VERSION "created by canmatrix"

NS_ :

BS_:

BU_: RadarFrontCenter VideoFrontCenter RadarFrontLeft RadarFrontRight ReceiveECU

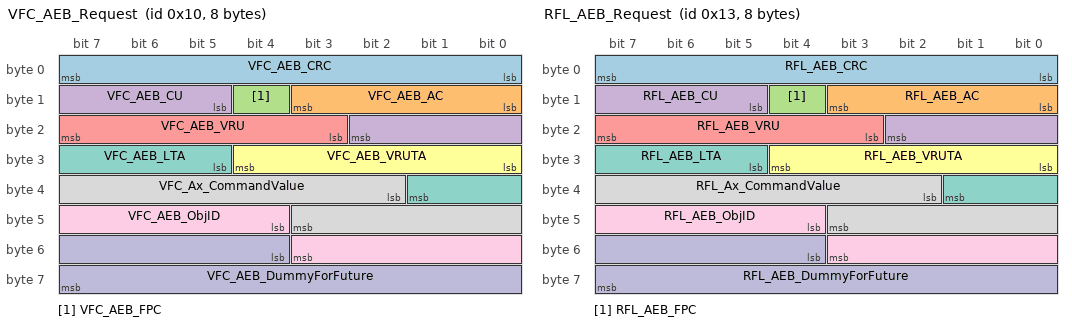
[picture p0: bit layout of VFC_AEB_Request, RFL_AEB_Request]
BO_ 16 VFC_AEB_Request: 8 VideoFrontCenter
 SG_ VFC_AEB_CRC : 0|8@1+ (1,0) [0|255] ""  ReceiveECU
 SG_ VFC_AEB_AC : 8|4@1+ (1,0) [0|15] ""  ReceiveECU
 SG_ VFC_AEB_FPC : 12|1@1+ (1,0) [0|1] ""  ReceiveECU
 SG_ VFC_AEB_CU : 13|6@1+ (1,0) [0|63] ""  ReceiveECU
 SG_ VFC_AEB_VRU : 19|5@1+ (1,0) [0|31] ""  ReceiveECU
 SG_ VFC_AEB_VRUTA : 24|5@1+ (1,0) [0|31] ""  ReceiveECU
 SG_ VFC_AEB_LTA : 29|5@1+ (1,0) [0|31] ""  ReceiveECU
 SG_ VFC_Ax_CommandValue : 34|10@1+ (0.024,-20.016) [-20.016|4.536] "m/s^2"  ReceiveECU
 SG_ VFC_AEB_ObjID : 44|8@1+ (1,0) [0|255] ""  ReceiveECU
 SG_ VFC_AEB_DummyForFuture : 52|12@1+ (1,0) [0|4095] ""  ReceiveECU

BO_ 19 RFL_AEB_Request: 8 RadarFrontLeft
 SG_ RFL_AEB_CRC : 0|8@1+ (1,0) [0|255] ""  VideoFrontCenter
 SG_ RFL_AEB_AC : 8|4@1+ (1,0) [0|15] ""  VideoFrontCenter
 SG_ RFL_AEB_FPC : 12|1@1+ (1,0) [0|1] ""  VideoFrontCenter
 SG_ RFL_AEB_CU : 13|6@1+ (1,0) [0|63] ""  VideoFrontCenter
 SG_ RFL_AEB_VRU : 19|5@1+ (1,0) [0|31] ""  VideoFrontCenter
 SG_ RFL_AEB_VRUTA : 24|5@1+ (1,0) [0|31] ""  VideoFrontCenter
 SG_ RFL_AEB_LTA : 29|5@1+ (1,0) [0|31] ""  VideoFrontCenter
 SG_ RFL_Ax_CommandValue : 34|10@1+ (0.024,-20.016) [-20.016|4.536] "m/s^2"  VideoFrontCenter
 SG_ RFL_AEB_ObjID : 44|8@1+ (1,0) [0|255] ""  VideoFrontCenter
 SG_ RFL_AEB_DummyForFuture : 52|12@1+ (1,0) [0|4095] ""  VideoFrontCenter

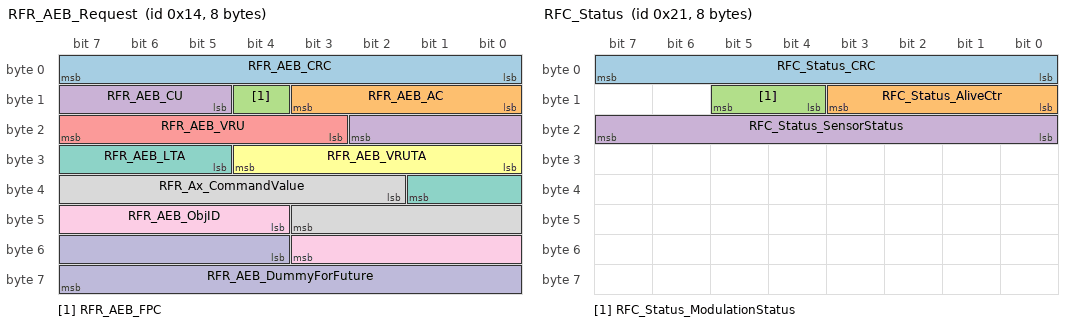
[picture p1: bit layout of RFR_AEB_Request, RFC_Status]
BO_ 20 RFR_AEB_Request: 8 RadarFrontRight
 SG_ RFR_AEB_CRC : 0|8@1+ (1,0) [0|255] ""  VideoFrontCenter
 SG_ RFR_AEB_AC : 8|4@1+ (1,0) [0|15] ""  VideoFrontCenter
 SG_ RFR_AEB_FPC : 12|1@1+ (1,0) [0|1] ""  VideoFrontCenter
 SG_ RFR_AEB_CU : 13|6@1+ (1,0) [0|63] ""  VideoFrontCenter
 SG_ RFR_AEB_VRU : 19|5@1+ (1,0) [0|31] ""  VideoFrontCenter
 SG_ RFR_AEB_VRUTA : 24|5@1+ (1,0) [0|31] ""  VideoFrontCenter
 SG_ RFR_AEB_LTA : 29|5@1+ (1,0) [0|31] ""  VideoFrontCenter
 SG_ RFR_Ax_CommandValue : 34|10@1+ (0.024,-20.016) [-20.016|4.536] "m/s^2"  VideoFrontCenter
 SG_ RFR_AEB_ObjID : 44|8@1+ (1,0) [0|255] ""  VideoFrontCenter
 SG_ RFR_AEB_DummyForFuture : 52|12@1+ (1,0) [0|4095] ""  VideoFrontCenter

BO_ 32 VFC_Status: 20 VideoFrontCenter
 SG_ VFC_Status_CRC : 0|16@1+ (1,0) [0|65535] ""  RadarFrontLeft,RadarFrontRight
 SG_ VFC_Status_AliveCtr : 16|8@1+ (1,0) [0|255] ""  RadarFrontLeft,RadarFrontRight
 SG_ VFC_Status_SensorOrientYaw : 24|10@1+ (0.0005,-0.256) [-0.256|0.2555] "rad"  RadarFrontLeft,RadarFrontRight
 SG_ VFC_Status_SensorOrientPitch : 34|10@1+ (0.0005,-0.256) [-0.256|0.2555] "rad"  RadarFrontLeft,RadarFrontRight
 SG_ VFC_Status_SensorOrientRoll : 44|10@1+ (0.0005,-0.256) [-0.256|0.2555] "rad"  RadarFrontLeft,RadarFrontRight
 SG_ VFC_Status_TimeStampStatus : 56|8@1+ (1,0) [0|255] ""  RadarFrontLeft,RadarFrontRight
 SG_ VFC_Status_TimeStamp : 64|26@1+ (1,0) [0|67108863] "ms"  RadarFrontLeft,RadarFrontRight
 SG_ VFC_Status_FrameNumber : 96|16@1+ (1,0) [0|65535] ""  RadarFrontLeft,RadarFrontRight
 SG_ VFC_Status_SensorOriginPointX : 112|13@1+ (0.001,-4.096) [-4.096|4.095] "m"  RadarFrontLeft,RadarFrontRight
 SG_ VFC_Status_SensorOriginPointY : 125|12@1+ (0.001,-2.048) [-2.048|2.047] "m"  RadarFrontLeft,RadarFrontRight
 SG_ VFC_Status_SensorOriginPointZ : 137|13@1+ (0.001,0) [0|5] "m"  RadarFrontLeft,RadarFrontRight
 SG_ VFC_Status_RollerBenchState : 150|2@1+ (1,0) [0|3] ""  RadarFrontLeft,RadarFrontRight
 SG_ VFC_Status_SensorState : 152|4@1+ (1,0) [0|15] ""  RadarFrontLeft,RadarFrontRight
 SG_ VFC_Status_CalibrationState : 156|3@1+ (1,0) [0|7] ""  RadarFrontLeft,RadarFrontRight
 SG_ VFC_Status_TrafficFlowType : 159|1@1+ (1,0) [0|1] ""  RadarFrontLeft,RadarFrontRight

BO_ 33 RFC_Status: 8 RadarFrontCenter
 SG_ RFC_Status_CRC : 0|8@1+ (1,0) [0|255] ""  VideoFrontCenter,RadarFrontLeft,RadarFrontRight
 SG_ RFC_Status_AliveCtr : 8|4@1+ (1,0) [0|15] ""  VideoFrontCenter,RadarFrontLeft,RadarFrontRight
 SG_ RFC_Status_ModulationStatus : 12|2@1+ (1,0) [0|3] ""  VideoFrontCenter,RadarFrontLeft,RadarFrontRight
 SG_ RFC_Status_SensorStatus : 16|8@1+ (1,0) [0|255] ""  VideoFrontCenter,RadarFrontLeft,RadarFrontRight

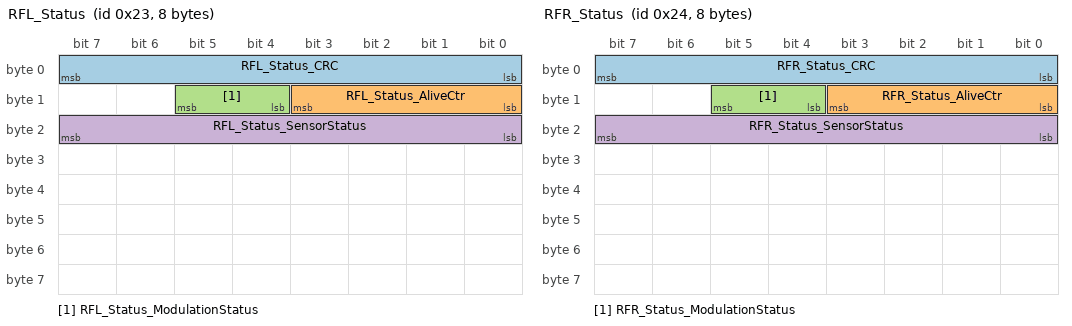
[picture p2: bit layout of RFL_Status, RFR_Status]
BO_ 35 RFL_Status: 8 RadarFrontLeft
 SG_ RFL_Status_CRC : 0|8@1+ (1,0) [0|255] ""  VideoFrontCenter,RadarFrontRight
 SG_ RFL_Status_AliveCtr : 8|4@1+ (1,0) [0|15] ""  VideoFrontCenter,RadarFrontRight
 SG_ RFL_Status_ModulationStatus : 12|2@1+ (1,0) [0|3] ""  VideoFrontCenter,RadarFrontRight
 SG_ RFL_Status_SensorStatus : 16|8@1+ (1,0) [0|255] ""  VideoFrontCenter,RadarFrontRight

BO_ 36 RFR_Status: 8 RadarFrontRight
 SG_ RFR_Status_CRC : 0|8@1+ (1,0) [0|255] ""  VideoFrontCenter,RadarFrontLeft
 SG_ RFR_Status_AliveCtr : 8|4@1+ (1,0) [0|15] ""  VideoFrontCenter,RadarFrontLeft
 SG_ RFR_Status_ModulationStatus : 12|2@1+ (1,0) [0|3] ""  VideoFrontCenter,RadarFrontLeft
 SG_ RFR_Status_SensorStatus : 16|8@1+ (1,0) [0|255] ""  VideoFrontCenter,RadarFrontLeft

BO_ 404 RFC_ObjHdr: 48 RadarFrontCenter
 SG_ RFC_ObjHdr_CRC : 0|16@1+ (1,0) [0|65535] ""  VideoFrontCenter
 SG_ RFC_ObjHdr_AliveCtr : 16|8@1+ (1,0) [0|255] ""  VideoFrontCenter
 SG_ RFC_ObjHdr_ProtBlockCtr : 24|4@1+ (1,0) [0|15] ""  VideoFrontCenter
 SG_ RFC_ObjHdr_IfVersionIdMajor : 32|8@1+ (1,0) [0|255] ""  VideoFrontCenter
 SG_ RFC_ObjHdr_IfVersionIdMinor : 40|8@1+ (1,0) [0|255] ""  VideoFrontCenter
 SG_ RFC_ObjHdr_NumValidObjects : 48|6@1+ (1,0) [0|40] ""  VideoFrontCenter
 SG_ RFC_ObjHdr_TimeStampStatus : 56|8@1+ (1,0) [0|255] ""  VideoFrontCenter
 SG_ RFC_ObjHdr_TimeStamp : 64|26@1+ (1,0) [0|67108863] "ms"  VideoFrontCenter
 SG_ RFC_ObjHdr_SensorState : 96|8@1+ (1,0) [0|255] ""  VideoFrontCenter
 SG_ RFC_ObjHdr_AziOutOfSpec : 109|1@1+ (1,0) [0|1] ""  VideoFrontCenter
 SG_ RFC_ObjHdr_ElevOutOfSpec : 110|1@1+ (1,0) [0|1] ""  VideoFrontCenter
 SG_ RFC_ObjHdr_ObjectDownSel : 111|1@1+ (1,0) [0|1] ""  VideoFrontCenter
 SG_ RFC_ObjHdr_SensorOriginPointY : 112|8@1+ (0.01,-1.28) [-1.28|1.27] "m"  VideoFrontCenter
 SG_ RFC_ObjHdr_SensorOriginPointX : 120|9@1+ (0.02,-5.12) [-5.12|5.1] "m"  VideoFrontCenter
 SG_ RFC_ObjHdr_SensorOriginPointZ : 129|5@1+ (0.05,0) [0|1.55] "m"  VideoFrontCenter
 SG_ RFC_ObjHdr_SensorOrientYaw : 136|16@1+ (0.00017,-5.57056) [-3.2|3.2] "rad"  VideoFrontCenter
 SG_ RFC_ObjHdr_SensorOrientPitch : 152|12@1+ (0.00017,-0.34816) [-0.34816|0.34799] "rad"  VideoFrontCenter
 SG_ RFC_ObjHdr_SensorOrientRoll : 164|12@1+ (0.00017,-0.34816) [-0.2|0.2] "rad"  VideoFrontCenter
 SG_ RFC_ObjHdr_FovAzimuthBegin : 176|15@1+ (0.00017,-2.78528) [-1.6|1.6] "rad"  VideoFrontCenter
 SG_ RFC_ObjHdr_FovAzimuthEnd : 192|15@1+ (0.00017,-2.78528) [-1.6|1.6] "rad"  VideoFrontCenter
 SG_ RFC_ObjHdr_FovElevationBegin : 208|12@1+ (0.00017,-0.34816) [-0.34816|0.34799] "rad"  VideoFrontCenter
 SG_ RFC_ObjHdr_FovElevationEnd : 220|12@1+ (0.00017,-0.34816) [-0.34816|0.34799] "rad"  VideoFrontCenter
 SG_ RFC_ObjHdr_DetectionRange : 232|9@1+ (1,0) [0|511] "m"  VideoFrontCenter
 SG_ RFC_ObjHdr_TimeStampLocal : 248|26@1+ (1,0) [0|67108863] "ms"  VideoFrontCenter

BO_ 406 RFC_Obj00: 64 RadarFrontCenter
 SG_ RFC_Obj00_CRC : 0|16@1+ (1,0) [0|65535] ""  VideoFrontCenter
 SG_ RFC_Obj00_AliveCtr : 16|8@1+ (1,0) [0|255] ""  VideoFrontCenter
 SG_ RFC_Obj00_ProtBlockCtr : 24|4@1+ (1,0) [0|15] ""  VideoFrontCenter
 SG_ RFC_Obj00_ReferencePoint : 28|4@1+ (1,0) [0|15] ""  VideoFrontCenter
 SG_ RFC_Obj00_ObjId : 32|7@1+ (1,0) [0|127] ""  VideoFrontCenter
 SG_ RFC_Obj00_MeasurementStatus : 39|1@1+ (1,0) [0|1] ""  VideoFrontCenter
 SG_ RFC_Obj00_Px : 40|13@1+ (0.0625,-256) [-256|255.9375] "m"  VideoFrontCenter
 SG_ RFC_Obj00_Py : 53|11@1+ (0.125,-128) [-128|127.875] "m"  VideoFrontCenter
 SG_ RFC_Obj00_PxVnce : 64|12@1+ (0.01,0) [0|30] "m^2"  VideoFrontCenter
 SG_ RFC_Obj00_PyVnce : 76|12@1+ (0.01,0) [0|30] "m^2"  VideoFrontCenter
 SG_ RFC_Obj00_Vx : 88|12@1+ (0.0625,-128) [-128|127.9375] "m/s"  VideoFrontCenter
 SG_ RFC_Obj00_Vy : 100|10@1+ (0.125,-64) [-64|63.875] "m/s"  VideoFrontCenter
 SG_ RFC_Obj00_Ax : 110|10@1+ (0.03125,-16) [-16|15.96875] "m/s^2"  VideoFrontCenter
 SG_ RFC_Obj00_Ay : 120|9@1+ (0.0625,-16) [-16|15.9375] "m/s^2"  VideoFrontCenter
 SG_ RFC_Obj00_OrientationYaw : 129|9@1+ (0.0175,-4.48) [-3.15|3.15] "rad"  VideoFrontCenter
 SG_ RFC_Obj00_ExistProb : 138|6@1+ (2,0) [0|100] "%"  VideoFrontCenter
 SG_ RFC_Obj00_VxVnce : 144|12@1+ (0.01,0) [0|30] "m^2/s^2"  VideoFrontCenter
 SG_ RFC_Obj00_VyVnce : 156|12@1+ (0.01,0) [0|30] "m^2/s^2"  VideoFrontCenter
 SG_ RFC_Obj00_AxVnce : 168|12@1+ (0.01,0) [0|30] "m^2/s^4"  VideoFrontCenter
 SG_ RFC_Obj00_AyVnce : 180|12@1+ (0.01,0) [0|30] "m^2/s^4"  VideoFrontCenter
 SG_ RFC_Obj00_OrientationYawVnce : 192|12@1+ (0.0003,0) [0|1] "rad^2"  VideoFrontCenter
 SG_ RFC_Obj00_MovingObserved : 204|6@1+ (2,0) [0|100] "%"  VideoFrontCenter
 SG_ RFC_Obj00_MovingProbability : 210|6@1+ (2,0) [0|100] "%"  VideoFrontCenter
 SG_ RFC_Obj00_Length : 216|7@1+ (0.125,0) [0|15.875] "m"  VideoFrontCenter
 SG_ RFC_Obj00_Valid : 223|1@1+ (1,0) [0|1] ""  VideoFrontCenter
 SG_ RFC_Obj00_LengthVnce : 224|12@1+ (0.01,0) [0|30] "m^2"  VideoFrontCenter
 SG_ RFC_Obj00_WidthVnce : 236|12@1+ (0.01,0) [0|30] "m^2"  VideoFrontCenter
 SG_ RFC_Obj00_Width : 248|7@1+ (0.125,0) [0|15.875] "m"  VideoFrontCenter
 SG_ RFC_Obj00_BehaviorType : 255|3@1+ (1,0) [0|7] ""  VideoFrontCenter
 SG_ RFC_Obj00_ObstacleConf : 258|6@1+ (2,0) [0|100] "%"  VideoFrontCenter
 SG_ RFC_Obj00_NonObstacleConf : 264|6@1+ (2,0) [0|100] "%"  VideoFrontCenter
 SG_ RFC_Obj00_PxPyCoVnce : 272|12@1+ (0.01,0) [0|30] "m^2"  VideoFrontCenter
 SG_ RFC_Obj00_PxVxCoVnce : 284|12@1+ (0.01,0) [0|30] "m^2/s"  VideoFrontCenter
 SG_ RFC_Obj00_PxVyCoVnce : 296|12@1+ (0.01,0) [0|30] "m^2/s"  VideoFrontCenter
 SG_ RFC_Obj00_PyVxCoVnce : 308|12@1+ (0.01,0) [0|30] "m^2/s"  VideoFrontCenter
 SG_ RFC_Obj00_PyVyCoVnce : 320|12@1+ (0.01,0) [0|30] "m^2/s"  VideoFrontCenter
 SG_ RFC_Obj00_VxVyCoVnce : 332|12@1+ (0.01,0) [0|30] "m^2/s^2"  VideoFrontCenter
 SG_ RFC_Obj00_PxAxCoVnce : 344|12@1+ (0.01,0) [0|30] "m^2/s^2"  VideoFrontCenter
 SG_ RFC_Obj00_PxAyCoVnce : 356|12@1+ (0.01,0) [0|30] "m^2/s^2"  VideoFrontCenter
 SG_ RFC_Obj00_PyAxCoVnce : 368|12@1+ (0.01,0) [0|30] "m^2/s^2"  VideoFrontCenter
 SG_ RFC_Obj00_PyAyCoVnce : 380|12@1+ (0.01,0) [0|30] "m^2/s^2"  VideoFrontCenter
 SG_ RFC_Obj00_VxAxCoVnce : 392|12@1+ (0.01,0) [0|30] "m^2/s^3"  VideoFrontCenter
 SG_ RFC_Obj00_VxAyCoVnce : 404|12@1+ (0.01,0) [0|30] "m^2/s^3"  VideoFrontCenter
 SG_ RFC_Obj00_VyAxCoVnce : 416|12@1+ (0.01,0) [0|30] "m^2/s^3"  VideoFrontCenter
 SG_ RFC_Obj00_VyAyCoVnce : 428|12@1+ (0.01,0) [0|30] "m^2/s^3"  VideoFrontCenter
 SG_ RFC_Obj00_AxAyCoVnce : 440|12@1+ (0.01,0) [0|30] "m^2/s^4"  VideoFrontCenter
 SG_ RFC_Obj00_MobileObstConf : 452|6@1+ (2,0) [0|100] "%"  VideoFrontCenter
 SG_ RFC_Obj00_Mob4PlusWhlConf : 458|6@1+ (2,0) [0|100] "%"  VideoFrontCenter
 SG_ RFC_Obj00_Mob2WhlConf : 464|6@1+ (2,0) [0|100] "%"  VideoFrontCenter
 SG_ RFC_Obj00_MobPedConf : 470|6@1+ (2,0) [0|100] "%"  VideoFrontCenter
 SG_ RFC_Obj00_FourPlusWhlCarConf : 476|6@1+ (2,0) [0|100] "%"  VideoFrontCenter
 SG_ RFC_Obj00_FourPlusWhlHGVConf : 482|6@1+ (2,0) [0|100] "%"  VideoFrontCenter
 SG_ RFC_Obj00_GroundReflexConf : 488|6@1+ (2,0) [0|100] "%"  VideoFrontCenter
 SG_ RFC_Obj00_StatObstConf : 494|6@1+ (2,0) [0|100] "%"  VideoFrontCenter
 SG_ RFC_Obj00_StatBarrierConf : 500|6@1+ (2,0) [0|100] "%"  VideoFrontCenter

BO_ 407 RFC_Obj01: 64 RadarFrontCenter
 SG_ RFC_Obj01_CRC : 0|16@1+ (1,0) [0|65535] ""  VideoFrontCenter
 SG_ RFC_Obj01_AliveCtr : 16|8@1+ (1,0) [0|255] ""  VideoFrontCenter
 SG_ RFC_Obj01_ProtBlockCtr : 24|4@1+ (1,0) [0|15] ""  VideoFrontCenter
 SG_ RFC_Obj01_ReferencePoint : 28|4@1+ (1,0) [0|15] ""  VideoFrontCenter
 SG_ RFC_Obj01_ObjId : 32|7@1+ (1,0) [0|127] ""  VideoFrontCenter
 SG_ RFC_Obj01_MeasurementStatus : 39|1@1+ (1,0) [0|1] ""  VideoFrontCenter
 SG_ RFC_Obj01_Px : 40|13@1+ (0.0625,-256) [-256|255.9375] "m"  VideoFrontCenter
 SG_ RFC_Obj01_Py : 53|11@1+ (0.125,-128) [-128|127.875] "m"  VideoFrontCenter
 SG_ RFC_Obj01_PxVnce : 64|12@1+ (0.01,0) [0|30] "m^2"  VideoFrontCenter
 SG_ RFC_Obj01_PyVnce : 76|12@1+ (0.01,0) [0|30] "m^2"  VideoFrontCenter
 SG_ RFC_Obj01_Vx : 88|12@1+ (0.0625,-128) [-128|127.9375] "m/s"  VideoFrontCenter
 SG_ RFC_Obj01_Vy : 100|10@1+ (0.125,-64) [-64|63.875] "m/s"  VideoFrontCenter
 SG_ RFC_Obj01_Ax : 110|10@1+ (0.03125,-16) [-16|15.96875] "m/s^2"  VideoFrontCenter
 SG_ RFC_Obj01_Ay : 120|9@1+ (0.0625,-16) [-16|15.9375] "m/s^2"  VideoFrontCenter
 SG_ RFC_Obj01_OrientationYaw : 129|9@1+ (0.0175,-4.48) [-3.15|3.15] "rad"  VideoFrontCenter
 SG_ RFC_Obj01_ExistProb : 138|6@1+ (2,0) [0|100] "%"  VideoFrontCenter
 SG_ RFC_Obj01_VxVnce : 144|12@1+ (0.01,0) [0|30] "m^2/s^2"  VideoFrontCenter
 SG_ RFC_Obj01_VyVnce : 156|12@1+ (0.01,0) [0|30] "m^2/s^2"  VideoFrontCenter
 SG_ RFC_Obj01_AxVnce : 168|12@1+ (0.01,0) [0|30] "m^2/s^4"  VideoFrontCenter
 SG_ RFC_Obj01_AyVnce : 180|12@1+ (0.01,0) [0|30] "m^2/s^4"  VideoFrontCenter
 SG_ RFC_Obj01_OrientationYawVnce : 192|12@1+ (0.0003,0) [0|1] "rad^2"  VideoFrontCenter
 SG_ RFC_Obj01_MovingObserved : 204|6@1+ (2,0) [0|100] "%"  VideoFrontCenter
 SG_ RFC_Obj01_MovingProbability : 210|6@1+ (2,0) [0|100] "%"  VideoFrontCenter
 SG_ RFC_Obj01_Length : 216|7@1+ (0.125,0) [0|15.875] "m"  VideoFrontCenter
 SG_ RFC_Obj01_Valid : 223|1@1+ (1,0) [0|1] ""  VideoFrontCenter
 SG_ RFC_Obj01_LengthVnce : 224|12@1+ (0.01,0) [0|30] "m^2"  VideoFrontCenter
 SG_ RFC_Obj01_WidthVnce : 236|12@1+ (0.01,0) [0|30] "m^2"  VideoFrontCenter
 SG_ RFC_Obj01_Width : 248|7@1+ (0.125,0) [0|15.875] "m"  VideoFrontCenter
 SG_ RFC_Obj01_BehaviorType : 255|3@1+ (1,0) [0|7] ""  VideoFrontCenter
 SG_ RFC_Obj01_ObstacleConf : 258|6@1+ (2,0) [0|100] "%"  VideoFrontCenter
 SG_ RFC_Obj01_NonObstacleConf : 264|6@1+ (2,0) [0|100] "%"  VideoFrontCenter
 SG_ RFC_Obj01_PxPyCoVnce : 272|12@1+ (0.01,0) [0|30] "m^2"  VideoFrontCenter
 SG_ RFC_Obj01_PxVxCoVnce : 284|12@1+ (0.01,0) [0|30] "m^2/s"  VideoFrontCenter
 SG_ RFC_Obj01_PxVyCoVnce : 296|12@1+ (0.01,0) [0|30] "m^2/s"  VideoFrontCenter
 SG_ RFC_Obj01_PyVxCoVnce : 308|12@1+ (0.01,0) [0|30] "m^2/s"  VideoFrontCenter
 SG_ RFC_Obj01_PyVyCoVnce : 320|12@1+ (0.01,0) [0|30] "m^2/s"  VideoFrontCenter
 SG_ RFC_Obj01_VxVyCoVnce : 332|12@1+ (0.01,0) [0|30] "m^2/s^2"  VideoFrontCenter
 SG_ RFC_Obj01_PxAxCoVnce : 344|12@1+ (0.01,0) [0|30] "m^2/s^2"  VideoFrontCenter
 SG_ RFC_Obj01_PxAyCoVnce : 356|12@1+ (0.01,0) [0|30] "m^2/s^2"  VideoFrontCenter
 SG_ RFC_Obj01_PyAxCoVnce : 368|12@1+ (0.01,0) [0|30] "m^2/s^2"  VideoFrontCenter
 SG_ RFC_Obj01_PyAyCoVnce : 380|12@1+ (0.01,0) [0|30] "m^2/s^2"  VideoFrontCenter
 SG_ RFC_Obj01_VxAxCoVnce : 392|12@1+ (0.01,0) [0|30] "m^2/s^3"  VideoFrontCenter
 SG_ RFC_Obj01_VxAyCoVnce : 404|12@1+ (0.01,0) [0|30] "m^2/s^3"  VideoFrontCenter
 SG_ RFC_Obj01_VyAxCoVnce : 416|12@1+ (0.01,0) [0|30] "m^2/s^3"  VideoFrontCenter
 SG_ RFC_Obj01_VyAyCoVnce : 428|12@1+ (0.01,0) [0|30] "m^2/s^3"  VideoFrontCenter
 SG_ RFC_Obj01_AxAyCoVnce : 440|12@1+ (0.01,0) [0|30] "m^2/s^4"  VideoFrontCenter
 SG_ RFC_Obj01_MobileObstConf : 452|6@1+ (2,0) [0|100] "%"  VideoFrontCenter
 SG_ RFC_Obj01_Mob4PlusWhlConf : 458|6@1+ (2,0) [0|100] "%"  VideoFrontCenter
 SG_ RFC_Obj01_Mob2WhlConf : 464|6@1+ (2,0) [0|100] "%"  VideoFrontCenter
 SG_ RFC_Obj01_MobPedConf : 470|6@1+ (2,0) [0|100] "%"  VideoFrontCenter
 SG_ RFC_Obj01_FourPlusWhlCarConf : 476|6@1+ (2,0) [0|100] "%"  VideoFrontCenter
 SG_ RFC_Obj01_FourPlusWhlHGVConf : 482|6@1+ (2,0) [0|100] "%"  VideoFrontCenter
 SG_ RFC_Obj01_GroundReflexConf : 488|6@1+ (2,0) [0|100] "%"  VideoFrontCenter
 SG_ RFC_Obj01_StatObstConf : 494|6@1+ (2,0) [0|100] "%"  VideoFrontCenter
 SG_ RFC_Obj01_StatBarrierConf : 500|6@1+ (2,0) [0|100] "%"  VideoFrontCenter

BO_ 408 RFC_Obj02: 64 RadarFrontCenter
 SG_ RFC_Obj02_CRC : 0|16@1+ (1,0) [0|65535] ""  VideoFrontCenter
 SG_ RFC_Obj02_AliveCtr : 16|8@1+ (1,0) [0|255] ""  VideoFrontCenter
 SG_ RFC_Obj02_ProtBlockCtr : 24|4@1+ (1,0) [0|15] ""  VideoFrontCenter
 SG_ RFC_Obj02_ReferencePoint : 28|4@1+ (1,0) [0|15] ""  VideoFrontCenter
 SG_ RFC_Obj02_ObjId : 32|7@1+ (1,0) [0|127] ""  VideoFrontCenter
 SG_ RFC_Obj02_MeasurementStatus : 39|1@1+ (1,0) [0|1] ""  VideoFrontCenter
 SG_ RFC_Obj02_Px : 40|13@1+ (0.0625,-256) [-256|255.9375] "m"  VideoFrontCenter
 SG_ RFC_Obj02_Py : 53|11@1+ (0.125,-128) [-128|127.875] "m"  VideoFrontCenter
 SG_ RFC_Obj02_PxVnce : 64|12@1+ (0.01,0) [0|30] "m^2"  VideoFrontCenter
 SG_ RFC_Obj02_PyVnce : 76|12@1+ (0.01,0) [0|30] "m^2"  VideoFrontCenter
 SG_ RFC_Obj02_Vx : 88|12@1+ (0.0625,-128) [-128|127.9375] "m/s"  VideoFrontCenter
 SG_ RFC_Obj02_Vy : 100|10@1+ (0.125,-64) [-64|63.875] "m/s"  VideoFrontCenter
 SG_ RFC_Obj02_Ax : 110|10@1+ (0.03125,-16) [-16|15.96875] "m/s^2"  VideoFrontCenter
 SG_ RFC_Obj02_Ay : 120|9@1+ (0.0625,-16) [-16|15.9375] "m/s^2"  VideoFrontCenter
 SG_ RFC_Obj02_OrientationYaw : 129|9@1+ (0.0175,-4.48) [-3.15|3.15] "rad"  VideoFrontCenter
 SG_ RFC_Obj02_ExistProb : 138|6@1+ (2,0) [0|100] "%"  VideoFrontCenter
 SG_ RFC_Obj02_VxVnce : 144|12@1+ (0.01,0) [0|30] "m^2/s^2"  VideoFrontCenter
 SG_ RFC_Obj02_VyVnce : 156|12@1+ (0.01,0) [0|30] "m^2/s^2"  VideoFrontCenter
 SG_ RFC_Obj02_AxVnce : 168|12@1+ (0.01,0) [0|30] "m^2/s^4"  VideoFrontCenter
 SG_ RFC_Obj02_AyVnce : 180|12@1+ (0.01,0) [0|30] "m^2/s^4"  VideoFrontCenter
 SG_ RFC_Obj02_OrientationYawVnce : 192|12@1+ (0.0003,0) [0|1] "rad^2"  VideoFrontCenter
 SG_ RFC_Obj02_MovingObserved : 204|6@1+ (2,0) [0|100] "%"  VideoFrontCenter
 SG_ RFC_Obj02_MovingProbability : 210|6@1+ (2,0) [0|100] "%"  VideoFrontCenter
 SG_ RFC_Obj02_Length : 216|7@1+ (0.125,0) [0|15.875] "m"  VideoFrontCenter
 SG_ RFC_Obj02_Valid : 223|1@1+ (1,0) [0|1] ""  VideoFrontCenter
 SG_ RFC_Obj02_LengthVnce : 224|12@1+ (0.01,0) [0|30] "m^2"  VideoFrontCenter
 SG_ RFC_Obj02_WidthVnce : 236|12@1+ (0.01,0) [0|30] "m^2"  VideoFrontCenter
 SG_ RFC_Obj02_Width : 248|7@1+ (0.125,0) [0|15.875] "m"  VideoFrontCenter
 SG_ RFC_Obj02_BehaviorType : 255|3@1+ (1,0) [0|7] ""  VideoFrontCenter
 SG_ RFC_Obj02_ObstacleConf : 258|6@1+ (2,0) [0|100] "%"  VideoFrontCenter
 SG_ RFC_Obj02_NonObstacleConf : 264|6@1+ (2,0) [0|100] "%"  VideoFrontCenter
 SG_ RFC_Obj02_PxPyCoVnce : 272|12@1+ (0.01,0) [0|30] "m^2"  VideoFrontCenter
 SG_ RFC_Obj02_PxVxCoVnce : 284|12@1+ (0.01,0) [0|30] "m^2/s"  VideoFrontCenter
 SG_ RFC_Obj02_PxVyCoVnce : 296|12@1+ (0.01,0) [0|30] "m^2/s"  VideoFrontCenter
 SG_ RFC_Obj02_PyVxCoVnce : 308|12@1+ (0.01,0) [0|30] "m^2/s"  VideoFrontCenter
 SG_ RFC_Obj02_PyVyCoVnce : 320|12@1+ (0.01,0) [0|30] "m^2/s"  VideoFrontCenter
 SG_ RFC_Obj02_VxVyCoVnce : 332|12@1+ (0.01,0) [0|30] "m^2/s^2"  VideoFrontCenter
 SG_ RFC_Obj02_PxAxCoVnce : 344|12@1+ (0.01,0) [0|30] "m^2/s^2"  VideoFrontCenter
 SG_ RFC_Obj02_PxAyCoVnce : 356|12@1+ (0.01,0) [0|30] "m^2/s^2"  VideoFrontCenter
 SG_ RFC_Obj02_PyAxCoVnce : 368|12@1+ (0.01,0) [0|30] "m^2/s^2"  VideoFrontCenter
 SG_ RFC_Obj02_PyAyCoVnce : 380|12@1+ (0.01,0) [0|30] "m^2/s^2"  VideoFrontCenter
 SG_ RFC_Obj02_VxAxCoVnce : 392|12@1+ (0.01,0) [0|30] "m^2/s^3"  VideoFrontCenter
 SG_ RFC_Obj02_VxAyCoVnce : 404|12@1+ (0.01,0) [0|30] "m^2/s^3"  VideoFrontCenter
 SG_ RFC_Obj02_VyAxCoVnce : 416|12@1+ (0.01,0) [0|30] "m^2/s^3"  VideoFrontCenter
 SG_ RFC_Obj02_VyAyCoVnce : 428|12@1+ (0.01,0) [0|30] "m^2/s^3"  VideoFrontCenter
 SG_ RFC_Obj02_AxAyCoVnce : 440|12@1+ (0.01,0) [0|30] "m^2/s^4"  VideoFrontCenter
 SG_ RFC_Obj02_MobileObstConf : 452|6@1+ (2,0) [0|100] "%"  VideoFrontCenter
 SG_ RFC_Obj02_Mob4PlusWhlConf : 458|6@1+ (2,0) [0|100] "%"  VideoFrontCenter
 SG_ RFC_Obj02_Mob2WhlConf : 464|6@1+ (2,0) [0|100] "%"  VideoFrontCenter
 SG_ RFC_Obj02_MobPedConf : 470|6@1+ (2,0) [0|100] "%"  VideoFrontCenter
 SG_ RFC_Obj02_FourPlusWhlCarConf : 476|6@1+ (2,0) [0|100] "%"  VideoFrontCenter
 SG_ RFC_Obj02_FourPlusWhlHGVConf : 482|6@1+ (2,0) [0|100] "%"  VideoFrontCenter
 SG_ RFC_Obj02_GroundReflexConf : 488|6@1+ (2,0) [0|100] "%"  VideoFrontCenter
 SG_ RFC_Obj02_StatObstConf : 494|6@1+ (2,0) [0|100] "%"  VideoFrontCenter
 SG_ RFC_Obj02_StatBarrierConf : 500|6@1+ (2,0) [0|100] "%"  VideoFrontCenter

BO_ 409 RFC_Obj03: 64 RadarFrontCenter
 SG_ RFC_Obj03_CRC : 0|16@1+ (1,0) [0|65535] ""  VideoFrontCenter
 SG_ RFC_Obj03_AliveCtr : 16|8@1+ (1,0) [0|255] ""  VideoFrontCenter
 SG_ RFC_Obj03_ProtBlockCtr : 24|4@1+ (1,0) [0|15] ""  VideoFrontCenter
 SG_ RFC_Obj03_ReferencePoint : 28|4@1+ (1,0) [0|15] ""  VideoFrontCenter
 SG_ RFC_Obj03_ObjId : 32|7@1+ (1,0) [0|127] ""  VideoFrontCenter
 SG_ RFC_Obj03_MeasurementStatus : 39|1@1+ (1,0) [0|1] ""  VideoFrontCenter
 SG_ RFC_Obj03_Px : 40|13@1+ (0.0625,-256) [-256|255.9375] "m"  VideoFrontCenter
 SG_ RFC_Obj03_Py : 53|11@1+ (0.125,-128) [-128|127.875] "m"  VideoFrontCenter
 SG_ RFC_Obj03_PxVnce : 64|12@1+ (0.01,0) [0|30] "m^2"  VideoFrontCenter
 SG_ RFC_Obj03_PyVnce : 76|12@1+ (0.01,0) [0|30] "m^2"  VideoFrontCenter
 SG_ RFC_Obj03_Vx : 88|12@1+ (0.0625,-128) [-128|127.9375] "m/s"  VideoFrontCenter
 SG_ RFC_Obj03_Vy : 100|10@1+ (0.125,-64) [-64|63.875] "m/s"  VideoFrontCenter
 SG_ RFC_Obj03_Ax : 110|10@1+ (0.03125,-16) [-16|15.96875] "m/s^2"  VideoFrontCenter
 SG_ RFC_Obj03_Ay : 120|9@1+ (0.0625,-16) [-16|15.9375] "m/s^2"  VideoFrontCenter
 SG_ RFC_Obj03_OrientationYaw : 129|9@1+ (0.0175,-4.48) [-3.15|3.15] "rad"  VideoFrontCenter
 SG_ RFC_Obj03_ExistProb : 138|6@1+ (2,0) [0|100] "%"  VideoFrontCenter
 SG_ RFC_Obj03_VxVnce : 144|12@1+ (0.01,0) [0|30] "m^2/s^2"  VideoFrontCenter
 SG_ RFC_Obj03_VyVnce : 156|12@1+ (0.01,0) [0|30] "m^2/s^2"  VideoFrontCenter
 SG_ RFC_Obj03_AxVnce : 168|12@1+ (0.01,0) [0|30] "m^2/s^4"  VideoFrontCenter
 SG_ RFC_Obj03_AyVnce : 180|12@1+ (0.01,0) [0|30] "m^2/s^4"  VideoFrontCenter
 SG_ RFC_Obj03_OrientationYawVnce : 192|12@1+ (0.0003,0) [0|1] "rad^2"  VideoFrontCenter
 SG_ RFC_Obj03_MovingObserved : 204|6@1+ (2,0) [0|100] "%"  VideoFrontCenter
 SG_ RFC_Obj03_MovingProbability : 210|6@1+ (2,0) [0|100] "%"  VideoFrontCenter
 SG_ RFC_Obj03_Length : 216|7@1+ (0.125,0) [0|15.875] "m"  VideoFrontCenter
 SG_ RFC_Obj03_Valid : 223|1@1+ (1,0) [0|1] ""  VideoFrontCenter
 SG_ RFC_Obj03_LengthVnce : 224|12@1+ (0.01,0) [0|30] "m^2"  VideoFrontCenter
 SG_ RFC_Obj03_WidthVnce : 236|12@1+ (0.01,0) [0|30] "m^2"  VideoFrontCenter
 SG_ RFC_Obj03_Width : 248|7@1+ (0.125,0) [0|15.875] "m"  VideoFrontCenter
 SG_ RFC_Obj03_BehaviorType : 255|3@1+ (1,0) [0|7] ""  VideoFrontCenter
 SG_ RFC_Obj03_ObstacleConf : 258|6@1+ (2,0) [0|100] "%"  VideoFrontCenter
 SG_ RFC_Obj03_NonObstacleConf : 264|6@1+ (2,0) [0|100] "%"  VideoFrontCenter
 SG_ RFC_Obj03_PxPyCoVnce : 272|12@1+ (0.01,0) [0|30] "m^2"  VideoFrontCenter
 SG_ RFC_Obj03_PxVxCoVnce : 284|12@1+ (0.01,0) [0|30] "m^2/s"  VideoFrontCenter
 SG_ RFC_Obj03_PxVyCoVnce : 296|12@1+ (0.01,0) [0|30] "m^2/s"  VideoFrontCenter
 SG_ RFC_Obj03_PyVxCoVnce : 308|12@1+ (0.01,0) [0|30] "m^2/s"  VideoFrontCenter
 SG_ RFC_Obj03_PyVyCoVnce : 320|12@1+ (0.01,0) [0|30] "m^2/s"  VideoFrontCenter
 SG_ RFC_Obj03_VxVyCoVnce : 332|12@1+ (0.01,0) [0|30] "m^2/s^2"  VideoFrontCenter
 SG_ RFC_Obj03_PxAxCoVnce : 344|12@1+ (0.01,0) [0|30] "m^2/s^2"  VideoFrontCenter
 SG_ RFC_Obj03_PxAyCoVnce : 356|12@1+ (0.01,0) [0|30] "m^2/s^2"  VideoFrontCenter
 SG_ RFC_Obj03_PyAxCoVnce : 368|12@1+ (0.01,0) [0|30] "m^2/s^2"  VideoFrontCenter
 SG_ RFC_Obj03_PyAyCoVnce : 380|12@1+ (0.01,0) [0|30] "m^2/s^2"  VideoFrontCenter
 SG_ RFC_Obj03_VxAxCoVnce : 392|12@1+ (0.01,0) [0|30] "m^2/s^3"  VideoFrontCenter
 SG_ RFC_Obj03_VxAyCoVnce : 404|12@1+ (0.01,0) [0|30] "m^2/s^3"  VideoFrontCenter
 SG_ RFC_Obj03_VyAxCoVnce : 416|12@1+ (0.01,0) [0|30] "m^2/s^3"  VideoFrontCenter
 SG_ RFC_Obj03_VyAyCoVnce : 428|12@1+ (0.01,0) [0|30] "m^2/s^3"  VideoFrontCenter
 SG_ RFC_Obj03_AxAyCoVnce : 440|12@1+ (0.01,0) [0|30] "m^2/s^4"  VideoFrontCenter
 SG_ RFC_Obj03_MobileObstConf : 452|6@1+ (2,0) [0|100] "%"  VideoFrontCenter
 SG_ RFC_Obj03_Mob4PlusWhlConf : 458|6@1+ (2,0) [0|100] "%"  VideoFrontCenter
 SG_ RFC_Obj03_Mob2WhlConf : 464|6@1+ (2,0) [0|100] "%"  VideoFrontCenter
 SG_ RFC_Obj03_MobPedConf : 470|6@1+ (2,0) [0|100] "%"  VideoFrontCenter
 SG_ RFC_Obj03_FourPlusWhlCarConf : 476|6@1+ (2,0) [0|100] "%"  VideoFrontCenter
 SG_ RFC_Obj03_FourPlusWhlHGVConf : 482|6@1+ (2,0) [0|100] "%"  VideoFrontCenter
 SG_ RFC_Obj03_GroundReflexConf : 488|6@1+ (2,0) [0|100] "%"  VideoFrontCenter
 SG_ RFC_Obj03_StatObstConf : 494|6@1+ (2,0) [0|100] "%"  VideoFrontCenter
 SG_ RFC_Obj03_StatBarrierConf : 500|6@1+ (2,0) [0|100] "%"  VideoFrontCenter

BO_ 410 RFC_Obj04: 64 RadarFrontCenter
 SG_ RFC_Obj04_CRC : 0|16@1+ (1,0) [0|65535] ""  VideoFrontCenter
 SG_ RFC_Obj04_AliveCtr : 16|8@1+ (1,0) [0|255] ""  VideoFrontCenter
 SG_ RFC_Obj04_ProtBlockCtr : 24|4@1+ (1,0) [0|15] ""  VideoFrontCenter
 SG_ RFC_Obj04_ReferencePoint : 28|4@1+ (1,0) [0|15] ""  VideoFrontCenter
 SG_ RFC_Obj04_ObjId : 32|7@1+ (1,0) [0|127] ""  VideoFrontCenter
 SG_ RFC_Obj04_MeasurementStatus : 39|1@1+ (1,0) [0|1] ""  VideoFrontCenter
 SG_ RFC_Obj04_Px : 40|13@1+ (0.0625,-256) [-256|255.9375] "m"  VideoFrontCenter
 SG_ RFC_Obj04_Py : 53|11@1+ (0.125,-128) [-128|127.875] "m"  VideoFrontCenter
 SG_ RFC_Obj04_PxVnce : 64|12@1+ (0.01,0) [0|30] "m^2"  VideoFrontCenter
 SG_ RFC_Obj04_PyVnce : 76|12@1+ (0.01,0) [0|30] "m^2"  VideoFrontCenter
 SG_ RFC_Obj04_Vx : 88|12@1+ (0.0625,-128) [-128|127.9375] "m/s"  VideoFrontCenter
 SG_ RFC_Obj04_Vy : 100|10@1+ (0.125,-64) [-64|63.875] "m/s"  VideoFrontCenter
 SG_ RFC_Obj04_Ax : 110|10@1+ (0.03125,-16) [-16|15.96875] "m/s^2"  VideoFrontCenter
 SG_ RFC_Obj04_Ay : 120|9@1+ (0.0625,-16) [-16|15.9375] "m/s^2"  VideoFrontCenter
 SG_ RFC_Obj04_OrientationYaw : 129|9@1+ (0.0175,-4.48) [-3.15|3.15] "rad"  VideoFrontCenter
 SG_ RFC_Obj04_ExistProb : 138|6@1+ (2,0) [0|100] "%"  VideoFrontCenter
 SG_ RFC_Obj04_VxVnce : 144|12@1+ (0.01,0) [0|30] "m^2/s^2"  VideoFrontCenter
 SG_ RFC_Obj04_VyVnce : 156|12@1+ (0.01,0) [0|30] "m^2/s^2"  VideoFrontCenter
 SG_ RFC_Obj04_AxVnce : 168|12@1+ (0.01,0) [0|30] "m^2/s^4"  VideoFrontCenter
 SG_ RFC_Obj04_AyVnce : 180|12@1+ (0.01,0) [0|30] "m^2/s^4"  VideoFrontCenter
 SG_ RFC_Obj04_OrientationYawVnce : 192|12@1+ (0.0003,0) [0|1] "rad^2"  VideoFrontCenter
 SG_ RFC_Obj04_MovingObserved : 204|6@1+ (2,0) [0|100] "%"  VideoFrontCenter
 SG_ RFC_Obj04_MovingProbability : 210|6@1+ (2,0) [0|100] "%"  VideoFrontCenter
 SG_ RFC_Obj04_Length : 216|7@1+ (0.125,0) [0|15.875] "m"  VideoFrontCenter
 SG_ RFC_Obj04_Valid : 223|1@1+ (1,0) [0|1] ""  VideoFrontCenter
 SG_ RFC_Obj04_LengthVnce : 224|12@1+ (0.01,0) [0|30] "m^2"  VideoFrontCenter
 SG_ RFC_Obj04_WidthVnce : 236|12@1+ (0.01,0) [0|30] "m^2"  VideoFrontCenter
 SG_ RFC_Obj04_Width : 248|7@1+ (0.125,0) [0|15.875] "m"  VideoFrontCenter
 SG_ RFC_Obj04_BehaviorType : 255|3@1+ (1,0) [0|7] ""  VideoFrontCenter
 SG_ RFC_Obj04_ObstacleConf : 258|6@1+ (2,0) [0|100] "%"  VideoFrontCenter
 SG_ RFC_Obj04_NonObstacleConf : 264|6@1+ (2,0) [0|100] "%"  VideoFrontCenter
 SG_ RFC_Obj04_PxPyCoVnce : 272|12@1+ (0.01,0) [0|30] "m^2"  VideoFrontCenter
 SG_ RFC_Obj04_PxVxCoVnce : 284|12@1+ (0.01,0) [0|30] "m^2/s"  VideoFrontCenter
 SG_ RFC_Obj04_PxVyCoVnce : 296|12@1+ (0.01,0) [0|30] "m^2/s"  VideoFrontCenter
 SG_ RFC_Obj04_PyVxCoVnce : 308|12@1+ (0.01,0) [0|30] "m^2/s"  VideoFrontCenter
 SG_ RFC_Obj04_PyVyCoVnce : 320|12@1+ (0.01,0) [0|30] "m^2/s"  VideoFrontCenter
 SG_ RFC_Obj04_VxVyCoVnce : 332|12@1+ (0.01,0) [0|30] "m^2/s^2"  VideoFrontCenter
 SG_ RFC_Obj04_PxAxCoVnce : 344|12@1+ (0.01,0) [0|30] "m^2/s^2"  VideoFrontCenter
 SG_ RFC_Obj04_PxAyCoVnce : 356|12@1+ (0.01,0) [0|30] "m^2/s^2"  VideoFrontCenter
 SG_ RFC_Obj04_PyAxCoVnce : 368|12@1+ (0.01,0) [0|30] "m^2/s^2"  VideoFrontCenter
 SG_ RFC_Obj04_PyAyCoVnce : 380|12@1+ (0.01,0) [0|30] "m^2/s^2"  VideoFrontCenter
 SG_ RFC_Obj04_VxAxCoVnce : 392|12@1+ (0.01,0) [0|30] "m^2/s^3"  VideoFrontCenter
 SG_ RFC_Obj04_VxAyCoVnce : 404|12@1+ (0.01,0) [0|30] "m^2/s^3"  VideoFrontCenter
 SG_ RFC_Obj04_VyAxCoVnce : 416|12@1+ (0.01,0) [0|30] "m^2/s^3"  VideoFrontCenter
 SG_ RFC_Obj04_VyAyCoVnce : 428|12@1+ (0.01,0) [0|30] "m^2/s^3"  VideoFrontCenter
 SG_ RFC_Obj04_AxAyCoVnce : 440|12@1+ (0.01,0) [0|30] "m^2/s^4"  VideoFrontCenter
 SG_ RFC_Obj04_MobileObstConf : 452|6@1+ (2,0) [0|100] "%"  VideoFrontCenter
 SG_ RFC_Obj04_Mob4PlusWhlConf : 458|6@1+ (2,0) [0|100] "%"  VideoFrontCenter
 SG_ RFC_Obj04_Mob2WhlConf : 464|6@1+ (2,0) [0|100] "%"  VideoFrontCenter
 SG_ RFC_Obj04_MobPedConf : 470|6@1+ (2,0) [0|100] "%"  VideoFrontCenter
 SG_ RFC_Obj04_FourPlusWhlCarConf : 476|6@1+ (2,0) [0|100] "%"  VideoFrontCenter
 SG_ RFC_Obj04_FourPlusWhlHGVConf : 482|6@1+ (2,0) [0|100] "%"  VideoFrontCenter
 SG_ RFC_Obj04_GroundReflexConf : 488|6@1+ (2,0) [0|100] "%"  VideoFrontCenter
 SG_ RFC_Obj04_StatObstConf : 494|6@1+ (2,0) [0|100] "%"  VideoFrontCenter
 SG_ RFC_Obj04_StatBarrierConf : 500|6@1+ (2,0) [0|100] "%"  VideoFrontCenter

BO_ 411 RFC_Obj05: 64 RadarFrontCenter
 SG_ RFC_Obj05_CRC : 0|16@1+ (1,0) [0|65535] ""  VideoFrontCenter
 SG_ RFC_Obj05_AliveCtr : 16|8@1+ (1,0) [0|255] ""  VideoFrontCenter
 SG_ RFC_Obj05_ProtBlockCtr : 24|4@1+ (1,0) [0|15] ""  VideoFrontCenter
 SG_ RFC_Obj05_ReferencePoint : 28|4@1+ (1,0) [0|15] ""  VideoFrontCenter
 SG_ RFC_Obj05_ObjId : 32|7@1+ (1,0) [0|127] ""  VideoFrontCenter
 SG_ RFC_Obj05_MeasurementStatus : 39|1@1+ (1,0) [0|1] ""  VideoFrontCenter
 SG_ RFC_Obj05_Px : 40|13@1+ (0.0625,-256) [-256|255.9375] "m"  VideoFrontCenter
 SG_ RFC_Obj05_Py : 53|11@1+ (0.125,-128) [-128|127.875] "m"  VideoFrontCenter
 SG_ RFC_Obj05_PxVnce : 64|12@1+ (0.01,0) [0|30] "m^2"  VideoFrontCenter
 SG_ RFC_Obj05_PyVnce : 76|12@1+ (0.01,0) [0|30] "m^2"  VideoFrontCenter
 SG_ RFC_Obj05_Vx : 88|12@1+ (0.0625,-128) [-128|127.9375] "m/s"  VideoFrontCenter
 SG_ RFC_Obj05_Vy : 100|10@1+ (0.125,-64) [-64|63.875] "m/s"  VideoFrontCenter
 SG_ RFC_Obj05_Ax : 110|10@1+ (0.03125,-16) [-16|15.96875] "m/s^2"  VideoFrontCenter
 SG_ RFC_Obj05_Ay : 120|9@1+ (0.0625,-16) [-16|15.9375] "m/s^2"  VideoFrontCenter
 SG_ RFC_Obj05_OrientationYaw : 129|9@1+ (0.0175,-4.48) [-3.15|3.15] "rad"  VideoFrontCenter
 SG_ RFC_Obj05_ExistProb : 138|6@1+ (2,0) [0|100] "%"  VideoFrontCenter
 SG_ RFC_Obj05_VxVnce : 144|12@1+ (0.01,0) [0|30] "m^2/s^2"  VideoFrontCenter
 SG_ RFC_Obj05_VyVnce : 156|12@1+ (0.01,0) [0|30] "m^2/s^2"  VideoFrontCenter
 SG_ RFC_Obj05_AxVnce : 168|12@1+ (0.01,0) [0|30] "m^2/s^4"  VideoFrontCenter
 SG_ RFC_Obj05_AyVnce : 180|12@1+ (0.01,0) [0|30] "m^2/s^4"  VideoFrontCenter
 SG_ RFC_Obj05_OrientationYawVnce : 192|12@1+ (0.0003,0) [0|1] "rad^2"  VideoFrontCenter
 SG_ RFC_Obj05_MovingObserved : 204|6@1+ (2,0) [0|100] "%"  VideoFrontCenter
 SG_ RFC_Obj05_MovingProbability : 210|6@1+ (2,0) [0|100] "%"  VideoFrontCenter
 SG_ RFC_Obj05_Length : 216|7@1+ (0.125,0) [0|15.875] "m"  VideoFrontCenter
 SG_ RFC_Obj05_Valid : 223|1@1+ (1,0) [0|1] ""  VideoFrontCenter
 SG_ RFC_Obj05_LengthVnce : 224|12@1+ (0.01,0) [0|30] "m^2"  VideoFrontCenter
 SG_ RFC_Obj05_WidthVnce : 236|12@1+ (0.01,0) [0|30] "m^2"  VideoFrontCenter
 SG_ RFC_Obj05_Width : 248|7@1+ (0.125,0) [0|15.875] "m"  VideoFrontCenter
 SG_ RFC_Obj05_BehaviorType : 255|3@1+ (1,0) [0|7] ""  VideoFrontCenter
 SG_ RFC_Obj05_ObstacleConf : 258|6@1+ (2,0) [0|100] "%"  VideoFrontCenter
 SG_ RFC_Obj05_NonObstacleConf : 264|6@1+ (2,0) [0|100] "%"  VideoFrontCenter
 SG_ RFC_Obj05_PxPyCoVnce : 272|12@1+ (0.01,0) [0|30] "m^2"  VideoFrontCenter
 SG_ RFC_Obj05_PxVxCoVnce : 284|12@1+ (0.01,0) [0|30] "m^2/s"  VideoFrontCenter
 SG_ RFC_Obj05_PxVyCoVnce : 296|12@1+ (0.01,0) [0|30] "m^2/s"  VideoFrontCenter
 SG_ RFC_Obj05_PyVxCoVnce : 308|12@1+ (0.01,0) [0|30] "m^2/s"  VideoFrontCenter
 SG_ RFC_Obj05_PyVyCoVnce : 320|12@1+ (0.01,0) [0|30] "m^2/s"  VideoFrontCenter
 SG_ RFC_Obj05_VxVyCoVnce : 332|12@1+ (0.01,0) [0|30] "m^2/s^2"  VideoFrontCenter
 SG_ RFC_Obj05_PxAxCoVnce : 344|12@1+ (0.01,0) [0|30] "m^2/s^2"  VideoFrontCenter
 SG_ RFC_Obj05_PxAyCoVnce : 356|12@1+ (0.01,0) [0|30] "m^2/s^2"  VideoFrontCenter
 SG_ RFC_Obj05_PyAxCoVnce : 368|12@1+ (0.01,0) [0|30] "m^2/s^2"  VideoFrontCenter
 SG_ RFC_Obj05_PyAyCoVnce : 380|12@1+ (0.01,0) [0|30] "m^2/s^2"  VideoFrontCenter
 SG_ RFC_Obj05_VxAxCoVnce : 392|12@1+ (0.01,0) [0|30] "m^2/s^3"  VideoFrontCenter
 SG_ RFC_Obj05_VxAyCoVnce : 404|12@1+ (0.01,0) [0|30] "m^2/s^3"  VideoFrontCenter
 SG_ RFC_Obj05_VyAxCoVnce : 416|12@1+ (0.01,0) [0|30] "m^2/s^3"  VideoFrontCenter
 SG_ RFC_Obj05_VyAyCoVnce : 428|12@1+ (0.01,0) [0|30] "m^2/s^3"  VideoFrontCenter
 SG_ RFC_Obj05_AxAyCoVnce : 440|12@1+ (0.01,0) [0|30] "m^2/s^4"  VideoFrontCenter
 SG_ RFC_Obj05_MobileObstConf : 452|6@1+ (2,0) [0|100] "%"  VideoFrontCenter
 SG_ RFC_Obj05_Mob4PlusWhlConf : 458|6@1+ (2,0) [0|100] "%"  VideoFrontCenter
 SG_ RFC_Obj05_Mob2WhlConf : 464|6@1+ (2,0) [0|100] "%"  VideoFrontCenter
 SG_ RFC_Obj05_MobPedConf : 470|6@1+ (2,0) [0|100] "%"  VideoFrontCenter
 SG_ RFC_Obj05_FourPlusWhlCarConf : 476|6@1+ (2,0) [0|100] "%"  VideoFrontCenter
 SG_ RFC_Obj05_FourPlusWhlHGVConf : 482|6@1+ (2,0) [0|100] "%"  VideoFrontCenter
 SG_ RFC_Obj05_GroundReflexConf : 488|6@1+ (2,0) [0|100] "%"  VideoFrontCenter
 SG_ RFC_Obj05_StatObstConf : 494|6@1+ (2,0) [0|100] "%"  VideoFrontCenter
 SG_ RFC_Obj05_StatBarrierConf : 500|6@1+ (2,0) [0|100] "%"  VideoFrontCenter

BO_ 412 RFC_Obj06: 64 RadarFrontCenter
 SG_ RFC_Obj06_CRC : 0|16@1+ (1,0) [0|65535] ""  VideoFrontCenter
 SG_ RFC_Obj06_AliveCtr : 16|8@1+ (1,0) [0|255] ""  VideoFrontCenter
 SG_ RFC_Obj06_ProtBlockCtr : 24|4@1+ (1,0) [0|15] ""  VideoFrontCenter
 SG_ RFC_Obj06_ReferencePoint : 28|4@1+ (1,0) [0|15] ""  VideoFrontCenter
 SG_ RFC_Obj06_ObjId : 32|7@1+ (1,0) [0|127] ""  VideoFrontCenter
 SG_ RFC_Obj06_MeasurementStatus : 39|1@1+ (1,0) [0|1] ""  VideoFrontCenter
 SG_ RFC_Obj06_Px : 40|13@1+ (0.0625,-256) [-256|255.9375] "m"  VideoFrontCenter
 SG_ RFC_Obj06_Py : 53|11@1+ (0.125,-128) [-128|127.875] "m"  VideoFrontCenter
 SG_ RFC_Obj06_PxVnce : 64|12@1+ (0.01,0) [0|30] "m^2"  VideoFrontCenter
 SG_ RFC_Obj06_PyVnce : 76|12@1+ (0.01,0) [0|30] "m^2"  VideoFrontCenter
 SG_ RFC_Obj06_Vx : 88|12@1+ (0.0625,-128) [-128|127.9375] "m/s"  VideoFrontCenter
 SG_ RFC_Obj06_Vy : 100|10@1+ (0.125,-64) [-64|63.875] "m/s"  VideoFrontCenter
 SG_ RFC_Obj06_Ax : 110|10@1+ (0.03125,-16) [-16|15.96875] "m/s^2"  VideoFrontCenter
 SG_ RFC_Obj06_Ay : 120|9@1+ (0.0625,-16) [-16|15.9375] "m/s^2"  VideoFrontCenter
 SG_ RFC_Obj06_OrientationYaw : 129|9@1+ (0.0175,-4.48) [-3.15|3.15] "rad"  VideoFrontCenter
 SG_ RFC_Obj06_ExistProb : 138|6@1+ (2,0) [0|100] "%"  VideoFrontCenter
 SG_ RFC_Obj06_VxVnce : 144|12@1+ (0.01,0) [0|30] "m^2/s^2"  VideoFrontCenter
 SG_ RFC_Obj06_VyVnce : 156|12@1+ (0.01,0) [0|30] "m^2/s^2"  VideoFrontCenter
 SG_ RFC_Obj06_AxVnce : 168|12@1+ (0.01,0) [0|30] "m^2/s^4"  VideoFrontCenter
 SG_ RFC_Obj06_AyVnce : 180|12@1+ (0.01,0) [0|30] "m^2/s^4"  VideoFrontCenter
 SG_ RFC_Obj06_OrientationYawVnce : 192|12@1+ (0.0003,0) [0|1] "rad^2"  VideoFrontCenter
 SG_ RFC_Obj06_MovingObserved : 204|6@1+ (2,0) [0|100] "%"  VideoFrontCenter
 SG_ RFC_Obj06_MovingProbability : 210|6@1+ (2,0) [0|100] "%"  VideoFrontCenter
 SG_ RFC_Obj06_Length : 216|7@1+ (0.125,0) [0|15.875] "m"  VideoFrontCenter
 SG_ RFC_Obj06_Valid : 223|1@1+ (1,0) [0|1] ""  VideoFrontCenter
 SG_ RFC_Obj06_LengthVnce : 224|12@1+ (0.01,0) [0|30] "m^2"  VideoFrontCenter
 SG_ RFC_Obj06_WidthVnce : 236|12@1+ (0.01,0) [0|30] "m^2"  VideoFrontCenter
 SG_ RFC_Obj06_Width : 248|7@1+ (0.125,0) [0|15.875] "m"  VideoFrontCenter
 SG_ RFC_Obj06_BehaviorType : 255|3@1+ (1,0) [0|7] ""  VideoFrontCenter
 SG_ RFC_Obj06_ObstacleConf : 258|6@1+ (2,0) [0|100] "%"  VideoFrontCenter
 SG_ RFC_Obj06_NonObstacleConf : 264|6@1+ (2,0) [0|100] "%"  VideoFrontCenter
 SG_ RFC_Obj06_PxPyCoVnce : 272|12@1+ (0.01,0) [0|30] "m^2"  VideoFrontCenter
 SG_ RFC_Obj06_PxVxCoVnce : 284|12@1+ (0.01,0) [0|30] "m^2/s"  VideoFrontCenter
 SG_ RFC_Obj06_PxVyCoVnce : 296|12@1+ (0.01,0) [0|30] "m^2/s"  VideoFrontCenter
 SG_ RFC_Obj06_PyVxCoVnce : 308|12@1+ (0.01,0) [0|30] "m^2/s"  VideoFrontCenter
 SG_ RFC_Obj06_PyVyCoVnce : 320|12@1+ (0.01,0) [0|30] "m^2/s"  VideoFrontCenter
 SG_ RFC_Obj06_VxVyCoVnce : 332|12@1+ (0.01,0) [0|30] "m^2/s^2"  VideoFrontCenter
 SG_ RFC_Obj06_PxAxCoVnce : 344|12@1+ (0.01,0) [0|30] "m^2/s^2"  VideoFrontCenter
 SG_ RFC_Obj06_PxAyCoVnce : 356|12@1+ (0.01,0) [0|30] "m^2/s^2"  VideoFrontCenter
 SG_ RFC_Obj06_PyAxCoVnce : 368|12@1+ (0.01,0) [0|30] "m^2/s^2"  VideoFrontCenter
 SG_ RFC_Obj06_PyAyCoVnce : 380|12@1+ (0.01,0) [0|30] "m^2/s^2"  VideoFrontCenter
 SG_ RFC_Obj06_VxAxCoVnce : 392|12@1+ (0.01,0) [0|30] "m^2/s^3"  VideoFrontCenter
 SG_ RFC_Obj06_VxAyCoVnce : 404|12@1+ (0.01,0) [0|30] "m^2/s^3"  VideoFrontCenter
 SG_ RFC_Obj06_VyAxCoVnce : 416|12@1+ (0.01,0) [0|30] "m^2/s^3"  VideoFrontCenter
 SG_ RFC_Obj06_VyAyCoVnce : 428|12@1+ (0.01,0) [0|30] "m^2/s^3"  VideoFrontCenter
 SG_ RFC_Obj06_AxAyCoVnce : 440|12@1+ (0.01,0) [0|30] "m^2/s^4"  VideoFrontCenter
 SG_ RFC_Obj06_MobileObstConf : 452|6@1+ (2,0) [0|100] "%"  VideoFrontCenter
 SG_ RFC_Obj06_Mob4PlusWhlConf : 458|6@1+ (2,0) [0|100] "%"  VideoFrontCenter
 SG_ RFC_Obj06_Mob2WhlConf : 464|6@1+ (2,0) [0|100] "%"  VideoFrontCenter
 SG_ RFC_Obj06_MobPedConf : 470|6@1+ (2,0) [0|100] "%"  VideoFrontCenter
 SG_ RFC_Obj06_FourPlusWhlCarConf : 476|6@1+ (2,0) [0|100] "%"  VideoFrontCenter
 SG_ RFC_Obj06_FourPlusWhlHGVConf : 482|6@1+ (2,0) [0|100] "%"  VideoFrontCenter
 SG_ RFC_Obj06_GroundReflexConf : 488|6@1+ (2,0) [0|100] "%"  VideoFrontCenter
 SG_ RFC_Obj06_StatObstConf : 494|6@1+ (2,0) [0|100] "%"  VideoFrontCenter
 SG_ RFC_Obj06_StatBarrierConf : 500|6@1+ (2,0) [0|100] "%"  VideoFrontCenter

BO_ 413 RFC_Obj07: 64 RadarFrontCenter
 SG_ RFC_Obj07_CRC : 0|16@1+ (1,0) [0|65535] ""  VideoFrontCenter
 SG_ RFC_Obj07_AliveCtr : 16|8@1+ (1,0) [0|255] ""  VideoFrontCenter
 SG_ RFC_Obj07_ProtBlockCtr : 24|4@1+ (1,0) [0|15] ""  VideoFrontCenter
 SG_ RFC_Obj07_ReferencePoint : 28|4@1+ (1,0) [0|15] ""  VideoFrontCenter
 SG_ RFC_Obj07_ObjId : 32|7@1+ (1,0) [0|127] ""  VideoFrontCenter
 SG_ RFC_Obj07_MeasurementStatus : 39|1@1+ (1,0) [0|1] ""  VideoFrontCenter
 SG_ RFC_Obj07_Px : 40|13@1+ (0.0625,-256) [-256|255.9375] "m"  VideoFrontCenter
 SG_ RFC_Obj07_Py : 53|11@1+ (0.125,-128) [-128|127.875] "m"  VideoFrontCenter
 SG_ RFC_Obj07_PxVnce : 64|12@1+ (0.01,0) [0|30] "m^2"  VideoFrontCenter
 SG_ RFC_Obj07_PyVnce : 76|12@1+ (0.01,0) [0|30] "m^2"  VideoFrontCenter
 SG_ RFC_Obj07_Vx : 88|12@1+ (0.0625,-128) [-128|127.9375] "m/s"  VideoFrontCenter
 SG_ RFC_Obj07_Vy : 100|10@1+ (0.125,-64) [-64|63.875] "m/s"  VideoFrontCenter
 SG_ RFC_Obj07_Ax : 110|10@1+ (0.03125,-16) [-16|15.96875] "m/s^2"  VideoFrontCenter
 SG_ RFC_Obj07_Ay : 120|9@1+ (0.0625,-16) [-16|15.9375] "m/s^2"  VideoFrontCenter
 SG_ RFC_Obj07_OrientationYaw : 129|9@1+ (0.0175,-4.48) [-3.15|3.15] "rad"  VideoFrontCenter
 SG_ RFC_Obj07_ExistProb : 138|6@1+ (2,0) [0|100] "%"  VideoFrontCenter
 SG_ RFC_Obj07_VxVnce : 144|12@1+ (0.01,0) [0|30] "m^2/s^2"  VideoFrontCenter
 SG_ RFC_Obj07_VyVnce : 156|12@1+ (0.01,0) [0|30] "m^2/s^2"  VideoFrontCenter
 SG_ RFC_Obj07_AxVnce : 168|12@1+ (0.01,0) [0|30] "m^2/s^4"  VideoFrontCenter
 SG_ RFC_Obj07_AyVnce : 180|12@1+ (0.01,0) [0|30] "m^2/s^4"  VideoFrontCenter
 SG_ RFC_Obj07_OrientationYawVnce : 192|12@1+ (0.0003,0) [0|1] "rad^2"  VideoFrontCenter
 SG_ RFC_Obj07_MovingObserved : 204|6@1+ (2,0) [0|100] "%"  VideoFrontCenter
 SG_ RFC_Obj07_MovingProbability : 210|6@1+ (2,0) [0|100] "%"  VideoFrontCenter
 SG_ RFC_Obj07_Length : 216|7@1+ (0.125,0) [0|15.875] "m"  VideoFrontCenter
 SG_ RFC_Obj07_Valid : 223|1@1+ (1,0) [0|1] ""  VideoFrontCenter
 SG_ RFC_Obj07_LengthVnce : 224|12@1+ (0.01,0) [0|30] "m^2"  VideoFrontCenter
 SG_ RFC_Obj07_WidthVnce : 236|12@1+ (0.01,0) [0|30] "m^2"  VideoFrontCenter
 SG_ RFC_Obj07_Width : 248|7@1+ (0.125,0) [0|15.875] "m"  VideoFrontCenter
 SG_ RFC_Obj07_BehaviorType : 255|3@1+ (1,0) [0|7] ""  VideoFrontCenter
 SG_ RFC_Obj07_ObstacleConf : 258|6@1+ (2,0) [0|100] "%"  VideoFrontCenter
 SG_ RFC_Obj07_NonObstacleConf : 264|6@1+ (2,0) [0|100] "%"  VideoFrontCenter
 SG_ RFC_Obj07_PxPyCoVnce : 272|12@1+ (0.01,0) [0|30] "m^2"  VideoFrontCenter
 SG_ RFC_Obj07_PxVxCoVnce : 284|12@1+ (0.01,0) [0|30] "m^2/s"  VideoFrontCenter
 SG_ RFC_Obj07_PxVyCoVnce : 296|12@1+ (0.01,0) [0|30] "m^2/s"  VideoFrontCenter
 SG_ RFC_Obj07_PyVxCoVnce : 308|12@1+ (0.01,0) [0|30] "m^2/s"  VideoFrontCenter
 SG_ RFC_Obj07_PyVyCoVnce : 320|12@1+ (0.01,0) [0|30] "m^2/s"  VideoFrontCenter
 SG_ RFC_Obj07_VxVyCoVnce : 332|12@1+ (0.01,0) [0|30] "m^2/s^2"  VideoFrontCenter
 SG_ RFC_Obj07_PxAxCoVnce : 344|12@1+ (0.01,0) [0|30] "m^2/s^2"  VideoFrontCenter
 SG_ RFC_Obj07_PxAyCoVnce : 356|12@1+ (0.01,0) [0|30] "m^2/s^2"  VideoFrontCenter
 SG_ RFC_Obj07_PyAxCoVnce : 368|12@1+ (0.01,0) [0|30] "m^2/s^2"  VideoFrontCenter
 SG_ RFC_Obj07_PyAyCoVnce : 380|12@1+ (0.01,0) [0|30] "m^2/s^2"  VideoFrontCenter
 SG_ RFC_Obj07_VxAxCoVnce : 392|12@1+ (0.01,0) [0|30] "m^2/s^3"  VideoFrontCenter
 SG_ RFC_Obj07_VxAyCoVnce : 404|12@1+ (0.01,0) [0|30] "m^2/s^3"  VideoFrontCenter
 SG_ RFC_Obj07_VyAxCoVnce : 416|12@1+ (0.01,0) [0|30] "m^2/s^3"  VideoFrontCenter
 SG_ RFC_Obj07_VyAyCoVnce : 428|12@1+ (0.01,0) [0|30] "m^2/s^3"  VideoFrontCenter
 SG_ RFC_Obj07_AxAyCoVnce : 440|12@1+ (0.01,0) [0|30] "m^2/s^4"  VideoFrontCenter
 SG_ RFC_Obj07_MobileObstConf : 452|6@1+ (2,0) [0|100] "%"  VideoFrontCenter
 SG_ RFC_Obj07_Mob4PlusWhlConf : 458|6@1+ (2,0) [0|100] "%"  VideoFrontCenter
 SG_ RFC_Obj07_Mob2WhlConf : 464|6@1+ (2,0) [0|100] "%"  VideoFrontCenter
 SG_ RFC_Obj07_MobPedConf : 470|6@1+ (2,0) [0|100] "%"  VideoFrontCenter
 SG_ RFC_Obj07_FourPlusWhlCarConf : 476|6@1+ (2,0) [0|100] "%"  VideoFrontCenter
 SG_ RFC_Obj07_FourPlusWhlHGVConf : 482|6@1+ (2,0) [0|100] "%"  VideoFrontCenter
 SG_ RFC_Obj07_GroundReflexConf : 488|6@1+ (2,0) [0|100] "%"  VideoFrontCenter
 SG_ RFC_Obj07_StatObstConf : 494|6@1+ (2,0) [0|100] "%"  VideoFrontCenter
 SG_ RFC_Obj07_StatBarrierConf : 500|6@1+ (2,0) [0|100] "%"  VideoFrontCenter

BO_ 414 RFC_Obj08: 64 RadarFrontCenter
 SG_ RFC_Obj08_CRC : 0|16@1+ (1,0) [0|65535] ""  VideoFrontCenter
 SG_ RFC_Obj08_AliveCtr : 16|8@1+ (1,0) [0|255] ""  VideoFrontCenter
 SG_ RFC_Obj08_ProtBlockCtr : 24|4@1+ (1,0) [0|15] ""  VideoFrontCenter
 SG_ RFC_Obj08_ReferencePoint : 28|4@1+ (1,0) [0|15] ""  VideoFrontCenter
 SG_ RFC_Obj08_ObjId : 32|7@1+ (1,0) [0|127] ""  VideoFrontCenter
 SG_ RFC_Obj08_MeasurementStatus : 39|1@1+ (1,0) [0|1] ""  VideoFrontCenter
 SG_ RFC_Obj08_Px : 40|13@1+ (0.0625,-256) [-256|255.9375] "m"  VideoFrontCenter
 SG_ RFC_Obj08_Py : 53|11@1+ (0.125,-128) [-128|127.875] "m"  VideoFrontCenter
 SG_ RFC_Obj08_PxVnce : 64|12@1+ (0.01,0) [0|30] "m^2"  VideoFrontCenter
 SG_ RFC_Obj08_PyVnce : 76|12@1+ (0.01,0) [0|30] "m^2"  VideoFrontCenter
 SG_ RFC_Obj08_Vx : 88|12@1+ (0.0625,-128) [-128|127.9375] "m/s"  VideoFrontCenter
 SG_ RFC_Obj08_Vy : 100|10@1+ (0.125,-64) [-64|63.875] "m/s"  VideoFrontCenter
 SG_ RFC_Obj08_Ax : 110|10@1+ (0.03125,-16) [-16|15.96875] "m/s^2"  VideoFrontCenter
 SG_ RFC_Obj08_Ay : 120|9@1+ (0.0625,-16) [-16|15.9375] "m/s^2"  VideoFrontCenter
 SG_ RFC_Obj08_OrientationYaw : 129|9@1+ (0.0175,-4.48) [-3.15|3.15] "rad"  VideoFrontCenter
 SG_ RFC_Obj08_ExistProb : 138|6@1+ (2,0) [0|100] "%"  VideoFrontCenter
 SG_ RFC_Obj08_VxVnce : 144|12@1+ (0.01,0) [0|30] "m^2/s^2"  VideoFrontCenter
 SG_ RFC_Obj08_VyVnce : 156|12@1+ (0.01,0) [0|30] "m^2/s^2"  VideoFrontCenter
 SG_ RFC_Obj08_AxVnce : 168|12@1+ (0.01,0) [0|30] "m^2/s^4"  VideoFrontCenter
 SG_ RFC_Obj08_AyVnce : 180|12@1+ (0.01,0) [0|30] "m^2/s^4"  VideoFrontCenter
 SG_ RFC_Obj08_OrientationYawVnce : 192|12@1+ (0.0003,0) [0|1] "rad^2"  VideoFrontCenter
 SG_ RFC_Obj08_MovingObserved : 204|6@1+ (2,0) [0|100] "%"  VideoFrontCenter
 SG_ RFC_Obj08_MovingProbability : 210|6@1+ (2,0) [0|100] "%"  VideoFrontCenter
 SG_ RFC_Obj08_Length : 216|7@1+ (0.125,0) [0|15.875] "m"  VideoFrontCenter
 SG_ RFC_Obj08_Valid : 223|1@1+ (1,0) [0|1] ""  VideoFrontCenter
 SG_ RFC_Obj08_LengthVnce : 224|12@1+ (0.01,0) [0|30] "m^2"  VideoFrontCenter
 SG_ RFC_Obj08_WidthVnce : 236|12@1+ (0.01,0) [0|30] "m^2"  VideoFrontCenter
 SG_ RFC_Obj08_Width : 248|7@1+ (0.125,0) [0|15.875] "m"  VideoFrontCenter
 SG_ RFC_Obj08_BehaviorType : 255|3@1+ (1,0) [0|7] ""  VideoFrontCenter
 SG_ RFC_Obj08_ObstacleConf : 258|6@1+ (2,0) [0|100] "%"  VideoFrontCenter
 SG_ RFC_Obj08_NonObstacleConf : 264|6@1+ (2,0) [0|100] "%"  VideoFrontCenter
 SG_ RFC_Obj08_PxPyCoVnce : 272|12@1+ (0.01,0) [0|30] "m^2"  VideoFrontCenter
 SG_ RFC_Obj08_PxVxCoVnce : 284|12@1+ (0.01,0) [0|30] "m^2/s"  VideoFrontCenter
 SG_ RFC_Obj08_PxVyCoVnce : 296|12@1+ (0.01,0) [0|30] "m^2/s"  VideoFrontCenter
 SG_ RFC_Obj08_PyVxCoVnce : 308|12@1+ (0.01,0) [0|30] "m^2/s"  VideoFrontCenter
 SG_ RFC_Obj08_PyVyCoVnce : 320|12@1+ (0.01,0) [0|30] "m^2/s"  VideoFrontCenter
 SG_ RFC_Obj08_VxVyCoVnce : 332|12@1+ (0.01,0) [0|30] "m^2/s^2"  VideoFrontCenter
 SG_ RFC_Obj08_PxAxCoVnce : 344|12@1+ (0.01,0) [0|30] "m^2/s^2"  VideoFrontCenter
 SG_ RFC_Obj08_PxAyCoVnce : 356|12@1+ (0.01,0) [0|30] "m^2/s^2"  VideoFrontCenter
 SG_ RFC_Obj08_PyAxCoVnce : 368|12@1+ (0.01,0) [0|30] "m^2/s^2"  VideoFrontCenter
 SG_ RFC_Obj08_PyAyCoVnce : 380|12@1+ (0.01,0) [0|30] "m^2/s^2"  VideoFrontCenter
 SG_ RFC_Obj08_VxAxCoVnce : 392|12@1+ (0.01,0) [0|30] "m^2/s^3"  VideoFrontCenter
 SG_ RFC_Obj08_VxAyCoVnce : 404|12@1+ (0.01,0) [0|30] "m^2/s^3"  VideoFrontCenter
 SG_ RFC_Obj08_VyAxCoVnce : 416|12@1+ (0.01,0) [0|30] "m^2/s^3"  VideoFrontCenter
 SG_ RFC_Obj08_VyAyCoVnce : 428|12@1+ (0.01,0) [0|30] "m^2/s^3"  VideoFrontCenter
 SG_ RFC_Obj08_AxAyCoVnce : 440|12@1+ (0.01,0) [0|30] "m^2/s^4"  VideoFrontCenter
 SG_ RFC_Obj08_MobileObstConf : 452|6@1+ (2,0) [0|100] "%"  VideoFrontCenter
 SG_ RFC_Obj08_Mob4PlusWhlConf : 458|6@1+ (2,0) [0|100] "%"  VideoFrontCenter
 SG_ RFC_Obj08_Mob2WhlConf : 464|6@1+ (2,0) [0|100] "%"  VideoFrontCenter
 SG_ RFC_Obj08_MobPedConf : 470|6@1+ (2,0) [0|100] "%"  VideoFrontCenter
 SG_ RFC_Obj08_FourPlusWhlCarConf : 476|6@1+ (2,0) [0|100] "%"  VideoFrontCenter
 SG_ RFC_Obj08_FourPlusWhlHGVConf : 482|6@1+ (2,0) [0|100] "%"  VideoFrontCenter
 SG_ RFC_Obj08_GroundReflexConf : 488|6@1+ (2,0) [0|100] "%"  VideoFrontCenter
 SG_ RFC_Obj08_StatObstConf : 494|6@1+ (2,0) [0|100] "%"  VideoFrontCenter
 SG_ RFC_Obj08_StatBarrierConf : 500|6@1+ (2,0) [0|100] "%"  VideoFrontCenter

BO_ 415 RFC_Obj09: 64 RadarFrontCenter
 SG_ RFC_Obj09_CRC : 0|16@1+ (1,0) [0|65535] ""  VideoFrontCenter
 SG_ RFC_Obj09_AliveCtr : 16|8@1+ (1,0) [0|255] ""  VideoFrontCenter
 SG_ RFC_Obj09_ProtBlockCtr : 24|4@1+ (1,0) [0|15] ""  VideoFrontCenter
 SG_ RFC_Obj09_ReferencePoint : 28|4@1+ (1,0) [0|15] ""  VideoFrontCenter
 SG_ RFC_Obj09_ObjId : 32|7@1+ (1,0) [0|127] ""  VideoFrontCenter
 SG_ RFC_Obj09_MeasurementStatus : 39|1@1+ (1,0) [0|1] ""  VideoFrontCenter
 SG_ RFC_Obj09_Px : 40|13@1+ (0.0625,-256) [-256|255.9375] "m"  VideoFrontCenter
 SG_ RFC_Obj09_Py : 53|11@1+ (0.125,-128) [-128|127.875] "m"  VideoFrontCenter
 SG_ RFC_Obj09_PxVnce : 64|12@1+ (0.01,0) [0|30] "m^2"  VideoFrontCenter
 SG_ RFC_Obj09_PyVnce : 76|12@1+ (0.01,0) [0|30] "m^2"  VideoFrontCenter
 SG_ RFC_Obj09_Vx : 88|12@1+ (0.0625,-128) [-128|127.9375] "m/s"  VideoFrontCenter
 SG_ RFC_Obj09_Vy : 100|10@1+ (0.125,-64) [-64|63.875] "m/s"  VideoFrontCenter
 SG_ RFC_Obj09_Ax : 110|10@1+ (0.03125,-16) [-16|15.96875] "m/s^2"  VideoFrontCenter
 SG_ RFC_Obj09_Ay : 120|9@1+ (0.0625,-16) [-16|15.9375] "m/s^2"  VideoFrontCenter
 SG_ RFC_Obj09_OrientationYaw : 129|9@1+ (0.0175,-4.48) [-3.15|3.15] "rad"  VideoFrontCenter
 SG_ RFC_Obj09_ExistProb : 138|6@1+ (2,0) [0|100] "%"  VideoFrontCenter
 SG_ RFC_Obj09_VxVnce : 144|12@1+ (0.01,0) [0|30] "m^2/s^2"  VideoFrontCenter
 SG_ RFC_Obj09_VyVnce : 156|12@1+ (0.01,0) [0|30] "m^2/s^2"  VideoFrontCenter
 SG_ RFC_Obj09_AxVnce : 168|12@1+ (0.01,0) [0|30] "m^2/s^4"  VideoFrontCenter
 SG_ RFC_Obj09_AyVnce : 180|12@1+ (0.01,0) [0|30] "m^2/s^4"  VideoFrontCenter
 SG_ RFC_Obj09_OrientationYawVnce : 192|12@1+ (0.0003,0) [0|1] "rad^2"  VideoFrontCenter
 SG_ RFC_Obj09_MovingObserved : 204|6@1+ (2,0) [0|100] "%"  VideoFrontCenter
 SG_ RFC_Obj09_MovingProbability : 210|6@1+ (2,0) [0|100] "%"  VideoFrontCenter
 SG_ RFC_Obj09_Length : 216|7@1+ (0.125,0) [0|15.875] "m"  VideoFrontCenter
 SG_ RFC_Obj09_Valid : 223|1@1+ (1,0) [0|1] ""  VideoFrontCenter
 SG_ RFC_Obj09_LengthVnce : 224|12@1+ (0.01,0) [0|30] "m^2"  VideoFrontCenter
 SG_ RFC_Obj09_WidthVnce : 236|12@1+ (0.01,0) [0|30] "m^2"  VideoFrontCenter
 SG_ RFC_Obj09_Width : 248|7@1+ (0.125,0) [0|15.875] "m"  VideoFrontCenter
 SG_ RFC_Obj09_BehaviorType : 255|3@1+ (1,0) [0|7] ""  VideoFrontCenter
 SG_ RFC_Obj09_ObstacleConf : 258|6@1+ (2,0) [0|100] "%"  VideoFrontCenter
 SG_ RFC_Obj09_NonObstacleConf : 264|6@1+ (2,0) [0|100] "%"  VideoFrontCenter
 SG_ RFC_Obj09_PxPyCoVnce : 272|12@1+ (0.01,0) [0|30] "m^2"  VideoFrontCenter
 SG_ RFC_Obj09_PxVxCoVnce : 284|12@1+ (0.01,0) [0|30] "m^2/s"  VideoFrontCenter
 SG_ RFC_Obj09_PxVyCoVnce : 296|12@1+ (0.01,0) [0|30] "m^2/s"  VideoFrontCenter
 SG_ RFC_Obj09_PyVxCoVnce : 308|12@1+ (0.01,0) [0|30] "m^2/s"  VideoFrontCenter
 SG_ RFC_Obj09_PyVyCoVnce : 320|12@1+ (0.01,0) [0|30] "m^2/s"  VideoFrontCenter
 SG_ RFC_Obj09_VxVyCoVnce : 332|12@1+ (0.01,0) [0|30] "m^2/s^2"  VideoFrontCenter
 SG_ RFC_Obj09_PxAxCoVnce : 344|12@1+ (0.01,0) [0|30] "m^2/s^2"  VideoFrontCenter
 SG_ RFC_Obj09_PxAyCoVnce : 356|12@1+ (0.01,0) [0|30] "m^2/s^2"  VideoFrontCenter
 SG_ RFC_Obj09_PyAxCoVnce : 368|12@1+ (0.01,0) [0|30] "m^2/s^2"  VideoFrontCenter
 SG_ RFC_Obj09_PyAyCoVnce : 380|12@1+ (0.01,0) [0|30] "m^2/s^2"  VideoFrontCenter
 SG_ RFC_Obj09_VxAxCoVnce : 392|12@1+ (0.01,0) [0|30] "m^2/s^3"  VideoFrontCenter
 SG_ RFC_Obj09_VxAyCoVnce : 404|12@1+ (0.01,0) [0|30] "m^2/s^3"  VideoFrontCenter
 SG_ RFC_Obj09_VyAxCoVnce : 416|12@1+ (0.01,0) [0|30] "m^2/s^3"  VideoFrontCenter
 SG_ RFC_Obj09_VyAyCoVnce : 428|12@1+ (0.01,0) [0|30] "m^2/s^3"  VideoFrontCenter
 SG_ RFC_Obj09_AxAyCoVnce : 440|12@1+ (0.01,0) [0|30] "m^2/s^4"  VideoFrontCenter
 SG_ RFC_Obj09_MobileObstConf : 452|6@1+ (2,0) [0|100] "%"  VideoFrontCenter
 SG_ RFC_Obj09_Mob4PlusWhlConf : 458|6@1+ (2,0) [0|100] "%"  VideoFrontCenter
 SG_ RFC_Obj09_Mob2WhlConf : 464|6@1+ (2,0) [0|100] "%"  VideoFrontCenter
 SG_ RFC_Obj09_MobPedConf : 470|6@1+ (2,0) [0|100] "%"  VideoFrontCenter
 SG_ RFC_Obj09_FourPlusWhlCarConf : 476|6@1+ (2,0) [0|100] "%"  VideoFrontCenter
 SG_ RFC_Obj09_FourPlusWhlHGVConf : 482|6@1+ (2,0) [0|100] "%"  VideoFrontCenter
 SG_ RFC_Obj09_GroundReflexConf : 488|6@1+ (2,0) [0|100] "%"  VideoFrontCenter
 SG_ RFC_Obj09_StatObstConf : 494|6@1+ (2,0) [0|100] "%"  VideoFrontCenter
 SG_ RFC_Obj09_StatBarrierConf : 500|6@1+ (2,0) [0|100] "%"  VideoFrontCenter

BO_ 416 RFC_Obj10: 64 RadarFrontCenter
 SG_ RFC_Obj10_CRC : 0|16@1+ (1,0) [0|65535] ""  VideoFrontCenter
 SG_ RFC_Obj10_AliveCtr : 16|8@1+ (1,0) [0|255] ""  VideoFrontCenter
 SG_ RFC_Obj10_ProtBlockCtr : 24|4@1+ (1,0) [0|15] ""  VideoFrontCenter
 SG_ RFC_Obj10_ReferencePoint : 28|4@1+ (1,0) [0|15] ""  VideoFrontCenter
 SG_ RFC_Obj10_ObjId : 32|7@1+ (1,0) [0|127] ""  VideoFrontCenter
 SG_ RFC_Obj10_MeasurementStatus : 39|1@1+ (1,0) [0|1] ""  VideoFrontCenter
 SG_ RFC_Obj10_Px : 40|13@1+ (0.0625,-256) [-256|255.9375] "m"  VideoFrontCenter
 SG_ RFC_Obj10_Py : 53|11@1+ (0.125,-128) [-128|127.875] "m"  VideoFrontCenter
 SG_ RFC_Obj10_PxVnce : 64|12@1+ (0.01,0) [0|30] "m^2"  VideoFrontCenter
 SG_ RFC_Obj10_PyVnce : 76|12@1+ (0.01,0) [0|30] "m^2"  VideoFrontCenter
 SG_ RFC_Obj10_Vx : 88|12@1+ (0.0625,-128) [-128|127.9375] "m/s"  VideoFrontCenter
 SG_ RFC_Obj10_Vy : 100|10@1+ (0.125,-64) [-64|63.875] "m/s"  VideoFrontCenter
 SG_ RFC_Obj10_Ax : 110|10@1+ (0.03125,-16) [-16|15.96875] "m/s^2"  VideoFrontCenter
 SG_ RFC_Obj10_Ay : 120|9@1+ (0.0625,-16) [-16|15.9375] "m/s^2"  VideoFrontCenter
 SG_ RFC_Obj10_OrientationYaw : 129|9@1+ (0.0175,-4.48) [-3.15|3.15] "rad"  VideoFrontCenter
 SG_ RFC_Obj10_ExistProb : 138|6@1+ (2,0) [0|100] "%"  VideoFrontCenter
 SG_ RFC_Obj10_VxVnce : 144|12@1+ (0.01,0) [0|30] "m^2/s^2"  VideoFrontCenter
 SG_ RFC_Obj10_VyVnce : 156|12@1+ (0.01,0) [0|30] "m^2/s^2"  VideoFrontCenter
 SG_ RFC_Obj10_AxVnce : 168|12@1+ (0.01,0) [0|30] "m^2/s^4"  VideoFrontCenter
 SG_ RFC_Obj10_AyVnce : 180|12@1+ (0.01,0) [0|30] "m^2/s^4"  VideoFrontCenter
 SG_ RFC_Obj10_OrientationYawVnce : 192|12@1+ (0.0003,0) [0|1] "rad^2"  VideoFrontCenter
 SG_ RFC_Obj10_MovingObserved : 204|6@1+ (2,0) [0|100] "%"  VideoFrontCenter
 SG_ RFC_Obj10_MovingProbability : 210|6@1+ (2,0) [0|100] "%"  VideoFrontCenter
 SG_ RFC_Obj10_Length : 216|7@1+ (0.125,0) [0|15.875] "m"  VideoFrontCenter
 SG_ RFC_Obj10_Valid : 223|1@1+ (1,0) [0|1] ""  VideoFrontCenter
 SG_ RFC_Obj10_LengthVnce : 224|12@1+ (0.01,0) [0|30] "m^2"  VideoFrontCenter
 SG_ RFC_Obj10_WidthVnce : 236|12@1+ (0.01,0) [0|30] "m^2"  VideoFrontCenter
 SG_ RFC_Obj10_Width : 248|7@1+ (0.125,0) [0|15.875] "m"  VideoFrontCenter
 SG_ RFC_Obj10_BehaviorType : 255|3@1+ (1,0) [0|7] ""  VideoFrontCenter
 SG_ RFC_Obj10_ObstacleConf : 258|6@1+ (2,0) [0|100] "%"  VideoFrontCenter
 SG_ RFC_Obj10_NonObstacleConf : 264|6@1+ (2,0) [0|100] "%"  VideoFrontCenter
 SG_ RFC_Obj10_PxPyCoVnce : 272|12@1+ (0.01,0) [0|30] "m^2"  VideoFrontCenter
 SG_ RFC_Obj10_PxVxCoVnce : 284|12@1+ (0.01,0) [0|30] "m^2/s"  VideoFrontCenter
 SG_ RFC_Obj10_PxVyCoVnce : 296|12@1+ (0.01,0) [0|30] "m^2/s"  VideoFrontCenter
 SG_ RFC_Obj10_PyVxCoVnce : 308|12@1+ (0.01,0) [0|30] "m^2/s"  VideoFrontCenter
 SG_ RFC_Obj10_PyVyCoVnce : 320|12@1+ (0.01,0) [0|30] "m^2/s"  VideoFrontCenter
 SG_ RFC_Obj10_VxVyCoVnce : 332|12@1+ (0.01,0) [0|30] "m^2/s^2"  VideoFrontCenter
 SG_ RFC_Obj10_PxAxCoVnce : 344|12@1+ (0.01,0) [0|30] "m^2/s^2"  VideoFrontCenter
 SG_ RFC_Obj10_PxAyCoVnce : 356|12@1+ (0.01,0) [0|30] "m^2/s^2"  VideoFrontCenter
 SG_ RFC_Obj10_PyAxCoVnce : 368|12@1+ (0.01,0) [0|30] "m^2/s^2"  VideoFrontCenter
 SG_ RFC_Obj10_PyAyCoVnce : 380|12@1+ (0.01,0) [0|30] "m^2/s^2"  VideoFrontCenter
 SG_ RFC_Obj10_VxAxCoVnce : 392|12@1+ (0.01,0) [0|30] "m^2/s^3"  VideoFrontCenter
 SG_ RFC_Obj10_VxAyCoVnce : 404|12@1+ (0.01,0) [0|30] "m^2/s^3"  VideoFrontCenter
 SG_ RFC_Obj10_VyAxCoVnce : 416|12@1+ (0.01,0) [0|30] "m^2/s^3"  VideoFrontCenter
 SG_ RFC_Obj10_VyAyCoVnce : 428|12@1+ (0.01,0) [0|30] "m^2/s^3"  VideoFrontCenter
 SG_ RFC_Obj10_AxAyCoVnce : 440|12@1+ (0.01,0) [0|30] "m^2/s^4"  VideoFrontCenter
 SG_ RFC_Obj10_MobileObstConf : 452|6@1+ (2,0) [0|100] "%"  VideoFrontCenter
 SG_ RFC_Obj10_Mob4PlusWhlConf : 458|6@1+ (2,0) [0|100] "%"  VideoFrontCenter
 SG_ RFC_Obj10_Mob2WhlConf : 464|6@1+ (2,0) [0|100] "%"  VideoFrontCenter
 SG_ RFC_Obj10_MobPedConf : 470|6@1+ (2,0) [0|100] "%"  VideoFrontCenter
 SG_ RFC_Obj10_FourPlusWhlCarConf : 476|6@1+ (2,0) [0|100] "%"  VideoFrontCenter
 SG_ RFC_Obj10_FourPlusWhlHGVConf : 482|6@1+ (2,0) [0|100] "%"  VideoFrontCenter
 SG_ RFC_Obj10_GroundReflexConf : 488|6@1+ (2,0) [0|100] "%"  VideoFrontCenter
 SG_ RFC_Obj10_StatObstConf : 494|6@1+ (2,0) [0|100] "%"  VideoFrontCenter
 SG_ RFC_Obj10_StatBarrierConf : 500|6@1+ (2,0) [0|100] "%"  VideoFrontCenter

BO_ 417 RFC_Obj11: 64 RadarFrontCenter
 SG_ RFC_Obj11_CRC : 0|16@1+ (1,0) [0|65535] ""  VideoFrontCenter
 SG_ RFC_Obj11_AliveCtr : 16|8@1+ (1,0) [0|255] ""  VideoFrontCenter
 SG_ RFC_Obj11_ProtBlockCtr : 24|4@1+ (1,0) [0|15] ""  VideoFrontCenter
 SG_ RFC_Obj11_ReferencePoint : 28|4@1+ (1,0) [0|15] ""  VideoFrontCenter
 SG_ RFC_Obj11_ObjId : 32|7@1+ (1,0) [0|127] ""  VideoFrontCenter
 SG_ RFC_Obj11_MeasurementStatus : 39|1@1+ (1,0) [0|1] ""  VideoFrontCenter
 SG_ RFC_Obj11_Px : 40|13@1+ (0.0625,-256) [-256|255.9375] "m"  VideoFrontCenter
 SG_ RFC_Obj11_Py : 53|11@1+ (0.125,-128) [-128|127.875] "m"  VideoFrontCenter
 SG_ RFC_Obj11_PxVnce : 64|12@1+ (0.01,0) [0|30] "m^2"  VideoFrontCenter
 SG_ RFC_Obj11_PyVnce : 76|12@1+ (0.01,0) [0|30] "m^2"  VideoFrontCenter
 SG_ RFC_Obj11_Vx : 88|12@1+ (0.0625,-128) [-128|127.9375] "m/s"  VideoFrontCenter
 SG_ RFC_Obj11_Vy : 100|10@1+ (0.125,-64) [-64|63.875] "m/s"  VideoFrontCenter
 SG_ RFC_Obj11_Ax : 110|10@1+ (0.03125,-16) [-16|15.96875] "m/s^2"  VideoFrontCenter
 SG_ RFC_Obj11_Ay : 120|9@1+ (0.0625,-16) [-16|15.9375] "m/s^2"  VideoFrontCenter
 SG_ RFC_Obj11_OrientationYaw : 129|9@1+ (0.0175,-4.48) [-3.15|3.15] "rad"  VideoFrontCenter
 SG_ RFC_Obj11_ExistProb : 138|6@1+ (2,0) [0|100] "%"  VideoFrontCenter
 SG_ RFC_Obj11_VxVnce : 144|12@1+ (0.01,0) [0|30] "m^2/s^2"  VideoFrontCenter
 SG_ RFC_Obj11_VyVnce : 156|12@1+ (0.01,0) [0|30] "m^2/s^2"  VideoFrontCenter
 SG_ RFC_Obj11_AxVnce : 168|12@1+ (0.01,0) [0|30] "m^2/s^4"  VideoFrontCenter
 SG_ RFC_Obj11_AyVnce : 180|12@1+ (0.01,0) [0|30] "m^2/s^4"  VideoFrontCenter
 SG_ RFC_Obj11_OrientationYawVnce : 192|12@1+ (0.0003,0) [0|1] "rad^2"  VideoFrontCenter
 SG_ RFC_Obj11_MovingObserved : 204|6@1+ (2,0) [0|100] "%"  VideoFrontCenter
 SG_ RFC_Obj11_MovingProbability : 210|6@1+ (2,0) [0|100] "%"  VideoFrontCenter
 SG_ RFC_Obj11_Length : 216|7@1+ (0.125,0) [0|15.875] "m"  VideoFrontCenter
 SG_ RFC_Obj11_Valid : 223|1@1+ (1,0) [0|1] ""  VideoFrontCenter
 SG_ RFC_Obj11_LengthVnce : 224|12@1+ (0.01,0) [0|30] "m^2"  VideoFrontCenter
 SG_ RFC_Obj11_WidthVnce : 236|12@1+ (0.01,0) [0|30] "m^2"  VideoFrontCenter
 SG_ RFC_Obj11_Width : 248|7@1+ (0.125,0) [0|15.875] "m"  VideoFrontCenter
 SG_ RFC_Obj11_BehaviorType : 255|3@1+ (1,0) [0|7] ""  VideoFrontCenter
 SG_ RFC_Obj11_ObstacleConf : 258|6@1+ (2,0) [0|100] "%"  VideoFrontCenter
 SG_ RFC_Obj11_NonObstacleConf : 264|6@1+ (2,0) [0|100] "%"  VideoFrontCenter
 SG_ RFC_Obj11_PxPyCoVnce : 272|12@1+ (0.01,0) [0|30] "m^2"  VideoFrontCenter
 SG_ RFC_Obj11_PxVxCoVnce : 284|12@1+ (0.01,0) [0|30] "m^2/s"  VideoFrontCenter
 SG_ RFC_Obj11_PxVyCoVnce : 296|12@1+ (0.01,0) [0|30] "m^2/s"  VideoFrontCenter
 SG_ RFC_Obj11_PyVxCoVnce : 308|12@1+ (0.01,0) [0|30] "m^2/s"  VideoFrontCenter
 SG_ RFC_Obj11_PyVyCoVnce : 320|12@1+ (0.01,0) [0|30] "m^2/s"  VideoFrontCenter
 SG_ RFC_Obj11_VxVyCoVnce : 332|12@1+ (0.01,0) [0|30] "m^2/s^2"  VideoFrontCenter
 SG_ RFC_Obj11_PxAxCoVnce : 344|12@1+ (0.01,0) [0|30] "m^2/s^2"  VideoFrontCenter
 SG_ RFC_Obj11_PxAyCoVnce : 356|12@1+ (0.01,0) [0|30] "m^2/s^2"  VideoFrontCenter
 SG_ RFC_Obj11_PyAxCoVnce : 368|12@1+ (0.01,0) [0|30] "m^2/s^2"  VideoFrontCenter
 SG_ RFC_Obj11_PyAyCoVnce : 380|12@1+ (0.01,0) [0|30] "m^2/s^2"  VideoFrontCenter
 SG_ RFC_Obj11_VxAxCoVnce : 392|12@1+ (0.01,0) [0|30] "m^2/s^3"  VideoFrontCenter
 SG_ RFC_Obj11_VxAyCoVnce : 404|12@1+ (0.01,0) [0|30] "m^2/s^3"  VideoFrontCenter
 SG_ RFC_Obj11_VyAxCoVnce : 416|12@1+ (0.01,0) [0|30] "m^2/s^3"  VideoFrontCenter
 SG_ RFC_Obj11_VyAyCoVnce : 428|12@1+ (0.01,0) [0|30] "m^2/s^3"  VideoFrontCenter
 SG_ RFC_Obj11_AxAyCoVnce : 440|12@1+ (0.01,0) [0|30] "m^2/s^4"  VideoFrontCenter
 SG_ RFC_Obj11_MobileObstConf : 452|6@1+ (2,0) [0|100] "%"  VideoFrontCenter
 SG_ RFC_Obj11_Mob4PlusWhlConf : 458|6@1+ (2,0) [0|100] "%"  VideoFrontCenter
 SG_ RFC_Obj11_Mob2WhlConf : 464|6@1+ (2,0) [0|100] "%"  VideoFrontCenter
 SG_ RFC_Obj11_MobPedConf : 470|6@1+ (2,0) [0|100] "%"  VideoFrontCenter
 SG_ RFC_Obj11_FourPlusWhlCarConf : 476|6@1+ (2,0) [0|100] "%"  VideoFrontCenter
 SG_ RFC_Obj11_FourPlusWhlHGVConf : 482|6@1+ (2,0) [0|100] "%"  VideoFrontCenter
 SG_ RFC_Obj11_GroundReflexConf : 488|6@1+ (2,0) [0|100] "%"  VideoFrontCenter
 SG_ RFC_Obj11_StatObstConf : 494|6@1+ (2,0) [0|100] "%"  VideoFrontCenter
 SG_ RFC_Obj11_StatBarrierConf : 500|6@1+ (2,0) [0|100] "%"  VideoFrontCenter

CM_ SG_ 16 VFC_AEB_CRC "CRC - E2E Profile decision by customer project. Possible options: AUTOSAR Profile 1A,1B,1C,2,11A,11C,22, OEM specified E2E profile (Platform proposal Profile 22)";
CM_ SG_ 16 VFC_AEB_AC "Alive Counter - E2E Profile decision by customer project. Possible options: AUTOSAR Profile 1A,1B,1C,2,11A,11C,22, OEM specified E2E profile (Platform proposal Profile 22)";
CM_ SG_ 16 VFC_AEB_FPC "Trigger recommendation of AEB FPC (Front Pre Crash)";
CM_ SG_ 16 VFC_AEB_CU "Trigger recommendations of AEB CU (CityUrban)
Bit 0 : AEB_CU_EMERGENCY_BRAKE 
Bit 1 : AEB_CU_WARNING
Bit 2 : AEB_CU_EBA_REACTION
Bit 3 : AEB_CU_PREFILL
Bit 4 : AEB_CU_HAPTIC
Bit 5 : AEB_CU_PARTIAL_BRAKE";
CM_ SG_ 16 VFC_AEB_VRU "Trigger recommendations of AEB VRU (Vulnerable Road User)
Bit 0 : AEB_VRU_EMERGENCY_BRAKE
Bit 1 : AEB_VRU_WARNINGÂ 
Bit 2 : AEB_VRU_PREFILL
Bit 3 : AEB_VRU_EBA_REACTION
Bit 4 : AEB_VRU_HAPTIC";
CM_ SG_ 16 VFC_AEB_VRUTA "Trigger recommendations of AEB VRUTA (Vulnerable Road User Turning Assist)
Bit 0 :  AEB_VRUTA_EMERGENCY_BRAKE
Bit 1 :  AEB_VRUTA_WARNING 
Bit 2 :  AEB_VRUTA_EBA_REACTION
Bit 3 :  AEB_VRUTA_PREFILL
Bit 4 :  AEB_VRUTA_HAPTIC";
CM_ SG_ 16 VFC_AEB_LTA "Trigger recommendations of AEB LTA (Left Turn Assist)
Bit 0 : AEB_LTA_EMERGENCY_BRAKE
Bit 1 : AEB_LTA_WARNING 
Bit 2 : AEB_LTA_EBA_REACTION
Bit 3 : AEB_LTA_PREFILL
Bit 4 : AEB_LTA_HAPTIC";
CM_ SG_ 16 VFC_AEB_ObjID "Object ID of AEB event";
CM_ SG_ 19 RFL_AEB_CRC "CRC - E2E Profile decision by customer project. Possible options: AUTOSAR Profile 1A,1B,1C,2,11A,11C,22, OEM specified E2E profile (Platform proposal Profile 22)";
CM_ SG_ 19 RFL_AEB_AC "Alive Counter - E2E Profile decision by customer project. Possible options: AUTOSAR Profile 1A,1B,1C,2,11A,11C,22, OEM specified E2E profile (Platform proposal Profile 22)";
CM_ SG_ 19 RFL_AEB_FPC "Trigger recommendation of AEB FPC (Front Pre Crash)";
CM_ SG_ 19 RFL_AEB_CU "Trigger recommendations of AEB CU (CityUrban)
Bit 0 : AEB_CU_EMERGENCY_BRAKE 
Bit 1 : AEB_CU_WARNING
Bit 2 : AEB_CU_EBA_REACTION
Bit 3 : AEB_CU_PREFILL
Bit 4 : AEB_CU_HAPTIC
Bit 5 : AEB_CU_PARTIAL_BRAKE";
CM_ SG_ 19 RFL_AEB_VRU "Trigger recommendations of AEB VRU (Vulnerable Road User)
Bit 0 : AEB_VRU_EMERGENCY_BRAKE
Bit 1 : AEB_VRU_WARNINGÂ 
Bit 2 : AEB_VRU_PREFILL
Bit 3 : AEB_VRU_EBA_REACTION
Bit 4 : AEB_VRU_HAPTIC";
CM_ SG_ 19 RFL_AEB_VRUTA "Trigger recommendations of AEB VRUTA (Vulnerable Road User Turning Assist)
Bit 0 :  AEB_VRUTA_EMERGENCY_BRAKE
Bit 1 :  AEB_VRUTA_WARNING 
Bit 2 :  AEB_VRUTA_EBA_REACTION
Bit 3 :  AEB_VRUTA_PREFILL
Bit 4 :  AEB_VRUTA_HAPTIC";
CM_ SG_ 19 RFL_AEB_LTA "Trigger recommendations of AEB LTA (Left Turn Assist)
Bit 0 : AEB_LTA_EMERGENCY_BRAKE
Bit 1 : AEB_LTA_WARNING 
Bit 2 : AEB_LTA_EBA_REACTION
Bit 3 : AEB_LTA_PREFILL
Bit 4 : AEB_LTA_HAPTIC";
CM_ SG_ 19 RFL_AEB_ObjID "Object ID of AEB event";
CM_ SG_ 20 RFR_AEB_CRC "CRC - E2E Profile decision by customer project. Possible options: AUTOSAR Profile 1A,1B,1C,2,11A,11C,22, OEM specified E2E profile (Platform proposal Profile 22)";
CM_ SG_ 20 RFR_AEB_AC "Alive Counter - E2E Profile decision by customer project. Possible options: AUTOSAR Profile 1A,1B,1C,2,11A,11C,22, OEM specified E2E profile (Platform proposal Profile 22)";
CM_ SG_ 20 RFR_AEB_FPC "Trigger recommendation of AEB FPC (Front Pre Crash)";
CM_ SG_ 20 RFR_AEB_CU "Trigger recommendations of AEB CU (CityUrban)
Bit 0 : AEB_CU_EMERGENCY_BRAKE 
Bit 1 : AEB_CU_WARNING
Bit 2 : AEB_CU_EBA_REACTION
Bit 3 : AEB_CU_PREFILL
Bit 4 : AEB_CU_HAPTIC
Bit 5 : AEB_CU_PARTIAL_BRAKE";
CM_ SG_ 20 RFR_AEB_VRU "Trigger recommendations of AEB VRU (Vulnerable Road User)
Bit 0 : AEB_VRU_EMERGENCY_BRAKE
Bit 1 : AEB_VRU_WARNINGÂ 
Bit 2 : AEB_VRU_PREFILL
Bit 3 : AEB_VRU_EBA_REACTION
Bit 4 : AEB_VRU_HAPTIC";
CM_ SG_ 20 RFR_AEB_VRUTA "Trigger recommendations of AEB VRUTA (Vulnerable Road User Turning Assist)
Bit 0 :  AEB_VRUTA_EMERGENCY_BRAKE
Bit 1 :  AEB_VRUTA_WARNING 
Bit 2 :  AEB_VRUTA_EBA_REACTION
Bit 3 :  AEB_VRUTA_PREFILL
Bit 4 :  AEB_VRUTA_HAPTIC";
CM_ SG_ 20 RFR_AEB_LTA "Trigger recommendations of AEB LTA (Left Turn Assist)
Bit 0 : AEB_LTA_EMERGENCY_BRAKE
Bit 1 : AEB_LTA_WARNING 
Bit 2 : AEB_LTA_EBA_REACTION
Bit 3 : AEB_LTA_PREFILL
Bit 4 : AEB_LTA_HAPTIC";
CM_ SG_ 20 RFR_AEB_ObjID "Object ID of AEB event";
CM_ SG_ 32 VFC_Status_CRC "CRC - Autosar E2E Profile 5";
CM_ SG_ 32 VFC_Status_AliveCtr "Alive counter - Autosar E2E Profile 5";
CM_ SG_ 32 VFC_Status_SensorOrientYaw "The calibrated yaw angle of the camera. Only similar to ISO 23150:2023: Sensor orientation {yaw} - header (A.1.23) but with high dynamic orientation estimation";
CM_ SG_ 32 VFC_Status_SensorOrientPitch "The calibrated pitch angle of the camera ISO 23150:2023: Sensor orientation {pitch} - header (A.1.23) but with high dynamic orientation estimation";
CM_ SG_ 32 VFC_Status_SensorOrientRoll "The calibrated roll angle of the camera ISO 23150:2023: Sensor orientation {roll} - header (A.1.23) but with high dynamic orientation estimation";
CM_ SG_ 32 VFC_Status_TimeStampStatus "Autosar StbM_TimeBaseStatusType bitfield with extension:
Bit 0: TIMEOUT
Bit 1: Reserved1
Bit 2: SYNC_TO_GATEWAY
Bit 3: GLOBAL_TIME_BASE
Bit 4: TIMELEAP_FUTURE
Bit 5: TIMELEAP_PAST
Bit 6: Reserved6
Bit 7: Extension: GENERAL_ERROR";
CM_ SG_ 32 VFC_Status_TimeStamp "TimeStamp of frame ISO 23150:2023: Time stamp - measurement (A.1.5.2)";
CM_ SG_ 32 VFC_Status_FrameNumber "The frame number that the data belongs to";
CM_ SG_ 32 VFC_Status_SensorOriginPointX "The current estimation of mounting position of the camera in the longitudinal direction, similar to ISO 23150:2023: Sensor origin point {X} - header (A.1.21) but contains only the initial calibration value";
CM_ SG_ 32 VFC_Status_SensorOriginPointY "The current estimation of mounting position of the camera in the lateral direction similar to ISO 23150:2023: Sensor origin point {y} - header (A.1.21) but contains only the initial calibration value";
CM_ SG_ 32 VFC_Status_SensorOriginPointZ "The current estimation of mounting position of the camera in the vertical direction similar to ISO 23150:2023: Sensor origin point {z} - header (A.1.21) but contains only the initial calibration value";
CM_ SG_ 32 VFC_Status_RollerBenchState "The state of the roller bench test mode";
CM_ SG_ 32 VFC_Status_SensorState "The current state of the camera system";
CM_ SG_ 32 VFC_Status_CalibrationState "The calibration state of the camera system";
CM_ SG_ 32 VFC_Status_TrafficFlowType "ISO 23150:2023: Current traffic flow type (A.6.51)";
CM_ SG_ 33 RFC_Status_CRC "CRC - E2E Profile decision by customer project. Possible options: AUTOSAR Profile 1A,1B,1C,2,11A,11C,22, OEM specified E2E profile (Platform proposal Profile 22)";
CM_ SG_ 33 RFC_Status_AliveCtr "Alive counter - E2E Profile decision by customer project. Possible options: AUTOSAR Profile 1A,1B,1C,2,11A,11C,22, OEM specified E2E profile (Platform proposal Profile 22)";
CM_ SG_ 33 RFC_Status_ModulationStatus "Reflect if there is any problem with the modulation of the radar";
CM_ SG_ 33 RFC_Status_SensorStatus "Bit 0: HW MALFUNCTION
Bit 1: DSP ISSUES
Bit 2: COMMUNICATION ERRORS
Bit 3: MISALIGNMENT (OUT OF SPEC)
Bit 4: SENSOR BLIDNESS DETECTED
Bit 5: SENSOR DISTURBED
Bit 6: OTHER ISSUES
Bit 7: RESERVED
Value 0: no event
Value 1: event occured";
CM_ SG_ 35 RFL_Status_CRC "CRC - E2E Profile decision by customer project. Possible options: AUTOSAR Profile 1A,1B,1C,2,11A,11C,22, OEM specified E2E profile (Platform proposal Profile 22)";
CM_ SG_ 35 RFL_Status_AliveCtr "Alive counter - E2E Profile decision by customer project. Possible options: AUTOSAR Profile 1A,1B,1C,2,11A,11C,22, OEM specified E2E profile (Platform proposal Profile 22)";
CM_ SG_ 35 RFL_Status_ModulationStatus "Reflect if there is any problem with the modulation of the radar";
CM_ SG_ 35 RFL_Status_SensorStatus "Bit 0: HW MALFUNCTION
Bit 1: DSP ISSUES
Bit 2: COMMUNICATION ERRORS
Bit 3: MISALIGNMENT (OUT OF SPEC)
Bit 4: SENSOR BLIDNESS DETECTED
Bit 5: SENSOR DISTURBED
Bit 6: OTHER ISSUES
Bit 7: RESERVED
Value 0: no event
Value 1: event occured";
CM_ SG_ 36 RFR_Status_CRC "CRC - E2E Profile decision by customer project. Possible options: AUTOSAR Profile 1A,1B,1C,2,11A,11C,22, OEM specified E2E profile (Platform proposal Profile 22)";
CM_ SG_ 36 RFR_Status_AliveCtr "Alive counter - E2E Profile decision by customer project. Possible options: AUTOSAR Profile 1A,1B,1C,2,11A,11C,22, OEM specified E2E profile (Platform proposal Profile 22)";
CM_ SG_ 36 RFR_Status_ModulationStatus "Reflect if there is any problem with the modulation of the radar";
CM_ SG_ 36 RFR_Status_SensorStatus "Bit 0: HW MALFUNCTION
Bit 1: DSP ISSUES
Bit 2: COMMUNICATION ERRORS
Bit 3: MISALIGNMENT (OUT OF SPEC)
Bit 4: SENSOR BLIDNESS DETECTED
Bit 5: SENSOR DISTURBED
Bit 6: OTHER ISSUES
Bit 7: RESERVED
Value 0: no event
Value 1: event occured";
CM_ SG_ 404 RFC_ObjHdr_CRC "CRC - Autosar E2E Profile 5";
CM_ SG_ 404 RFC_ObjHdr_AliveCtr "Alive counter - Autosar E2E Profile 5";
CM_ SG_ 404 RFC_ObjHdr_ProtBlockCtr "Protocol-Signal: Block-Counter";
CM_ SG_ 404 RFC_ObjHdr_IfVersionIdMajor "Version information of the interface. e. g. version 1.0: Major = 1. ISO 23150: Interface version ID {major, minor, patch} (A.1.1)";
CM_ SG_ 404 RFC_ObjHdr_IfVersionIdMinor "Version information of the interface. e. g. version 1.0: Minor = 0. ISO 23150: Interface version ID {major, minor, patch} (A.1.1)";
CM_ SG_ 404 RFC_ObjHdr_NumValidObjects "number of detected VALID Objects that have been sent to the bus. ISO 23150: Number of valid potentially moving objects (A.1.12.1)";
CM_ SG_ 404 RFC_ObjHdr_TimeStampStatus "Autosar StbM_TimeBaseStatusType bitfield with extension:
Bit 0: TIMEOUT
Bit 1: Reserved1
Bit 2: SYNC_TO_GATEWAY
Bit 3: GLOBAL_TIME_BASE
Bit 4: TIMELEAP_FUTURE
Bit 5: TIMELEAP_PAST
Bit 6: Reserved6
Bit 7: Extension: GENERAL_ERROR";
CM_ SG_ 404 RFC_ObjHdr_TimeStamp "Time Stamp. ISO 23150: Time stamp  predicted (A.1.5.1)";
CM_ SG_ 404 RFC_ObjHdr_SensorState "Bit 0: HW MALFUNCTION
Bit 1: DSP ISSUES
Bit 2: COMMUNICATION ERRORS
Bit 3: MISALIGNMENT (OUT OF SPEC)
Bit 4: SENSOR BLIDNESS DETECTED
Bit 5: SENSOR DISTURBED
Bit 6: OTHER ISSUES
Bit 7: RESERVED
Value 0: no event
Value 1: event occured";
CM_ SG_ 404 RFC_ObjHdr_AziOutOfSpec "The sensor was detected to be out-of-spec due to misalignment in azimuth";
CM_ SG_ 404 RFC_ObjHdr_ElevOutOfSpec "The sensor was detected to be out-of-spec due to misalignment in elevation";
CM_ SG_ 404 RFC_ObjHdr_ObjectDownSel "the detected number of objects exceeded the number of max. objects that can be transmitted";
CM_ SG_ 404 RFC_ObjHdr_SensorOriginPointY "Position of origin of sensor in lateral direction relative to mid axis of vehicle. ISO 23150: Sensor origin point {x, y, z} (A.1.22)";
CM_ SG_ 404 RFC_ObjHdr_SensorOriginPointX "Position of origin of sensor in longitudinal direction relative to rear axis of vehicle. ISO 23150: Sensor origin point {x, y, z} (A.1.22)";
CM_ SG_ 404 RFC_ObjHdr_SensorOriginPointZ "Position of origin of sensor in elevation direction relative to ground. ISO 23150: Sensor origin point {x, y, z} (A.1.22)";
CM_ SG_ 404 RFC_ObjHdr_SensorOrientYaw "angle between sensor mounting direction and vehicle longitudinal axis, Azimuth. ISO 23150: Sensor orientation {yaw, pitch, roll} (A.1.24)";
CM_ SG_ 404 RFC_ObjHdr_SensorOrientPitch "angle between sensor mounting direction and vehicle longitudinal axis, Elevation. ISO 23150: Sensor orientation {yaw, pitch, roll} (A.1.24)";
CM_ SG_ 404 RFC_ObjHdr_SensorOrientRoll "Tilt of the mounting sensor. ISO 23150: Sensor orientation {yaw, pitch, roll} (A.1.24)";
CM_ SG_ 404 RFC_ObjHdr_FovAzimuthBegin "Lower angle of the fied of view Azimuth. ISO 23150: Segment azimuth {begin, end} (A.5.1)";
CM_ SG_ 404 RFC_ObjHdr_FovAzimuthEnd "Upper angle of the field of view Azimuth. ISO 23150: Segment azimuth {begin, end} (A.5.1)";
CM_ SG_ 404 RFC_ObjHdr_FovElevationBegin "Lower angle of the fied of view Elevation. ISO 23150: Segment elevation {begin, end} (A.5.2)";
CM_ SG_ 404 RFC_ObjHdr_FovElevationEnd "Upper angle of the field of view Elevation. ISO 23150: Segment elevation {begin, end} (A.5.2)";
CM_ SG_ 404 RFC_ObjHdr_DetectionRange "Estimated detection range of the sensor";
CM_ SG_ 404 RFC_ObjHdr_TimeStampLocal "Local Time Stamp";
CM_ SG_ 406 RFC_Obj00_CRC "CRC - Autosar E2E Profile 5";
CM_ SG_ 406 RFC_Obj00_AliveCtr "Alive counter - Autosar E2E Profile 5";
CM_ SG_ 406 RFC_Obj00_ProtBlockCtr "Protocol-Signal: Block-Counter";
CM_ SG_ 406 RFC_Obj00_ReferencePoint "Reference Point of the detected object. ISO 23150: Reference point (A.2.17)";
CM_ SG_ 406 RFC_Obj00_ObjId "Unique Object ID. ISO 23150: Object ID (A.2.2)";
CM_ SG_ 406 RFC_Obj00_MeasurementStatus "Object is measured or not. ISO 23150: Measurement status  object level (A.2.9)";
CM_ SG_ 406 RFC_Obj00_Px "Object position in X direction. ISO 23150: Position  object level {x, y, z} (A.2.13)";
CM_ SG_ 406 RFC_Obj00_Py "Object position in Y direction. ISO 23150: Position  object level {x, y, z} (A.2.13)";
CM_ SG_ 406 RFC_Obj00_PxVnce "Variance of object position in X direction. ISO 23150: Position  object level {x, y, z}  error (A.2.14)";
CM_ SG_ 406 RFC_Obj00_PyVnce "Variance of object position in Y direction. ISO 23150: Position  object level {x, y, z}  error (A.2.14)";
CM_ SG_ 406 RFC_Obj00_Vx "Object relative velocity in X direction. ISO 23150: Velocity {x, y, z}  object level (A.2.23)";
CM_ SG_ 406 RFC_Obj00_Vy "Object relative velocity in Y direction. ISO 23150: Velocity {x, y, z}  object level (A.2.23)";
CM_ SG_ 406 RFC_Obj00_Ax "Object relative acceleration in X direction. ISO 23150: Acceleration {x, y, z} (A.2.25)";
CM_ SG_ 406 RFC_Obj00_Ay "Object relative acceleration in Y direction. ISO 23150: Acceleration {x, y, z} (A.2.25)";
CM_ SG_ 406 RFC_Obj00_OrientationYaw "Object orientation yaw angle. ISO 23150: Orientation {yaw, pitch, roll} (A.2.15)";
CM_ SG_ 406 RFC_Obj00_ExistProb "Existence probability of object. ISO 23150: Existence probability  object level (A.2.1)";
CM_ SG_ 406 RFC_Obj00_VxVnce "Variance of object relative velocity in X direction. ISO 23150: Velocity {x, y, z}  object level  error (A.2.24)";
CM_ SG_ 406 RFC_Obj00_VyVnce "Variance of object relative velocity in Y direction. ISO 23150: Velocity {x, y, z}  object level  error (A.2.24)";
CM_ SG_ 406 RFC_Obj00_AxVnce "Variance of object relative acceleration in X direction. ISO 23150: Acceleration {x, y, z}  error (A.2.26)";
CM_ SG_ 406 RFC_Obj00_AyVnce "Variance of object relative acceleration in Y direction. ISO 23150: Acceleration {x, y, z}  error (A.2.26)";
CM_ SG_ 406 RFC_Obj00_OrientationYawVnce "Variance of object orientation yaw angle. ISO 23150: Orientation {yaw, pitch, roll}  error (A.2.16)";
CM_ SG_ 406 RFC_Obj00_MovingObserved "Object has been observed moving over the ground since it was first detected";
CM_ SG_ 406 RFC_Obj00_MovingProbability "Object has been observed moving over the ground";
CM_ SG_ 406 RFC_Obj00_Length "Object Length. ISO 23150: Bounding box extent {length, width, height} (A.2.19)";
CM_ SG_ 406 RFC_Obj00_Valid "Object is valid or not";
CM_ SG_ 406 RFC_Obj00_LengthVnce "Variance of object Length. ISO 23150: Bounding box extent {length, width, height}  error (A.2.20)";
CM_ SG_ 406 RFC_Obj00_WidthVnce "Variance of object Width. ISO 23150: Bounding box extent {length, width, height}  error (A.2.20)";
CM_ SG_ 406 RFC_Obj00_Width "Object Width. ISO 23150: Bounding box extent {length, width, height} (A.2.19)";
CM_ SG_ 406 RFC_Obj00_BehaviorType "Indicates that which behavior the object associated for";
CM_ SG_ 406 RFC_Obj00_ObstacleConf "Confidence of the object being an Obstacle. ISO 23150: Potentially moving object classification type  confidence (A.2.12)";
CM_ SG_ 406 RFC_Obj00_NonObstacleConf "Confidence of the object being a Non-Obstacle. ISO 23150: Potentially moving object classification type  confidence (A.2.12)";
CM_ SG_ 406 RFC_Obj00_PxPyCoVnce "Covariance of Px and Py";
CM_ SG_ 406 RFC_Obj00_PxVxCoVnce "Covariance of Px and Vx";
CM_ SG_ 406 RFC_Obj00_PxVyCoVnce "Covariance of Px and Vy";
CM_ SG_ 406 RFC_Obj00_PyVxCoVnce "Covariance of Py and Vx";
CM_ SG_ 406 RFC_Obj00_PyVyCoVnce "Covariance of Py and Vy";
CM_ SG_ 406 RFC_Obj00_VxVyCoVnce "Covariance of Vx and Vy";
CM_ SG_ 406 RFC_Obj00_PxAxCoVnce "Covariance of Px and Ax";
CM_ SG_ 406 RFC_Obj00_PxAyCoVnce "Covariance of Px and Ay";
CM_ SG_ 406 RFC_Obj00_PyAxCoVnce "Covariance of Py and Ax";
CM_ SG_ 406 RFC_Obj00_PyAyCoVnce "Covariance of Py and Ay";
CM_ SG_ 406 RFC_Obj00_VxAxCoVnce "Covariance of Vx and Ax";
CM_ SG_ 406 RFC_Obj00_VxAyCoVnce "Covariance of Vx and Ay";
CM_ SG_ 406 RFC_Obj00_VyAxCoVnce "Covariance of Vy and Ax";
CM_ SG_ 406 RFC_Obj00_VyAyCoVnce "Covariance of Vy and Ay";
CM_ SG_ 406 RFC_Obj00_AxAyCoVnce "Covariance of Ax and Ay";
CM_ SG_ 406 RFC_Obj00_MobileObstConf "Confidence of the object being a mobile obstacle. ISO 23150: Potentially moving object classification type  confidence (A.2.12)";
CM_ SG_ 406 RFC_Obj00_Mob4PlusWhlConf "Confidence of a mobile object which has 4 or more wheels. ISO 23150: Potentially moving object classification type  confidence (A.2.12)";
CM_ SG_ 406 RFC_Obj00_Mob2WhlConf "Confidence of a mobile object being 2-wheels vehicle. ISO 23150: Potentially moving object classification type  confidence (A.2.12)";
CM_ SG_ 406 RFC_Obj00_MobPedConf "Confidence of a mobile object being a pedestrian. ISO 23150: Potentially moving object classification type  confidence (A.2.12)";
CM_ SG_ 406 RFC_Obj00_FourPlusWhlCarConf "Confidence of a mobile object which has 4 or more wheels--passenger car. ISO 23150: Potentially moving object classification type  confidence (A.2.12)";
CM_ SG_ 406 RFC_Obj00_FourPlusWhlHGVConf "Confidence of a mobile object which has 4 or more wheels--commercial vehicle (Truck). ISO 23150: Potentially moving object classification type  confidence (A.2.12)";
CM_ SG_ 406 RFC_Obj00_GroundReflexConf "Confidence of the object being a ground reflex. ISO 23150: Potentially moving object classification type  confidence (A.2.12)";
CM_ SG_ 406 RFC_Obj00_StatObstConf "Confidence of the object being a stationary obstacle. ISO 23150: Potentially moving object classification type  confidence (A.2.12)";
CM_ SG_ 406 RFC_Obj00_StatBarrierConf "Confidence of the object being a stationary road barrier. ISO 23150: Potentially moving object classification type  confidence (A.2.12)";
CM_ SG_ 407 RFC_Obj01_CRC "CRC - Autosar E2E Profile 5";
CM_ SG_ 407 RFC_Obj01_AliveCtr "Alive counter - Autosar E2E Profile 5";
CM_ SG_ 407 RFC_Obj01_ProtBlockCtr "Protocol-Signal: Block-Counter";
CM_ SG_ 407 RFC_Obj01_ReferencePoint "Reference Point of the detected object. ISO 23150: Reference point (A.2.17)";
CM_ SG_ 407 RFC_Obj01_ObjId "Unique Object ID. ISO 23150: Object ID (A.2.2)";
CM_ SG_ 407 RFC_Obj01_MeasurementStatus "Object is measured or not. ISO 23150: Measurement status  object level (A.2.9)";
CM_ SG_ 407 RFC_Obj01_Px "Object position in X direction. ISO 23150: Position  object level {x, y, z} (A.2.13)";
CM_ SG_ 407 RFC_Obj01_Py "Object position in Y direction. ISO 23150: Position  object level {x, y, z} (A.2.13)";
CM_ SG_ 407 RFC_Obj01_PxVnce "Variance of object position in X direction. ISO 23150: Position  object level {x, y, z}  error (A.2.14)";
CM_ SG_ 407 RFC_Obj01_PyVnce "Variance of object position in Y direction. ISO 23150: Position  object level {x, y, z}  error (A.2.14)";
CM_ SG_ 407 RFC_Obj01_Vx "Object relative velocity in X direction. ISO 23150: Velocity {x, y, z}  object level (A.2.23)";
CM_ SG_ 407 RFC_Obj01_Vy "Object relative velocity in Y direction. ISO 23150: Velocity {x, y, z}  object level (A.2.23)";
CM_ SG_ 407 RFC_Obj01_Ax "Object relative acceleration in X direction. ISO 23150: Acceleration {x, y, z} (A.2.25)";
CM_ SG_ 407 RFC_Obj01_Ay "Object relative acceleration in Y direction. ISO 23150: Acceleration {x, y, z} (A.2.25)";
CM_ SG_ 407 RFC_Obj01_OrientationYaw "Object orientation yaw angle. ISO 23150: Orientation {yaw, pitch, roll} (A.2.15)";
CM_ SG_ 407 RFC_Obj01_ExistProb "Existence probability of object. ISO 23150: Existence probability  object level (A.2.1)";
CM_ SG_ 407 RFC_Obj01_VxVnce "Variance of object relative velocity in X direction. ISO 23150: Velocity {x, y, z}  object level  error (A.2.24)";
CM_ SG_ 407 RFC_Obj01_VyVnce "Variance of object relative velocity in Y direction. ISO 23150: Velocity {x, y, z}  object level  error (A.2.24)";
CM_ SG_ 407 RFC_Obj01_AxVnce "Variance of object relative acceleration in X direction. ISO 23150: Acceleration {x, y, z}  error (A.2.26)";
CM_ SG_ 407 RFC_Obj01_AyVnce "Variance of object relative acceleration in Y direction. ISO 23150: Acceleration {x, y, z}  error (A.2.26)";
CM_ SG_ 407 RFC_Obj01_OrientationYawVnce "Variance of object orientation yaw angle. ISO 23150: Orientation {yaw, pitch, roll}  error (A.2.16)";
CM_ SG_ 407 RFC_Obj01_MovingObserved "Object has been observed moving over the ground since it was first detected";
CM_ SG_ 407 RFC_Obj01_MovingProbability "Object has been observed moving over the ground";
CM_ SG_ 407 RFC_Obj01_Length "Object Length. ISO 23150: Bounding box extent {length, width, height} (A.2.19)";
CM_ SG_ 407 RFC_Obj01_Valid "Object is valid or not";
CM_ SG_ 407 RFC_Obj01_LengthVnce "Variance of object Length. ISO 23150: Bounding box extent {length, width, height}  error (A.2.20)";
CM_ SG_ 407 RFC_Obj01_WidthVnce "Variance of object Width. ISO 23150: Bounding box extent {length, width, height}  error (A.2.20)";
CM_ SG_ 407 RFC_Obj01_Width "Object Width. ISO 23150: Bounding box extent {length, width, height} (A.2.19)";
CM_ SG_ 407 RFC_Obj01_BehaviorType "Indicates that which behavior the object associated for";
CM_ SG_ 407 RFC_Obj01_ObstacleConf "Confidence of the object being an Obstacle. ISO 23150: Potentially moving object classification type  confidence (A.2.12)";
CM_ SG_ 407 RFC_Obj01_NonObstacleConf "Confidence of the object being a Non-Obstacle. ISO 23150: Potentially moving object classification type  confidence (A.2.12)";
CM_ SG_ 407 RFC_Obj01_PxPyCoVnce "Covariance of Px and Py";
CM_ SG_ 407 RFC_Obj01_PxVxCoVnce "Covariance of Px and Vx";
CM_ SG_ 407 RFC_Obj01_PxVyCoVnce "Covariance of Px and Vy";
CM_ SG_ 407 RFC_Obj01_PyVxCoVnce "Covariance of Py and Vx";
CM_ SG_ 407 RFC_Obj01_PyVyCoVnce "Covariance of Py and Vy";
CM_ SG_ 407 RFC_Obj01_VxVyCoVnce "Covariance of Vx and Vy";
CM_ SG_ 407 RFC_Obj01_PxAxCoVnce "Covariance of Px and Ax";
CM_ SG_ 407 RFC_Obj01_PxAyCoVnce "Covariance of Px and Ay";
CM_ SG_ 407 RFC_Obj01_PyAxCoVnce "Covariance of Py and Ax";
CM_ SG_ 407 RFC_Obj01_PyAyCoVnce "Covariance of Py and Ay";
CM_ SG_ 407 RFC_Obj01_VxAxCoVnce "Covariance of Vx and Ax";
CM_ SG_ 407 RFC_Obj01_VxAyCoVnce "Covariance of Vx and Ay";
CM_ SG_ 407 RFC_Obj01_VyAxCoVnce "Covariance of Vy and Ax";
CM_ SG_ 407 RFC_Obj01_VyAyCoVnce "Covariance of Vy and Ay";
CM_ SG_ 407 RFC_Obj01_AxAyCoVnce "Covariance of Ax and Ay";
CM_ SG_ 407 RFC_Obj01_MobileObstConf "Confidence of the object being a mobile obstacle. ISO 23150: Potentially moving object classification type  confidence (A.2.12)";
CM_ SG_ 407 RFC_Obj01_Mob4PlusWhlConf "Confidence of a mobile object which has 4 or more wheels. ISO 23150: Potentially moving object classification type  confidence (A.2.12)";
CM_ SG_ 407 RFC_Obj01_Mob2WhlConf "Confidence of a mobile object being 2-wheels vehicle. ISO 23150: Potentially moving object classification type  confidence (A.2.12)";
CM_ SG_ 407 RFC_Obj01_MobPedConf "Confidence of a mobile object being a pedestrian. ISO 23150: Potentially moving object classification type  confidence (A.2.12)";
CM_ SG_ 407 RFC_Obj01_FourPlusWhlCarConf "Confidence of a mobile object which has 4 or more wheels--passenger car. ISO 23150: Potentially moving object classification type  confidence (A.2.12)";
CM_ SG_ 407 RFC_Obj01_FourPlusWhlHGVConf "Confidence of a mobile object which has 4 or more wheels--commercial vehicle (Truck). ISO 23150: Potentially moving object classification type  confidence (A.2.12)";
CM_ SG_ 407 RFC_Obj01_GroundReflexConf "Confidence of the object being a ground reflex. ISO 23150: Potentially moving object classification type  confidence (A.2.12)";
CM_ SG_ 407 RFC_Obj01_StatObstConf "Confidence of the object being a stationary obstacle. ISO 23150: Potentially moving object classification type  confidence (A.2.12)";
CM_ SG_ 407 RFC_Obj01_StatBarrierConf "Confidence of the object being a stationary road barrier. ISO 23150: Potentially moving object classification type  confidence (A.2.12)";
CM_ SG_ 408 RFC_Obj02_CRC "CRC - Autosar E2E Profile 5";
CM_ SG_ 408 RFC_Obj02_AliveCtr "Alive counter - Autosar E2E Profile 5";
CM_ SG_ 408 RFC_Obj02_ProtBlockCtr "Protocol-Signal: Block-Counter";
CM_ SG_ 408 RFC_Obj02_ReferencePoint "Reference Point of the detected object. ISO 23150: Reference point (A.2.17)";
CM_ SG_ 408 RFC_Obj02_ObjId "Unique Object ID. ISO 23150: Object ID (A.2.2)";
CM_ SG_ 408 RFC_Obj02_MeasurementStatus "Object is measured or not. ISO 23150: Measurement status  object level (A.2.9)";
CM_ SG_ 408 RFC_Obj02_Px "Object position in X direction. ISO 23150: Position  object level {x, y, z} (A.2.13)";
CM_ SG_ 408 RFC_Obj02_Py "Object position in Y direction. ISO 23150: Position  object level {x, y, z} (A.2.13)";
CM_ SG_ 408 RFC_Obj02_PxVnce "Variance of object position in X direction. ISO 23150: Position  object level {x, y, z}  error (A.2.14)";
CM_ SG_ 408 RFC_Obj02_PyVnce "Variance of object position in Y direction. ISO 23150: Position  object level {x, y, z}  error (A.2.14)";
CM_ SG_ 408 RFC_Obj02_Vx "Object relative velocity in X direction. ISO 23150: Velocity {x, y, z}  object level (A.2.23)";
CM_ SG_ 408 RFC_Obj02_Vy "Object relative velocity in Y direction. ISO 23150: Velocity {x, y, z}  object level (A.2.23)";
CM_ SG_ 408 RFC_Obj02_Ax "Object relative acceleration in X direction. ISO 23150: Acceleration {x, y, z} (A.2.25)";
CM_ SG_ 408 RFC_Obj02_Ay "Object relative acceleration in Y direction. ISO 23150: Acceleration {x, y, z} (A.2.25)";
CM_ SG_ 408 RFC_Obj02_OrientationYaw "Object orientation yaw angle. ISO 23150: Orientation {yaw, pitch, roll} (A.2.15)";
CM_ SG_ 408 RFC_Obj02_ExistProb "Existence probability of object. ISO 23150: Existence probability  object level (A.2.1)";
CM_ SG_ 408 RFC_Obj02_VxVnce "Variance of object relative velocity in X direction. ISO 23150: Velocity {x, y, z}  object level  error (A.2.24)";
CM_ SG_ 408 RFC_Obj02_VyVnce "Variance of object relative velocity in Y direction. ISO 23150: Velocity {x, y, z}  object level  error (A.2.24)";
CM_ SG_ 408 RFC_Obj02_AxVnce "Variance of object relative acceleration in X direction. ISO 23150: Acceleration {x, y, z}  error (A.2.26)";
CM_ SG_ 408 RFC_Obj02_AyVnce "Variance of object relative acceleration in Y direction. ISO 23150: Acceleration {x, y, z}  error (A.2.26)";
CM_ SG_ 408 RFC_Obj02_OrientationYawVnce "Variance of object orientation yaw angle. ISO 23150: Orientation {yaw, pitch, roll}  error (A.2.16)";
CM_ SG_ 408 RFC_Obj02_MovingObserved "Object has been observed moving over the ground since it was first detected";
CM_ SG_ 408 RFC_Obj02_MovingProbability "Object has been observed moving over the ground";
CM_ SG_ 408 RFC_Obj02_Length "Object Length. ISO 23150: Bounding box extent {length, width, height} (A.2.19)";
CM_ SG_ 408 RFC_Obj02_Valid "Object is valid or not";
CM_ SG_ 408 RFC_Obj02_LengthVnce "Variance of object Length. ISO 23150: Bounding box extent {length, width, height}  error (A.2.20)";
CM_ SG_ 408 RFC_Obj02_WidthVnce "Variance of object Width. ISO 23150: Bounding box extent {length, width, height}  error (A.2.20)";
CM_ SG_ 408 RFC_Obj02_Width "Object Width. ISO 23150: Bounding box extent {length, width, height} (A.2.19)";
CM_ SG_ 408 RFC_Obj02_BehaviorType "Indicates that which behavior the object associated for";
CM_ SG_ 408 RFC_Obj02_ObstacleConf "Confidence of the object being an Obstacle. ISO 23150: Potentially moving object classification type  confidence (A.2.12)";
CM_ SG_ 408 RFC_Obj02_NonObstacleConf "Confidence of the object being a Non-Obstacle. ISO 23150: Potentially moving object classification type  confidence (A.2.12)";
CM_ SG_ 408 RFC_Obj02_PxPyCoVnce "Covariance of Px and Py";
CM_ SG_ 408 RFC_Obj02_PxVxCoVnce "Covariance of Px and Vx";
CM_ SG_ 408 RFC_Obj02_PxVyCoVnce "Covariance of Px and Vy";
CM_ SG_ 408 RFC_Obj02_PyVxCoVnce "Covariance of Py and Vx";
CM_ SG_ 408 RFC_Obj02_PyVyCoVnce "Covariance of Py and Vy";
CM_ SG_ 408 RFC_Obj02_VxVyCoVnce "Covariance of Vx and Vy";
CM_ SG_ 408 RFC_Obj02_PxAxCoVnce "Covariance of Px and Ax";
CM_ SG_ 408 RFC_Obj02_PxAyCoVnce "Covariance of Px and Ay";
CM_ SG_ 408 RFC_Obj02_PyAxCoVnce "Covariance of Py and Ax";
CM_ SG_ 408 RFC_Obj02_PyAyCoVnce "Covariance of Py and Ay";
CM_ SG_ 408 RFC_Obj02_VxAxCoVnce "Covariance of Vx and Ax";
CM_ SG_ 408 RFC_Obj02_VxAyCoVnce "Covariance of Vx and Ay";
CM_ SG_ 408 RFC_Obj02_VyAxCoVnce "Covariance of Vy and Ax";
CM_ SG_ 408 RFC_Obj02_VyAyCoVnce "Covariance of Vy and Ay";
CM_ SG_ 408 RFC_Obj02_AxAyCoVnce "Covariance of Ax and Ay";
CM_ SG_ 408 RFC_Obj02_MobileObstConf "Confidence of the object being a mobile obstacle. ISO 23150: Potentially moving object classification type  confidence (A.2.12)";
CM_ SG_ 408 RFC_Obj02_Mob4PlusWhlConf "Confidence of a mobile object which has 4 or more wheels. ISO 23150: Potentially moving object classification type  confidence (A.2.12)";
CM_ SG_ 408 RFC_Obj02_Mob2WhlConf "Confidence of a mobile object being 2-wheels vehicle. ISO 23150: Potentially moving object classification type  confidence (A.2.12)";
CM_ SG_ 408 RFC_Obj02_MobPedConf "Confidence of a mobile object being a pedestrian. ISO 23150: Potentially moving object classification type  confidence (A.2.12)";
CM_ SG_ 408 RFC_Obj02_FourPlusWhlCarConf "Confidence of a mobile object which has 4 or more wheels--passenger car. ISO 23150: Potentially moving object classification type  confidence (A.2.12)";
CM_ SG_ 408 RFC_Obj02_FourPlusWhlHGVConf "Confidence of a mobile object which has 4 or more wheels--commercial vehicle (Truck). ISO 23150: Potentially moving object classification type  confidence (A.2.12)";
CM_ SG_ 408 RFC_Obj02_GroundReflexConf "Confidence of the object being a ground reflex. ISO 23150: Potentially moving object classification type  confidence (A.2.12)";
CM_ SG_ 408 RFC_Obj02_StatObstConf "Confidence of the object being a stationary obstacle. ISO 23150: Potentially moving object classification type  confidence (A.2.12)";
CM_ SG_ 408 RFC_Obj02_StatBarrierConf "Confidence of the object being a stationary road barrier. ISO 23150: Potentially moving object classification type  confidence (A.2.12)";
CM_ SG_ 409 RFC_Obj03_CRC "CRC - Autosar E2E Profile 5";
CM_ SG_ 409 RFC_Obj03_AliveCtr "Alive counter - Autosar E2E Profile 5";
CM_ SG_ 409 RFC_Obj03_ProtBlockCtr "Protocol-Signal: Block-Counter";
CM_ SG_ 409 RFC_Obj03_ReferencePoint "Reference Point of the detected object. ISO 23150: Reference point (A.2.17)";
CM_ SG_ 409 RFC_Obj03_ObjId "Unique Object ID. ISO 23150: Object ID (A.2.2)";
CM_ SG_ 409 RFC_Obj03_MeasurementStatus "Object is measured or not. ISO 23150: Measurement status  object level (A.2.9)";
CM_ SG_ 409 RFC_Obj03_Px "Object position in X direction. ISO 23150: Position  object level {x, y, z} (A.2.13)";
CM_ SG_ 409 RFC_Obj03_Py "Object position in Y direction. ISO 23150: Position  object level {x, y, z} (A.2.13)";
CM_ SG_ 409 RFC_Obj03_PxVnce "Variance of object position in X direction. ISO 23150: Position  object level {x, y, z}  error (A.2.14)";
CM_ SG_ 409 RFC_Obj03_PyVnce "Variance of object position in Y direction. ISO 23150: Position  object level {x, y, z}  error (A.2.14)";
CM_ SG_ 409 RFC_Obj03_Vx "Object relative velocity in X direction. ISO 23150: Velocity {x, y, z}  object level (A.2.23)";
CM_ SG_ 409 RFC_Obj03_Vy "Object relative velocity in Y direction. ISO 23150: Velocity {x, y, z}  object level (A.2.23)";
CM_ SG_ 409 RFC_Obj03_Ax "Object relative acceleration in X direction. ISO 23150: Acceleration {x, y, z} (A.2.25)";
CM_ SG_ 409 RFC_Obj03_Ay "Object relative acceleration in Y direction. ISO 23150: Acceleration {x, y, z} (A.2.25)";
CM_ SG_ 409 RFC_Obj03_OrientationYaw "Object orientation yaw angle. ISO 23150: Orientation {yaw, pitch, roll} (A.2.15)";
CM_ SG_ 409 RFC_Obj03_ExistProb "Existence probability of object. ISO 23150: Existence probability  object level (A.2.1)";
CM_ SG_ 409 RFC_Obj03_VxVnce "Variance of object relative velocity in X direction. ISO 23150: Velocity {x, y, z}  object level  error (A.2.24)";
CM_ SG_ 409 RFC_Obj03_VyVnce "Variance of object relative velocity in Y direction. ISO 23150: Velocity {x, y, z}  object level  error (A.2.24)";
CM_ SG_ 409 RFC_Obj03_AxVnce "Variance of object relative acceleration in X direction. ISO 23150: Acceleration {x, y, z}  error (A.2.26)";
CM_ SG_ 409 RFC_Obj03_AyVnce "Variance of object relative acceleration in Y direction. ISO 23150: Acceleration {x, y, z}  error (A.2.26)";
CM_ SG_ 409 RFC_Obj03_OrientationYawVnce "Variance of object orientation yaw angle. ISO 23150: Orientation {yaw, pitch, roll}  error (A.2.16)";
CM_ SG_ 409 RFC_Obj03_MovingObserved "Object has been observed moving over the ground since it was first detected";
CM_ SG_ 409 RFC_Obj03_MovingProbability "Object has been observed moving over the ground";
CM_ SG_ 409 RFC_Obj03_Length "Object Length. ISO 23150: Bounding box extent {length, width, height} (A.2.19)";
CM_ SG_ 409 RFC_Obj03_Valid "Object is valid or not";
CM_ SG_ 409 RFC_Obj03_LengthVnce "Variance of object Length. ISO 23150: Bounding box extent {length, width, height}  error (A.2.20)";
CM_ SG_ 409 RFC_Obj03_WidthVnce "Variance of object Width. ISO 23150: Bounding box extent {length, width, height}  error (A.2.20)";
CM_ SG_ 409 RFC_Obj03_Width "Object Width. ISO 23150: Bounding box extent {length, width, height} (A.2.19)";
CM_ SG_ 409 RFC_Obj03_BehaviorType "Indicates that which behavior the object associated for";
CM_ SG_ 409 RFC_Obj03_ObstacleConf "Confidence of the object being an Obstacle. ISO 23150: Potentially moving object classification type  confidence (A.2.12)";
CM_ SG_ 409 RFC_Obj03_NonObstacleConf "Confidence of the object being a Non-Obstacle. ISO 23150: Potentially moving object classification type  confidence (A.2.12)";
CM_ SG_ 409 RFC_Obj03_PxPyCoVnce "Covariance of Px and Py";
CM_ SG_ 409 RFC_Obj03_PxVxCoVnce "Covariance of Px and Vx";
CM_ SG_ 409 RFC_Obj03_PxVyCoVnce "Covariance of Px and Vy";
CM_ SG_ 409 RFC_Obj03_PyVxCoVnce "Covariance of Py and Vx";
CM_ SG_ 409 RFC_Obj03_PyVyCoVnce "Covariance of Py and Vy";
CM_ SG_ 409 RFC_Obj03_VxVyCoVnce "Covariance of Vx and Vy";
CM_ SG_ 409 RFC_Obj03_PxAxCoVnce "Covariance of Px and Ax";
CM_ SG_ 409 RFC_Obj03_PxAyCoVnce "Covariance of Px and Ay";
CM_ SG_ 409 RFC_Obj03_PyAxCoVnce "Covariance of Py and Ax";
CM_ SG_ 409 RFC_Obj03_PyAyCoVnce "Covariance of Py and Ay";
CM_ SG_ 409 RFC_Obj03_VxAxCoVnce "Covariance of Vx and Ax";
CM_ SG_ 409 RFC_Obj03_VxAyCoVnce "Covariance of Vx and Ay";
CM_ SG_ 409 RFC_Obj03_VyAxCoVnce "Covariance of Vy and Ax";
CM_ SG_ 409 RFC_Obj03_VyAyCoVnce "Covariance of Vy and Ay";
CM_ SG_ 409 RFC_Obj03_AxAyCoVnce "Covariance of Ax and Ay";
CM_ SG_ 409 RFC_Obj03_MobileObstConf "Confidence of the object being a mobile obstacle. ISO 23150: Potentially moving object classification type  confidence (A.2.12)";
CM_ SG_ 409 RFC_Obj03_Mob4PlusWhlConf "Confidence of a mobile object which has 4 or more wheels. ISO 23150: Potentially moving object classification type  confidence (A.2.12)";
CM_ SG_ 409 RFC_Obj03_Mob2WhlConf "Confidence of a mobile object being 2-wheels vehicle. ISO 23150: Potentially moving object classification type  confidence (A.2.12)";
CM_ SG_ 409 RFC_Obj03_MobPedConf "Confidence of a mobile object being a pedestrian. ISO 23150: Potentially moving object classification type  confidence (A.2.12)";
CM_ SG_ 409 RFC_Obj03_FourPlusWhlCarConf "Confidence of a mobile object which has 4 or more wheels--passenger car. ISO 23150: Potentially moving object classification type  confidence (A.2.12)";
CM_ SG_ 409 RFC_Obj03_FourPlusWhlHGVConf "Confidence of a mobile object which has 4 or more wheels--commercial vehicle (Truck). ISO 23150: Potentially moving object classification type  confidence (A.2.12)";
CM_ SG_ 409 RFC_Obj03_GroundReflexConf "Confidence of the object being a ground reflex. ISO 23150: Potentially moving object classification type  confidence (A.2.12)";
CM_ SG_ 409 RFC_Obj03_StatObstConf "Confidence of the object being a stationary obstacle. ISO 23150: Potentially moving object classification type  confidence (A.2.12)";
CM_ SG_ 409 RFC_Obj03_StatBarrierConf "Confidence of the object being a stationary road barrier. ISO 23150: Potentially moving object classification type  confidence (A.2.12)";
CM_ SG_ 410 RFC_Obj04_CRC "CRC - Autosar E2E Profile 5";
CM_ SG_ 410 RFC_Obj04_AliveCtr "Alive counter - Autosar E2E Profile 5";
CM_ SG_ 410 RFC_Obj04_ProtBlockCtr "Protocol-Signal: Block-Counter";
CM_ SG_ 410 RFC_Obj04_ReferencePoint "Reference Point of the detected object. ISO 23150: Reference point (A.2.17)";
CM_ SG_ 410 RFC_Obj04_ObjId "Unique Object ID. ISO 23150: Object ID (A.2.2)";
CM_ SG_ 410 RFC_Obj04_MeasurementStatus "Object is measured or not. ISO 23150: Measurement status  object level (A.2.9)";
CM_ SG_ 410 RFC_Obj04_Px "Object position in X direction. ISO 23150: Position  object level {x, y, z} (A.2.13)";
CM_ SG_ 410 RFC_Obj04_Py "Object position in Y direction. ISO 23150: Position  object level {x, y, z} (A.2.13)";
CM_ SG_ 410 RFC_Obj04_PxVnce "Variance of object position in X direction. ISO 23150: Position  object level {x, y, z}  error (A.2.14)";
CM_ SG_ 410 RFC_Obj04_PyVnce "Variance of object position in Y direction. ISO 23150: Position  object level {x, y, z}  error (A.2.14)";
CM_ SG_ 410 RFC_Obj04_Vx "Object relative velocity in X direction. ISO 23150: Velocity {x, y, z}  object level (A.2.23)";
CM_ SG_ 410 RFC_Obj04_Vy "Object relative velocity in Y direction. ISO 23150: Velocity {x, y, z}  object level (A.2.23)";
CM_ SG_ 410 RFC_Obj04_Ax "Object relative acceleration in X direction. ISO 23150: Acceleration {x, y, z} (A.2.25)";
CM_ SG_ 410 RFC_Obj04_Ay "Object relative acceleration in Y direction. ISO 23150: Acceleration {x, y, z} (A.2.25)";
CM_ SG_ 410 RFC_Obj04_OrientationYaw "Object orientation yaw angle. ISO 23150: Orientation {yaw, pitch, roll} (A.2.15)";
CM_ SG_ 410 RFC_Obj04_ExistProb "Existence probability of object. ISO 23150: Existence probability  object level (A.2.1)";
CM_ SG_ 410 RFC_Obj04_VxVnce "Variance of object relative velocity in X direction. ISO 23150: Velocity {x, y, z}  object level  error (A.2.24)";
CM_ SG_ 410 RFC_Obj04_VyVnce "Variance of object relative velocity in Y direction. ISO 23150: Velocity {x, y, z}  object level  error (A.2.24)";
CM_ SG_ 410 RFC_Obj04_AxVnce "Variance of object relative acceleration in X direction. ISO 23150: Acceleration {x, y, z}  error (A.2.26)";
CM_ SG_ 410 RFC_Obj04_AyVnce "Variance of object relative acceleration in Y direction. ISO 23150: Acceleration {x, y, z}  error (A.2.26)";
CM_ SG_ 410 RFC_Obj04_OrientationYawVnce "Variance of object orientation yaw angle. ISO 23150: Orientation {yaw, pitch, roll}  error (A.2.16)";
CM_ SG_ 410 RFC_Obj04_MovingObserved "Object has been observed moving over the ground since it was first detected";
CM_ SG_ 410 RFC_Obj04_MovingProbability "Object has been observed moving over the ground";
CM_ SG_ 410 RFC_Obj04_Length "Object Length. ISO 23150: Bounding box extent {length, width, height} (A.2.19)";
CM_ SG_ 410 RFC_Obj04_Valid "Object is valid or not";
CM_ SG_ 410 RFC_Obj04_LengthVnce "Variance of object Length. ISO 23150: Bounding box extent {length, width, height}  error (A.2.20)";
CM_ SG_ 410 RFC_Obj04_WidthVnce "Variance of object Width. ISO 23150: Bounding box extent {length, width, height}  error (A.2.20)";
CM_ SG_ 410 RFC_Obj04_Width "Object Width. ISO 23150: Bounding box extent {length, width, height} (A.2.19)";
CM_ SG_ 410 RFC_Obj04_BehaviorType "Indicates that which behavior the object associated for";
CM_ SG_ 410 RFC_Obj04_ObstacleConf "Confidence of the object being an Obstacle. ISO 23150: Potentially moving object classification type  confidence (A.2.12)";
CM_ SG_ 410 RFC_Obj04_NonObstacleConf "Confidence of the object being a Non-Obstacle. ISO 23150: Potentially moving object classification type  confidence (A.2.12)";
CM_ SG_ 410 RFC_Obj04_PxPyCoVnce "Covariance of Px and Py";
CM_ SG_ 410 RFC_Obj04_PxVxCoVnce "Covariance of Px and Vx";
CM_ SG_ 410 RFC_Obj04_PxVyCoVnce "Covariance of Px and Vy";
CM_ SG_ 410 RFC_Obj04_PyVxCoVnce "Covariance of Py and Vx";
CM_ SG_ 410 RFC_Obj04_PyVyCoVnce "Covariance of Py and Vy";
CM_ SG_ 410 RFC_Obj04_VxVyCoVnce "Covariance of Vx and Vy";
CM_ SG_ 410 RFC_Obj04_PxAxCoVnce "Covariance of Px and Ax";
CM_ SG_ 410 RFC_Obj04_PxAyCoVnce "Covariance of Px and Ay";
CM_ SG_ 410 RFC_Obj04_PyAxCoVnce "Covariance of Py and Ax";
CM_ SG_ 410 RFC_Obj04_PyAyCoVnce "Covariance of Py and Ay";
CM_ SG_ 410 RFC_Obj04_VxAxCoVnce "Covariance of Vx and Ax";
CM_ SG_ 410 RFC_Obj04_VxAyCoVnce "Covariance of Vx and Ay";
CM_ SG_ 410 RFC_Obj04_VyAxCoVnce "Covariance of Vy and Ax";
CM_ SG_ 410 RFC_Obj04_VyAyCoVnce "Covariance of Vy and Ay";
CM_ SG_ 410 RFC_Obj04_AxAyCoVnce "Covariance of Ax and Ay";
CM_ SG_ 410 RFC_Obj04_MobileObstConf "Confidence of the object being a mobile obstacle. ISO 23150: Potentially moving object classification type  confidence (A.2.12)";
CM_ SG_ 410 RFC_Obj04_Mob4PlusWhlConf "Confidence of a mobile object which has 4 or more wheels. ISO 23150: Potentially moving object classification type  confidence (A.2.12)";
CM_ SG_ 410 RFC_Obj04_Mob2WhlConf "Confidence of a mobile object being 2-wheels vehicle. ISO 23150: Potentially moving object classification type  confidence (A.2.12)";
CM_ SG_ 410 RFC_Obj04_MobPedConf "Confidence of a mobile object being a pedestrian. ISO 23150: Potentially moving object classification type  confidence (A.2.12)";
CM_ SG_ 410 RFC_Obj04_FourPlusWhlCarConf "Confidence of a mobile object which has 4 or more wheels--passenger car. ISO 23150: Potentially moving object classification type  confidence (A.2.12)";
CM_ SG_ 410 RFC_Obj04_FourPlusWhlHGVConf "Confidence of a mobile object which has 4 or more wheels--commercial vehicle (Truck). ISO 23150: Potentially moving object classification type  confidence (A.2.12)";
CM_ SG_ 410 RFC_Obj04_GroundReflexConf "Confidence of the object being a ground reflex. ISO 23150: Potentially moving object classification type  confidence (A.2.12)";
CM_ SG_ 410 RFC_Obj04_StatObstConf "Confidence of the object being a stationary obstacle. ISO 23150: Potentially moving object classification type  confidence (A.2.12)";
CM_ SG_ 410 RFC_Obj04_StatBarrierConf "Confidence of the object being a stationary road barrier. ISO 23150: Potentially moving object classification type  confidence (A.2.12)";
CM_ SG_ 411 RFC_Obj05_CRC "CRC - Autosar E2E Profile 5";
CM_ SG_ 411 RFC_Obj05_AliveCtr "Alive counter - Autosar E2E Profile 5";
CM_ SG_ 411 RFC_Obj05_ProtBlockCtr "Protocol-Signal: Block-Counter";
CM_ SG_ 411 RFC_Obj05_ReferencePoint "Reference Point of the detected object. ISO 23150: Reference point (A.2.17)";
CM_ SG_ 411 RFC_Obj05_ObjId "Unique Object ID. ISO 23150: Object ID (A.2.2)";
CM_ SG_ 411 RFC_Obj05_MeasurementStatus "Object is measured or not. ISO 23150: Measurement status  object level (A.2.9)";
CM_ SG_ 411 RFC_Obj05_Px "Object position in X direction. ISO 23150: Position  object level {x, y, z} (A.2.13)";
CM_ SG_ 411 RFC_Obj05_Py "Object position in Y direction. ISO 23150: Position  object level {x, y, z} (A.2.13)";
CM_ SG_ 411 RFC_Obj05_PxVnce "Variance of object position in X direction. ISO 23150: Position  object level {x, y, z}  error (A.2.14)";
CM_ SG_ 411 RFC_Obj05_PyVnce "Variance of object position in Y direction. ISO 23150: Position  object level {x, y, z}  error (A.2.14)";
CM_ SG_ 411 RFC_Obj05_Vx "Object relative velocity in X direction. ISO 23150: Velocity {x, y, z}  object level (A.2.23)";
CM_ SG_ 411 RFC_Obj05_Vy "Object relative velocity in Y direction. ISO 23150: Velocity {x, y, z}  object level (A.2.23)";
CM_ SG_ 411 RFC_Obj05_Ax "Object relative acceleration in X direction. ISO 23150: Acceleration {x, y, z} (A.2.25)";
CM_ SG_ 411 RFC_Obj05_Ay "Object relative acceleration in Y direction. ISO 23150: Acceleration {x, y, z} (A.2.25)";
CM_ SG_ 411 RFC_Obj05_OrientationYaw "Object orientation yaw angle. ISO 23150: Orientation {yaw, pitch, roll} (A.2.15)";
CM_ SG_ 411 RFC_Obj05_ExistProb "Existence probability of object. ISO 23150: Existence probability  object level (A.2.1)";
CM_ SG_ 411 RFC_Obj05_VxVnce "Variance of object relative velocity in X direction. ISO 23150: Velocity {x, y, z}  object level  error (A.2.24)";
CM_ SG_ 411 RFC_Obj05_VyVnce "Variance of object relative velocity in Y direction. ISO 23150: Velocity {x, y, z}  object level  error (A.2.24)";
CM_ SG_ 411 RFC_Obj05_AxVnce "Variance of object relative acceleration in X direction. ISO 23150: Acceleration {x, y, z}  error (A.2.26)";
CM_ SG_ 411 RFC_Obj05_AyVnce "Variance of object relative acceleration in Y direction. ISO 23150: Acceleration {x, y, z}  error (A.2.26)";
CM_ SG_ 411 RFC_Obj05_OrientationYawVnce "Variance of object orientation yaw angle. ISO 23150: Orientation {yaw, pitch, roll}  error (A.2.16)";
CM_ SG_ 411 RFC_Obj05_MovingObserved "Object has been observed moving over the ground since it was first detected";
CM_ SG_ 411 RFC_Obj05_MovingProbability "Object has been observed moving over the ground";
CM_ SG_ 411 RFC_Obj05_Length "Object Length. ISO 23150: Bounding box extent {length, width, height} (A.2.19)";
CM_ SG_ 411 RFC_Obj05_Valid "Object is valid or not";
CM_ SG_ 411 RFC_Obj05_LengthVnce "Variance of object Length. ISO 23150: Bounding box extent {length, width, height}  error (A.2.20)";
CM_ SG_ 411 RFC_Obj05_WidthVnce "Variance of object Width. ISO 23150: Bounding box extent {length, width, height}  error (A.2.20)";
CM_ SG_ 411 RFC_Obj05_Width "Object Width. ISO 23150: Bounding box extent {length, width, height} (A.2.19)";
CM_ SG_ 411 RFC_Obj05_BehaviorType "Indicates that which behavior the object associated for";
CM_ SG_ 411 RFC_Obj05_ObstacleConf "Confidence of the object being an Obstacle. ISO 23150: Potentially moving object classification type  confidence (A.2.12)";
CM_ SG_ 411 RFC_Obj05_NonObstacleConf "Confidence of the object being a Non-Obstacle. ISO 23150: Potentially moving object classification type  confidence (A.2.12)";
CM_ SG_ 411 RFC_Obj05_PxPyCoVnce "Covariance of Px and Py";
CM_ SG_ 411 RFC_Obj05_PxVxCoVnce "Covariance of Px and Vx";
CM_ SG_ 411 RFC_Obj05_PxVyCoVnce "Covariance of Px and Vy";
CM_ SG_ 411 RFC_Obj05_PyVxCoVnce "Covariance of Py and Vx";
CM_ SG_ 411 RFC_Obj05_PyVyCoVnce "Covariance of Py and Vy";
CM_ SG_ 411 RFC_Obj05_VxVyCoVnce "Covariance of Vx and Vy";
CM_ SG_ 411 RFC_Obj05_PxAxCoVnce "Covariance of Px and Ax";
CM_ SG_ 411 RFC_Obj05_PxAyCoVnce "Covariance of Px and Ay";
CM_ SG_ 411 RFC_Obj05_PyAxCoVnce "Covariance of Py and Ax";
CM_ SG_ 411 RFC_Obj05_PyAyCoVnce "Covariance of Py and Ay";
CM_ SG_ 411 RFC_Obj05_VxAxCoVnce "Covariance of Vx and Ax";
CM_ SG_ 411 RFC_Obj05_VxAyCoVnce "Covariance of Vx and Ay";
CM_ SG_ 411 RFC_Obj05_VyAxCoVnce "Covariance of Vy and Ax";
CM_ SG_ 411 RFC_Obj05_VyAyCoVnce "Covariance of Vy and Ay";
CM_ SG_ 411 RFC_Obj05_AxAyCoVnce "Covariance of Ax and Ay";
CM_ SG_ 411 RFC_Obj05_MobileObstConf "Confidence of the object being a mobile obstacle. ISO 23150: Potentially moving object classification type  confidence (A.2.12)";
CM_ SG_ 411 RFC_Obj05_Mob4PlusWhlConf "Confidence of a mobile object which has 4 or more wheels. ISO 23150: Potentially moving object classification type  confidence (A.2.12)";
CM_ SG_ 411 RFC_Obj05_Mob2WhlConf "Confidence of a mobile object being 2-wheels vehicle. ISO 23150: Potentially moving object classification type  confidence (A.2.12)";
CM_ SG_ 411 RFC_Obj05_MobPedConf "Confidence of a mobile object being a pedestrian. ISO 23150: Potentially moving object classification type  confidence (A.2.12)";
CM_ SG_ 411 RFC_Obj05_FourPlusWhlCarConf "Confidence of a mobile object which has 4 or more wheels--passenger car. ISO 23150: Potentially moving object classification type  confidence (A.2.12)";
CM_ SG_ 411 RFC_Obj05_FourPlusWhlHGVConf "Confidence of a mobile object which has 4 or more wheels--commercial vehicle (Truck). ISO 23150: Potentially moving object classification type  confidence (A.2.12)";
CM_ SG_ 411 RFC_Obj05_GroundReflexConf "Confidence of the object being a ground reflex. ISO 23150: Potentially moving object classification type  confidence (A.2.12)";
CM_ SG_ 411 RFC_Obj05_StatObstConf "Confidence of the object being a stationary obstacle. ISO 23150: Potentially moving object classification type  confidence (A.2.12)";
CM_ SG_ 411 RFC_Obj05_StatBarrierConf "Confidence of the object being a stationary road barrier. ISO 23150: Potentially moving object classification type  confidence (A.2.12)";
CM_ SG_ 412 RFC_Obj06_CRC "CRC - Autosar E2E Profile 5";
CM_ SG_ 412 RFC_Obj06_AliveCtr "Alive counter - Autosar E2E Profile 5";
CM_ SG_ 412 RFC_Obj06_ProtBlockCtr "Protocol-Signal: Block-Counter";
CM_ SG_ 412 RFC_Obj06_ReferencePoint "Reference Point of the detected object. ISO 23150: Reference point (A.2.17)";
CM_ SG_ 412 RFC_Obj06_ObjId "Unique Object ID. ISO 23150: Object ID (A.2.2)";
CM_ SG_ 412 RFC_Obj06_MeasurementStatus "Object is measured or not. ISO 23150: Measurement status  object level (A.2.9)";
CM_ SG_ 412 RFC_Obj06_Px "Object position in X direction. ISO 23150: Position  object level {x, y, z} (A.2.13)";
CM_ SG_ 412 RFC_Obj06_Py "Object position in Y direction. ISO 23150: Position  object level {x, y, z} (A.2.13)";
CM_ SG_ 412 RFC_Obj06_PxVnce "Variance of object position in X direction. ISO 23150: Position  object level {x, y, z}  error (A.2.14)";
CM_ SG_ 412 RFC_Obj06_PyVnce "Variance of object position in Y direction. ISO 23150: Position  object level {x, y, z}  error (A.2.14)";
CM_ SG_ 412 RFC_Obj06_Vx "Object relative velocity in X direction. ISO 23150: Velocity {x, y, z}  object level (A.2.23)";
CM_ SG_ 412 RFC_Obj06_Vy "Object relative velocity in Y direction. ISO 23150: Velocity {x, y, z}  object level (A.2.23)";
CM_ SG_ 412 RFC_Obj06_Ax "Object relative acceleration in X direction. ISO 23150: Acceleration {x, y, z} (A.2.25)";
CM_ SG_ 412 RFC_Obj06_Ay "Object relative acceleration in Y direction. ISO 23150: Acceleration {x, y, z} (A.2.25)";
CM_ SG_ 412 RFC_Obj06_OrientationYaw "Object orientation yaw angle. ISO 23150: Orientation {yaw, pitch, roll} (A.2.15)";
CM_ SG_ 412 RFC_Obj06_ExistProb "Existence probability of object. ISO 23150: Existence probability  object level (A.2.1)";
CM_ SG_ 412 RFC_Obj06_VxVnce "Variance of object relative velocity in X direction. ISO 23150: Velocity {x, y, z}  object level  error (A.2.24)";
CM_ SG_ 412 RFC_Obj06_VyVnce "Variance of object relative velocity in Y direction. ISO 23150: Velocity {x, y, z}  object level  error (A.2.24)";
CM_ SG_ 412 RFC_Obj06_AxVnce "Variance of object relative acceleration in X direction. ISO 23150: Acceleration {x, y, z}  error (A.2.26)";
CM_ SG_ 412 RFC_Obj06_AyVnce "Variance of object relative acceleration in Y direction. ISO 23150: Acceleration {x, y, z}  error (A.2.26)";
CM_ SG_ 412 RFC_Obj06_OrientationYawVnce "Variance of object orientation yaw angle. ISO 23150: Orientation {yaw, pitch, roll}  error (A.2.16)";
CM_ SG_ 412 RFC_Obj06_MovingObserved "Object has been observed moving over the ground since it was first detected";
CM_ SG_ 412 RFC_Obj06_MovingProbability "Object has been observed moving over the ground";
CM_ SG_ 412 RFC_Obj06_Length "Object Length. ISO 23150: Bounding box extent {length, width, height} (A.2.19)";
CM_ SG_ 412 RFC_Obj06_Valid "Object is valid or not";
CM_ SG_ 412 RFC_Obj06_LengthVnce "Variance of object Length. ISO 23150: Bounding box extent {length, width, height}  error (A.2.20)";
CM_ SG_ 412 RFC_Obj06_WidthVnce "Variance of object Width. ISO 23150: Bounding box extent {length, width, height}  error (A.2.20)";
CM_ SG_ 412 RFC_Obj06_Width "Object Width. ISO 23150: Bounding box extent {length, width, height} (A.2.19)";
CM_ SG_ 412 RFC_Obj06_BehaviorType "Indicates that which behavior the object associated for";
CM_ SG_ 412 RFC_Obj06_ObstacleConf "Confidence of the object being an Obstacle. ISO 23150: Potentially moving object classification type  confidence (A.2.12)";
CM_ SG_ 412 RFC_Obj06_NonObstacleConf "Confidence of the object being a Non-Obstacle. ISO 23150: Potentially moving object classification type  confidence (A.2.12)";
CM_ SG_ 412 RFC_Obj06_PxPyCoVnce "Covariance of Px and Py";
CM_ SG_ 412 RFC_Obj06_PxVxCoVnce "Covariance of Px and Vx";
CM_ SG_ 412 RFC_Obj06_PxVyCoVnce "Covariance of Px and Vy";
CM_ SG_ 412 RFC_Obj06_PyVxCoVnce "Covariance of Py and Vx";
CM_ SG_ 412 RFC_Obj06_PyVyCoVnce "Covariance of Py and Vy";
CM_ SG_ 412 RFC_Obj06_VxVyCoVnce "Covariance of Vx and Vy";
CM_ SG_ 412 RFC_Obj06_PxAxCoVnce "Covariance of Px and Ax";
CM_ SG_ 412 RFC_Obj06_PxAyCoVnce "Covariance of Px and Ay";
CM_ SG_ 412 RFC_Obj06_PyAxCoVnce "Covariance of Py and Ax";
CM_ SG_ 412 RFC_Obj06_PyAyCoVnce "Covariance of Py and Ay";
CM_ SG_ 412 RFC_Obj06_VxAxCoVnce "Covariance of Vx and Ax";
CM_ SG_ 412 RFC_Obj06_VxAyCoVnce "Covariance of Vx and Ay";
CM_ SG_ 412 RFC_Obj06_VyAxCoVnce "Covariance of Vy and Ax";
CM_ SG_ 412 RFC_Obj06_VyAyCoVnce "Covariance of Vy and Ay";
CM_ SG_ 412 RFC_Obj06_AxAyCoVnce "Covariance of Ax and Ay";
CM_ SG_ 412 RFC_Obj06_MobileObstConf "Confidence of the object being a mobile obstacle. ISO 23150: Potentially moving object classification type  confidence (A.2.12)";
CM_ SG_ 412 RFC_Obj06_Mob4PlusWhlConf "Confidence of a mobile object which has 4 or more wheels. ISO 23150: Potentially moving object classification type  confidence (A.2.12)";
CM_ SG_ 412 RFC_Obj06_Mob2WhlConf "Confidence of a mobile object being 2-wheels vehicle. ISO 23150: Potentially moving object classification type  confidence (A.2.12)";
CM_ SG_ 412 RFC_Obj06_MobPedConf "Confidence of a mobile object being a pedestrian. ISO 23150: Potentially moving object classification type  confidence (A.2.12)";
CM_ SG_ 412 RFC_Obj06_FourPlusWhlCarConf "Confidence of a mobile object which has 4 or more wheels--passenger car. ISO 23150: Potentially moving object classification type  confidence (A.2.12)";
CM_ SG_ 412 RFC_Obj06_FourPlusWhlHGVConf "Confidence of a mobile object which has 4 or more wheels--commercial vehicle (Truck). ISO 23150: Potentially moving object classification type  confidence (A.2.12)";
CM_ SG_ 412 RFC_Obj06_GroundReflexConf "Confidence of the object being a ground reflex. ISO 23150: Potentially moving object classification type  confidence (A.2.12)";
CM_ SG_ 412 RFC_Obj06_StatObstConf "Confidence of the object being a stationary obstacle. ISO 23150: Potentially moving object classification type  confidence (A.2.12)";
CM_ SG_ 412 RFC_Obj06_StatBarrierConf "Confidence of the object being a stationary road barrier. ISO 23150: Potentially moving object classification type  confidence (A.2.12)";
CM_ SG_ 413 RFC_Obj07_CRC "CRC - Autosar E2E Profile 5";
CM_ SG_ 413 RFC_Obj07_AliveCtr "Alive counter - Autosar E2E Profile 5";
CM_ SG_ 413 RFC_Obj07_ProtBlockCtr "Protocol-Signal: Block-Counter";
CM_ SG_ 413 RFC_Obj07_ReferencePoint "Reference Point of the detected object. ISO 23150: Reference point (A.2.17)";
CM_ SG_ 413 RFC_Obj07_ObjId "Unique Object ID. ISO 23150: Object ID (A.2.2)";
CM_ SG_ 413 RFC_Obj07_MeasurementStatus "Object is measured or not. ISO 23150: Measurement status  object level (A.2.9)";
CM_ SG_ 413 RFC_Obj07_Px "Object position in X direction. ISO 23150: Position  object level {x, y, z} (A.2.13)";
CM_ SG_ 413 RFC_Obj07_Py "Object position in Y direction. ISO 23150: Position  object level {x, y, z} (A.2.13)";
CM_ SG_ 413 RFC_Obj07_PxVnce "Variance of object position in X direction. ISO 23150: Position  object level {x, y, z}  error (A.2.14)";
CM_ SG_ 413 RFC_Obj07_PyVnce "Variance of object position in Y direction. ISO 23150: Position  object level {x, y, z}  error (A.2.14)";
CM_ SG_ 413 RFC_Obj07_Vx "Object relative velocity in X direction. ISO 23150: Velocity {x, y, z}  object level (A.2.23)";
CM_ SG_ 413 RFC_Obj07_Vy "Object relative velocity in Y direction. ISO 23150: Velocity {x, y, z}  object level (A.2.23)";
CM_ SG_ 413 RFC_Obj07_Ax "Object relative acceleration in X direction. ISO 23150: Acceleration {x, y, z} (A.2.25)";
CM_ SG_ 413 RFC_Obj07_Ay "Object relative acceleration in Y direction. ISO 23150: Acceleration {x, y, z} (A.2.25)";
CM_ SG_ 413 RFC_Obj07_OrientationYaw "Object orientation yaw angle. ISO 23150: Orientation {yaw, pitch, roll} (A.2.15)";
CM_ SG_ 413 RFC_Obj07_ExistProb "Existence probability of object. ISO 23150: Existence probability  object level (A.2.1)";
CM_ SG_ 413 RFC_Obj07_VxVnce "Variance of object relative velocity in X direction. ISO 23150: Velocity {x, y, z}  object level  error (A.2.24)";
CM_ SG_ 413 RFC_Obj07_VyVnce "Variance of object relative velocity in Y direction. ISO 23150: Velocity {x, y, z}  object level  error (A.2.24)";
CM_ SG_ 413 RFC_Obj07_AxVnce "Variance of object relative acceleration in X direction. ISO 23150: Acceleration {x, y, z}  error (A.2.26)";
CM_ SG_ 413 RFC_Obj07_AyVnce "Variance of object relative acceleration in Y direction. ISO 23150: Acceleration {x, y, z}  error (A.2.26)";
CM_ SG_ 413 RFC_Obj07_OrientationYawVnce "Variance of object orientation yaw angle. ISO 23150: Orientation {yaw, pitch, roll}  error (A.2.16)";
CM_ SG_ 413 RFC_Obj07_MovingObserved "Object has been observed moving over the ground since it was first detected";
CM_ SG_ 413 RFC_Obj07_MovingProbability "Object has been observed moving over the ground";
CM_ SG_ 413 RFC_Obj07_Length "Object Length. ISO 23150: Bounding box extent {length, width, height} (A.2.19)";
CM_ SG_ 413 RFC_Obj07_Valid "Object is valid or not";
CM_ SG_ 413 RFC_Obj07_LengthVnce "Variance of object Length. ISO 23150: Bounding box extent {length, width, height}  error (A.2.20)";
CM_ SG_ 413 RFC_Obj07_WidthVnce "Variance of object Width. ISO 23150: Bounding box extent {length, width, height}  error (A.2.20)";
CM_ SG_ 413 RFC_Obj07_Width "Object Width. ISO 23150: Bounding box extent {length, width, height} (A.2.19)";
CM_ SG_ 413 RFC_Obj07_BehaviorType "Indicates that which behavior the object associated for";
CM_ SG_ 413 RFC_Obj07_ObstacleConf "Confidence of the object being an Obstacle. ISO 23150: Potentially moving object classification type  confidence (A.2.12)";
CM_ SG_ 413 RFC_Obj07_NonObstacleConf "Confidence of the object being a Non-Obstacle. ISO 23150: Potentially moving object classification type  confidence (A.2.12)";
CM_ SG_ 413 RFC_Obj07_PxPyCoVnce "Covariance of Px and Py";
CM_ SG_ 413 RFC_Obj07_PxVxCoVnce "Covariance of Px and Vx";
CM_ SG_ 413 RFC_Obj07_PxVyCoVnce "Covariance of Px and Vy";
CM_ SG_ 413 RFC_Obj07_PyVxCoVnce "Covariance of Py and Vx";
CM_ SG_ 413 RFC_Obj07_PyVyCoVnce "Covariance of Py and Vy";
CM_ SG_ 413 RFC_Obj07_VxVyCoVnce "Covariance of Vx and Vy";
CM_ SG_ 413 RFC_Obj07_PxAxCoVnce "Covariance of Px and Ax";
CM_ SG_ 413 RFC_Obj07_PxAyCoVnce "Covariance of Px and Ay";
CM_ SG_ 413 RFC_Obj07_PyAxCoVnce "Covariance of Py and Ax";
CM_ SG_ 413 RFC_Obj07_PyAyCoVnce "Covariance of Py and Ay";
CM_ SG_ 413 RFC_Obj07_VxAxCoVnce "Covariance of Vx and Ax";
CM_ SG_ 413 RFC_Obj07_VxAyCoVnce "Covariance of Vx and Ay";
CM_ SG_ 413 RFC_Obj07_VyAxCoVnce "Covariance of Vy and Ax";
CM_ SG_ 413 RFC_Obj07_VyAyCoVnce "Covariance of Vy and Ay";
CM_ SG_ 413 RFC_Obj07_AxAyCoVnce "Covariance of Ax and Ay";
CM_ SG_ 413 RFC_Obj07_MobileObstConf "Confidence of the object being a mobile obstacle. ISO 23150: Potentially moving object classification type  confidence (A.2.12)";
CM_ SG_ 413 RFC_Obj07_Mob4PlusWhlConf "Confidence of a mobile object which has 4 or more wheels. ISO 23150: Potentially moving object classification type  confidence (A.2.12)";
CM_ SG_ 413 RFC_Obj07_Mob2WhlConf "Confidence of a mobile object being 2-wheels vehicle. ISO 23150: Potentially moving object classification type  confidence (A.2.12)";
CM_ SG_ 413 RFC_Obj07_MobPedConf "Confidence of a mobile object being a pedestrian. ISO 23150: Potentially moving object classification type  confidence (A.2.12)";
CM_ SG_ 413 RFC_Obj07_FourPlusWhlCarConf "Confidence of a mobile object which has 4 or more wheels--passenger car. ISO 23150: Potentially moving object classification type  confidence (A.2.12)";
CM_ SG_ 413 RFC_Obj07_FourPlusWhlHGVConf "Confidence of a mobile object which has 4 or more wheels--commercial vehicle (Truck). ISO 23150: Potentially moving object classification type  confidence (A.2.12)";
CM_ SG_ 413 RFC_Obj07_GroundReflexConf "Confidence of the object being a ground reflex. ISO 23150: Potentially moving object classification type  confidence (A.2.12)";
CM_ SG_ 413 RFC_Obj07_StatObstConf "Confidence of the object being a stationary obstacle. ISO 23150: Potentially moving object classification type  confidence (A.2.12)";
CM_ SG_ 413 RFC_Obj07_StatBarrierConf "Confidence of the object being a stationary road barrier. ISO 23150: Potentially moving object classification type  confidence (A.2.12)";
CM_ SG_ 414 RFC_Obj08_CRC "CRC - Autosar E2E Profile 5";
CM_ SG_ 414 RFC_Obj08_AliveCtr "Alive counter - Autosar E2E Profile 5";
CM_ SG_ 414 RFC_Obj08_ProtBlockCtr "Protocol-Signal: Block-Counter";
CM_ SG_ 414 RFC_Obj08_ReferencePoint "Reference Point of the detected object. ISO 23150: Reference point (A.2.17)";
CM_ SG_ 414 RFC_Obj08_ObjId "Unique Object ID. ISO 23150: Object ID (A.2.2)";
CM_ SG_ 414 RFC_Obj08_MeasurementStatus "Object is measured or not. ISO 23150: Measurement status  object level (A.2.9)";
CM_ SG_ 414 RFC_Obj08_Px "Object position in X direction. ISO 23150: Position  object level {x, y, z} (A.2.13)";
CM_ SG_ 414 RFC_Obj08_Py "Object position in Y direction. ISO 23150: Position  object level {x, y, z} (A.2.13)";
CM_ SG_ 414 RFC_Obj08_PxVnce "Variance of object position in X direction. ISO 23150: Position  object level {x, y, z}  error (A.2.14)";
CM_ SG_ 414 RFC_Obj08_PyVnce "Variance of object position in Y direction. ISO 23150: Position  object level {x, y, z}  error (A.2.14)";
CM_ SG_ 414 RFC_Obj08_Vx "Object relative velocity in X direction. ISO 23150: Velocity {x, y, z}  object level (A.2.23)";
CM_ SG_ 414 RFC_Obj08_Vy "Object relative velocity in Y direction. ISO 23150: Velocity {x, y, z}  object level (A.2.23)";
CM_ SG_ 414 RFC_Obj08_Ax "Object relative acceleration in X direction. ISO 23150: Acceleration {x, y, z} (A.2.25)";
CM_ SG_ 414 RFC_Obj08_Ay "Object relative acceleration in Y direction. ISO 23150: Acceleration {x, y, z} (A.2.25)";
CM_ SG_ 414 RFC_Obj08_OrientationYaw "Object orientation yaw angle. ISO 23150: Orientation {yaw, pitch, roll} (A.2.15)";
CM_ SG_ 414 RFC_Obj08_ExistProb "Existence probability of object. ISO 23150: Existence probability  object level (A.2.1)";
CM_ SG_ 414 RFC_Obj08_VxVnce "Variance of object relative velocity in X direction. ISO 23150: Velocity {x, y, z}  object level  error (A.2.24)";
CM_ SG_ 414 RFC_Obj08_VyVnce "Variance of object relative velocity in Y direction. ISO 23150: Velocity {x, y, z}  object level  error (A.2.24)";
CM_ SG_ 414 RFC_Obj08_AxVnce "Variance of object relative acceleration in X direction. ISO 23150: Acceleration {x, y, z}  error (A.2.26)";
CM_ SG_ 414 RFC_Obj08_AyVnce "Variance of object relative acceleration in Y direction. ISO 23150: Acceleration {x, y, z}  error (A.2.26)";
CM_ SG_ 414 RFC_Obj08_OrientationYawVnce "Variance of object orientation yaw angle. ISO 23150: Orientation {yaw, pitch, roll}  error (A.2.16)";
CM_ SG_ 414 RFC_Obj08_MovingObserved "Object has been observed moving over the ground since it was first detected";
CM_ SG_ 414 RFC_Obj08_MovingProbability "Object has been observed moving over the ground";
CM_ SG_ 414 RFC_Obj08_Length "Object Length. ISO 23150: Bounding box extent {length, width, height} (A.2.19)";
CM_ SG_ 414 RFC_Obj08_Valid "Object is valid or not";
CM_ SG_ 414 RFC_Obj08_LengthVnce "Variance of object Length. ISO 23150: Bounding box extent {length, width, height}  error (A.2.20)";
CM_ SG_ 414 RFC_Obj08_WidthVnce "Variance of object Width. ISO 23150: Bounding box extent {length, width, height}  error (A.2.20)";
CM_ SG_ 414 RFC_Obj08_Width "Object Width. ISO 23150: Bounding box extent {length, width, height} (A.2.19)";
CM_ SG_ 414 RFC_Obj08_BehaviorType "Indicates that which behavior the object associated for";
CM_ SG_ 414 RFC_Obj08_ObstacleConf "Confidence of the object being an Obstacle. ISO 23150: Potentially moving object classification type  confidence (A.2.12)";
CM_ SG_ 414 RFC_Obj08_NonObstacleConf "Confidence of the object being a Non-Obstacle. ISO 23150: Potentially moving object classification type  confidence (A.2.12)";
CM_ SG_ 414 RFC_Obj08_PxPyCoVnce "Covariance of Px and Py";
CM_ SG_ 414 RFC_Obj08_PxVxCoVnce "Covariance of Px and Vx";
CM_ SG_ 414 RFC_Obj08_PxVyCoVnce "Covariance of Px and Vy";
CM_ SG_ 414 RFC_Obj08_PyVxCoVnce "Covariance of Py and Vx";
CM_ SG_ 414 RFC_Obj08_PyVyCoVnce "Covariance of Py and Vy";
CM_ SG_ 414 RFC_Obj08_VxVyCoVnce "Covariance of Vx and Vy";
CM_ SG_ 414 RFC_Obj08_PxAxCoVnce "Covariance of Px and Ax";
CM_ SG_ 414 RFC_Obj08_PxAyCoVnce "Covariance of Px and Ay";
CM_ SG_ 414 RFC_Obj08_PyAxCoVnce "Covariance of Py and Ax";
CM_ SG_ 414 RFC_Obj08_PyAyCoVnce "Covariance of Py and Ay";
CM_ SG_ 414 RFC_Obj08_VxAxCoVnce "Covariance of Vx and Ax";
CM_ SG_ 414 RFC_Obj08_VxAyCoVnce "Covariance of Vx and Ay";
CM_ SG_ 414 RFC_Obj08_VyAxCoVnce "Covariance of Vy and Ax";
CM_ SG_ 414 RFC_Obj08_VyAyCoVnce "Covariance of Vy and Ay";
CM_ SG_ 414 RFC_Obj08_AxAyCoVnce "Covariance of Ax and Ay";
CM_ SG_ 414 RFC_Obj08_MobileObstConf "Confidence of the object being a mobile obstacle. ISO 23150: Potentially moving object classification type  confidence (A.2.12)";
CM_ SG_ 414 RFC_Obj08_Mob4PlusWhlConf "Confidence of a mobile object which has 4 or more wheels. ISO 23150: Potentially moving object classification type  confidence (A.2.12)";
CM_ SG_ 414 RFC_Obj08_Mob2WhlConf "Confidence of a mobile object being 2-wheels vehicle. ISO 23150: Potentially moving object classification type  confidence (A.2.12)";
CM_ SG_ 414 RFC_Obj08_MobPedConf "Confidence of a mobile object being a pedestrian. ISO 23150: Potentially moving object classification type  confidence (A.2.12)";
CM_ SG_ 414 RFC_Obj08_FourPlusWhlCarConf "Confidence of a mobile object which has 4 or more wheels--passenger car. ISO 23150: Potentially moving object classification type  confidence (A.2.12)";
CM_ SG_ 414 RFC_Obj08_FourPlusWhlHGVConf "Confidence of a mobile object which has 4 or more wheels--commercial vehicle (Truck). ISO 23150: Potentially moving object classification type  confidence (A.2.12)";
CM_ SG_ 414 RFC_Obj08_GroundReflexConf "Confidence of the object being a ground reflex. ISO 23150: Potentially moving object classification type  confidence (A.2.12)";
CM_ SG_ 414 RFC_Obj08_StatObstConf "Confidence of the object being a stationary obstacle. ISO 23150: Potentially moving object classification type  confidence (A.2.12)";
CM_ SG_ 414 RFC_Obj08_StatBarrierConf "Confidence of the object being a stationary road barrier. ISO 23150: Potentially moving object classification type  confidence (A.2.12)";
CM_ SG_ 415 RFC_Obj09_CRC "CRC - Autosar E2E Profile 5";
CM_ SG_ 415 RFC_Obj09_AliveCtr "Alive counter - Autosar E2E Profile 5";
CM_ SG_ 415 RFC_Obj09_ProtBlockCtr "Protocol-Signal: Block-Counter";
CM_ SG_ 415 RFC_Obj09_ReferencePoint "Reference Point of the detected object. ISO 23150: Reference point (A.2.17)";
CM_ SG_ 415 RFC_Obj09_ObjId "Unique Object ID. ISO 23150: Object ID (A.2.2)";
CM_ SG_ 415 RFC_Obj09_MeasurementStatus "Object is measured or not. ISO 23150: Measurement status  object level (A.2.9)";
CM_ SG_ 415 RFC_Obj09_Px "Object position in X direction. ISO 23150: Position  object level {x, y, z} (A.2.13)";
CM_ SG_ 415 RFC_Obj09_Py "Object position in Y direction. ISO 23150: Position  object level {x, y, z} (A.2.13)";
CM_ SG_ 415 RFC_Obj09_PxVnce "Variance of object position in X direction. ISO 23150: Position  object level {x, y, z}  error (A.2.14)";
CM_ SG_ 415 RFC_Obj09_PyVnce "Variance of object position in Y direction. ISO 23150: Position  object level {x, y, z}  error (A.2.14)";
CM_ SG_ 415 RFC_Obj09_Vx "Object relative velocity in X direction. ISO 23150: Velocity {x, y, z}  object level (A.2.23)";
CM_ SG_ 415 RFC_Obj09_Vy "Object relative velocity in Y direction. ISO 23150: Velocity {x, y, z}  object level (A.2.23)";
CM_ SG_ 415 RFC_Obj09_Ax "Object relative acceleration in X direction. ISO 23150: Acceleration {x, y, z} (A.2.25)";
CM_ SG_ 415 RFC_Obj09_Ay "Object relative acceleration in Y direction. ISO 23150: Acceleration {x, y, z} (A.2.25)";
CM_ SG_ 415 RFC_Obj09_OrientationYaw "Object orientation yaw angle. ISO 23150: Orientation {yaw, pitch, roll} (A.2.15)";
CM_ SG_ 415 RFC_Obj09_ExistProb "Existence probability of object. ISO 23150: Existence probability  object level (A.2.1)";
CM_ SG_ 415 RFC_Obj09_VxVnce "Variance of object relative velocity in X direction. ISO 23150: Velocity {x, y, z}  object level  error (A.2.24)";
CM_ SG_ 415 RFC_Obj09_VyVnce "Variance of object relative velocity in Y direction. ISO 23150: Velocity {x, y, z}  object level  error (A.2.24)";
CM_ SG_ 415 RFC_Obj09_AxVnce "Variance of object relative acceleration in X direction. ISO 23150: Acceleration {x, y, z}  error (A.2.26)";
CM_ SG_ 415 RFC_Obj09_AyVnce "Variance of object relative acceleration in Y direction. ISO 23150: Acceleration {x, y, z}  error (A.2.26)";
CM_ SG_ 415 RFC_Obj09_OrientationYawVnce "Variance of object orientation yaw angle. ISO 23150: Orientation {yaw, pitch, roll}  error (A.2.16)";
CM_ SG_ 415 RFC_Obj09_MovingObserved "Object has been observed moving over the ground since it was first detected";
CM_ SG_ 415 RFC_Obj09_MovingProbability "Object has been observed moving over the ground";
CM_ SG_ 415 RFC_Obj09_Length "Object Length. ISO 23150: Bounding box extent {length, width, height} (A.2.19)";
CM_ SG_ 415 RFC_Obj09_Valid "Object is valid or not";
CM_ SG_ 415 RFC_Obj09_LengthVnce "Variance of object Length. ISO 23150: Bounding box extent {length, width, height}  error (A.2.20)";
CM_ SG_ 415 RFC_Obj09_WidthVnce "Variance of object Width. ISO 23150: Bounding box extent {length, width, height}  error (A.2.20)";
CM_ SG_ 415 RFC_Obj09_Width "Object Width. ISO 23150: Bounding box extent {length, width, height} (A.2.19)";
CM_ SG_ 415 RFC_Obj09_BehaviorType "Indicates that which behavior the object associated for";
CM_ SG_ 415 RFC_Obj09_ObstacleConf "Confidence of the object being an Obstacle. ISO 23150: Potentially moving object classification type  confidence (A.2.12)";
CM_ SG_ 415 RFC_Obj09_NonObstacleConf "Confidence of the object being a Non-Obstacle. ISO 23150: Potentially moving object classification type  confidence (A.2.12)";
CM_ SG_ 415 RFC_Obj09_PxPyCoVnce "Covariance of Px and Py";
CM_ SG_ 415 RFC_Obj09_PxVxCoVnce "Covariance of Px and Vx";
CM_ SG_ 415 RFC_Obj09_PxVyCoVnce "Covariance of Px and Vy";
CM_ SG_ 415 RFC_Obj09_PyVxCoVnce "Covariance of Py and Vx";
CM_ SG_ 415 RFC_Obj09_PyVyCoVnce "Covariance of Py and Vy";
CM_ SG_ 415 RFC_Obj09_VxVyCoVnce "Covariance of Vx and Vy";
CM_ SG_ 415 RFC_Obj09_PxAxCoVnce "Covariance of Px and Ax";
CM_ SG_ 415 RFC_Obj09_PxAyCoVnce "Covariance of Px and Ay";
CM_ SG_ 415 RFC_Obj09_PyAxCoVnce "Covariance of Py and Ax";
CM_ SG_ 415 RFC_Obj09_PyAyCoVnce "Covariance of Py and Ay";
CM_ SG_ 415 RFC_Obj09_VxAxCoVnce "Covariance of Vx and Ax";
CM_ SG_ 415 RFC_Obj09_VxAyCoVnce "Covariance of Vx and Ay";
CM_ SG_ 415 RFC_Obj09_VyAxCoVnce "Covariance of Vy and Ax";
CM_ SG_ 415 RFC_Obj09_VyAyCoVnce "Covariance of Vy and Ay";
CM_ SG_ 415 RFC_Obj09_AxAyCoVnce "Covariance of Ax and Ay";
CM_ SG_ 415 RFC_Obj09_MobileObstConf "Confidence of the object being a mobile obstacle. ISO 23150: Potentially moving object classification type  confidence (A.2.12)";
CM_ SG_ 415 RFC_Obj09_Mob4PlusWhlConf "Confidence of a mobile object which has 4 or more wheels. ISO 23150: Potentially moving object classification type  confidence (A.2.12)";
CM_ SG_ 415 RFC_Obj09_Mob2WhlConf "Confidence of a mobile object being 2-wheels vehicle. ISO 23150: Potentially moving object classification type  confidence (A.2.12)";
CM_ SG_ 415 RFC_Obj09_MobPedConf "Confidence of a mobile object being a pedestrian. ISO 23150: Potentially moving object classification type  confidence (A.2.12)";
CM_ SG_ 415 RFC_Obj09_FourPlusWhlCarConf "Confidence of a mobile object which has 4 or more wheels--passenger car. ISO 23150: Potentially moving object classification type  confidence (A.2.12)";
CM_ SG_ 415 RFC_Obj09_FourPlusWhlHGVConf "Confidence of a mobile object which has 4 or more wheels--commercial vehicle (Truck). ISO 23150: Potentially moving object classification type  confidence (A.2.12)";
CM_ SG_ 415 RFC_Obj09_GroundReflexConf "Confidence of the object being a ground reflex. ISO 23150: Potentially moving object classification type  confidence (A.2.12)";
CM_ SG_ 415 RFC_Obj09_StatObstConf "Confidence of the object being a stationary obstacle. ISO 23150: Potentially moving object classification type  confidence (A.2.12)";
CM_ SG_ 415 RFC_Obj09_StatBarrierConf "Confidence of the object being a stationary road barrier. ISO 23150: Potentially moving object classification type  confidence (A.2.12)";
CM_ SG_ 416 RFC_Obj10_CRC "CRC - Autosar E2E Profile 5";
CM_ SG_ 416 RFC_Obj10_AliveCtr "Alive counter - Autosar E2E Profile 5";
CM_ SG_ 416 RFC_Obj10_ProtBlockCtr "Protocol-Signal: Block-Counter";
CM_ SG_ 416 RFC_Obj10_ReferencePoint "Reference Point of the detected object. ISO 23150: Reference point (A.2.17)";
CM_ SG_ 416 RFC_Obj10_ObjId "Unique Object ID. ISO 23150: Object ID (A.2.2)";
CM_ SG_ 416 RFC_Obj10_MeasurementStatus "Object is measured or not. ISO 23150: Measurement status  object level (A.2.9)";
CM_ SG_ 416 RFC_Obj10_Px "Object position in X direction. ISO 23150: Position  object level {x, y, z} (A.2.13)";
CM_ SG_ 416 RFC_Obj10_Py "Object position in Y direction. ISO 23150: Position  object level {x, y, z} (A.2.13)";
CM_ SG_ 416 RFC_Obj10_PxVnce "Variance of object position in X direction. ISO 23150: Position  object level {x, y, z}  error (A.2.14)";
CM_ SG_ 416 RFC_Obj10_PyVnce "Variance of object position in Y direction. ISO 23150: Position  object level {x, y, z}  error (A.2.14)";
CM_ SG_ 416 RFC_Obj10_Vx "Object relative velocity in X direction. ISO 23150: Velocity {x, y, z}  object level (A.2.23)";
CM_ SG_ 416 RFC_Obj10_Vy "Object relative velocity in Y direction. ISO 23150: Velocity {x, y, z}  object level (A.2.23)";
CM_ SG_ 416 RFC_Obj10_Ax "Object relative acceleration in X direction. ISO 23150: Acceleration {x, y, z} (A.2.25)";
CM_ SG_ 416 RFC_Obj10_Ay "Object relative acceleration in Y direction. ISO 23150: Acceleration {x, y, z} (A.2.25)";
CM_ SG_ 416 RFC_Obj10_OrientationYaw "Object orientation yaw angle. ISO 23150: Orientation {yaw, pitch, roll} (A.2.15)";
CM_ SG_ 416 RFC_Obj10_ExistProb "Existence probability of object. ISO 23150: Existence probability  object level (A.2.1)";
CM_ SG_ 416 RFC_Obj10_VxVnce "Variance of object relative velocity in X direction. ISO 23150: Velocity {x, y, z}  object level  error (A.2.24)";
CM_ SG_ 416 RFC_Obj10_VyVnce "Variance of object relative velocity in Y direction. ISO 23150: Velocity {x, y, z}  object level  error (A.2.24)";
CM_ SG_ 416 RFC_Obj10_AxVnce "Variance of object relative acceleration in X direction. ISO 23150: Acceleration {x, y, z}  error (A.2.26)";
CM_ SG_ 416 RFC_Obj10_AyVnce "Variance of object relative acceleration in Y direction. ISO 23150: Acceleration {x, y, z}  error (A.2.26)";
CM_ SG_ 416 RFC_Obj10_OrientationYawVnce "Variance of object orientation yaw angle. ISO 23150: Orientation {yaw, pitch, roll}  error (A.2.16)";
CM_ SG_ 416 RFC_Obj10_MovingObserved "Object has been observed moving over the ground since it was first detected";
CM_ SG_ 416 RFC_Obj10_MovingProbability "Object has been observed moving over the ground";
CM_ SG_ 416 RFC_Obj10_Length "Object Length. ISO 23150: Bounding box extent {length, width, height} (A.2.19)";
CM_ SG_ 416 RFC_Obj10_Valid "Object is valid or not";
CM_ SG_ 416 RFC_Obj10_LengthVnce "Variance of object Length. ISO 23150: Bounding box extent {length, width, height}  error (A.2.20)";
CM_ SG_ 416 RFC_Obj10_WidthVnce "Variance of object Width. ISO 23150: Bounding box extent {length, width, height}  error (A.2.20)";
CM_ SG_ 416 RFC_Obj10_Width "Object Width. ISO 23150: Bounding box extent {length, width, height} (A.2.19)";
CM_ SG_ 416 RFC_Obj10_BehaviorType "Indicates that which behavior the object associated for";
CM_ SG_ 416 RFC_Obj10_ObstacleConf "Confidence of the object being an Obstacle. ISO 23150: Potentially moving object classification type  confidence (A.2.12)";
CM_ SG_ 416 RFC_Obj10_NonObstacleConf "Confidence of the object being a Non-Obstacle. ISO 23150: Potentially moving object classification type  confidence (A.2.12)";
CM_ SG_ 416 RFC_Obj10_PxPyCoVnce "Covariance of Px and Py";
CM_ SG_ 416 RFC_Obj10_PxVxCoVnce "Covariance of Px and Vx";
CM_ SG_ 416 RFC_Obj10_PxVyCoVnce "Covariance of Px and Vy";
CM_ SG_ 416 RFC_Obj10_PyVxCoVnce "Covariance of Py and Vx";
CM_ SG_ 416 RFC_Obj10_PyVyCoVnce "Covariance of Py and Vy";
CM_ SG_ 416 RFC_Obj10_VxVyCoVnce "Covariance of Vx and Vy";
CM_ SG_ 416 RFC_Obj10_PxAxCoVnce "Covariance of Px and Ax";
CM_ SG_ 416 RFC_Obj10_PxAyCoVnce "Covariance of Px and Ay";
CM_ SG_ 416 RFC_Obj10_PyAxCoVnce "Covariance of Py and Ax";
CM_ SG_ 416 RFC_Obj10_PyAyCoVnce "Covariance of Py and Ay";
CM_ SG_ 416 RFC_Obj10_VxAxCoVnce "Covariance of Vx and Ax";
CM_ SG_ 416 RFC_Obj10_VxAyCoVnce "Covariance of Vx and Ay";
CM_ SG_ 416 RFC_Obj10_VyAxCoVnce "Covariance of Vy and Ax";
CM_ SG_ 416 RFC_Obj10_VyAyCoVnce "Covariance of Vy and Ay";
CM_ SG_ 416 RFC_Obj10_AxAyCoVnce "Covariance of Ax and Ay";
CM_ SG_ 416 RFC_Obj10_MobileObstConf "Confidence of the object being a mobile obstacle. ISO 23150: Potentially moving object classification type  confidence (A.2.12)";
CM_ SG_ 416 RFC_Obj10_Mob4PlusWhlConf "Confidence of a mobile object which has 4 or more wheels. ISO 23150: Potentially moving object classification type  confidence (A.2.12)";
CM_ SG_ 416 RFC_Obj10_Mob2WhlConf "Confidence of a mobile object being 2-wheels vehicle. ISO 23150: Potentially moving object classification type  confidence (A.2.12)";
CM_ SG_ 416 RFC_Obj10_MobPedConf "Confidence of a mobile object being a pedestrian. ISO 23150: Potentially moving object classification type  confidence (A.2.12)";
CM_ SG_ 416 RFC_Obj10_FourPlusWhlCarConf "Confidence of a mobile object which has 4 or more wheels--passenger car. ISO 23150: Potentially moving object classification type  confidence (A.2.12)";
CM_ SG_ 416 RFC_Obj10_FourPlusWhlHGVConf "Confidence of a mobile object which has 4 or more wheels--commercial vehicle (Truck). ISO 23150: Potentially moving object classification type  confidence (A.2.12)";
CM_ SG_ 416 RFC_Obj10_GroundReflexConf "Confidence of the object being a ground reflex. ISO 23150: Potentially moving object classification type  confidence (A.2.12)";
CM_ SG_ 416 RFC_Obj10_StatObstConf "Confidence of the object being a stationary obstacle. ISO 23150: Potentially moving object classification type  confidence (A.2.12)";
CM_ SG_ 416 RFC_Obj10_StatBarrierConf "Confidence of the object being a stationary road barrier. ISO 23150: Potentially moving object classification type  confidence (A.2.12)";
CM_ SG_ 417 RFC_Obj11_CRC "CRC - Autosar E2E Profile 5";
CM_ SG_ 417 RFC_Obj11_AliveCtr "Alive counter - Autosar E2E Profile 5";
CM_ SG_ 417 RFC_Obj11_ProtBlockCtr "Protocol-Signal: Block-Counter";
CM_ SG_ 417 RFC_Obj11_ReferencePoint "Reference Point of the detected object. ISO 23150: Reference point (A.2.17)";
CM_ SG_ 417 RFC_Obj11_ObjId "Unique Object ID. ISO 23150: Object ID (A.2.2)";
CM_ SG_ 417 RFC_Obj11_MeasurementStatus "Object is measured or not. ISO 23150: Measurement status  object level (A.2.9)";
CM_ SG_ 417 RFC_Obj11_Px "Object position in X direction. ISO 23150: Position  object level {x, y, z} (A.2.13)";
CM_ SG_ 417 RFC_Obj11_Py "Object position in Y direction. ISO 23150: Position  object level {x, y, z} (A.2.13)";
CM_ SG_ 417 RFC_Obj11_PxVnce "Variance of object position in X direction. ISO 23150: Position  object level {x, y, z}  error (A.2.14)";
CM_ SG_ 417 RFC_Obj11_PyVnce "Variance of object position in Y direction. ISO 23150: Position  object level {x, y, z}  error (A.2.14)";
CM_ SG_ 417 RFC_Obj11_Vx "Object relative velocity in X direction. ISO 23150: Velocity {x, y, z}  object level (A.2.23)";
CM_ SG_ 417 RFC_Obj11_Vy "Object relative velocity in Y direction. ISO 23150: Velocity {x, y, z}  object level (A.2.23)";
CM_ SG_ 417 RFC_Obj11_Ax "Object relative acceleration in X direction. ISO 23150: Acceleration {x, y, z} (A.2.25)";
CM_ SG_ 417 RFC_Obj11_Ay "Object relative acceleration in Y direction. ISO 23150: Acceleration {x, y, z} (A.2.25)";
CM_ SG_ 417 RFC_Obj11_OrientationYaw "Object orientation yaw angle. ISO 23150: Orientation {yaw, pitch, roll} (A.2.15)";
CM_ SG_ 417 RFC_Obj11_ExistProb "Existence probability of object. ISO 23150: Existence probability  object level (A.2.1)";
CM_ SG_ 417 RFC_Obj11_VxVnce "Variance of object relative velocity in X direction. ISO 23150: Velocity {x, y, z}  object level  error (A.2.24)";
CM_ SG_ 417 RFC_Obj11_VyVnce "Variance of object relative velocity in Y direction. ISO 23150: Velocity {x, y, z}  object level  error (A.2.24)";
CM_ SG_ 417 RFC_Obj11_AxVnce "Variance of object relative acceleration in X direction. ISO 23150: Acceleration {x, y, z}  error (A.2.26)";
CM_ SG_ 417 RFC_Obj11_AyVnce "Variance of object relative acceleration in Y direction. ISO 23150: Acceleration {x, y, z}  error (A.2.26)";
CM_ SG_ 417 RFC_Obj11_OrientationYawVnce "Variance of object orientation yaw angle. ISO 23150: Orientation {yaw, pitch, roll}  error (A.2.16)";
CM_ SG_ 417 RFC_Obj11_MovingObserved "Object has been observed moving over the ground since it was first detected";
CM_ SG_ 417 RFC_Obj11_MovingProbability "Object has been observed moving over the ground";
CM_ SG_ 417 RFC_Obj11_Length "Object Length. ISO 23150: Bounding box extent {length, width, height} (A.2.19)";
CM_ SG_ 417 RFC_Obj11_Valid "Object is valid or not";
CM_ SG_ 417 RFC_Obj11_LengthVnce "Variance of object Length. ISO 23150: Bounding box extent {length, width, height}  error (A.2.20)";
CM_ SG_ 417 RFC_Obj11_WidthVnce "Variance of object Width. ISO 23150: Bounding box extent {length, width, height}  error (A.2.20)";
CM_ SG_ 417 RFC_Obj11_Width "Object Width. ISO 23150: Bounding box extent {length, width, height} (A.2.19)";
CM_ SG_ 417 RFC_Obj11_BehaviorType "Indicates that which behavior the object associated for";
CM_ SG_ 417 RFC_Obj11_ObstacleConf "Confidence of the object being an Obstacle. ISO 23150: Potentially moving object classification type  confidence (A.2.12)";
CM_ SG_ 417 RFC_Obj11_NonObstacleConf "Confidence of the object being a Non-Obstacle. ISO 23150: Potentially moving object classification type  confidence (A.2.12)";
CM_ SG_ 417 RFC_Obj11_PxPyCoVnce "Covariance of Px and Py";
CM_ SG_ 417 RFC_Obj11_PxVxCoVnce "Covariance of Px and Vx";
CM_ SG_ 417 RFC_Obj11_PxVyCoVnce "Covariance of Px and Vy";
CM_ SG_ 417 RFC_Obj11_PyVxCoVnce "Covariance of Py and Vx";
CM_ SG_ 417 RFC_Obj11_PyVyCoVnce "Covariance of Py and Vy";
CM_ SG_ 417 RFC_Obj11_VxVyCoVnce "Covariance of Vx and Vy";
CM_ SG_ 417 RFC_Obj11_PxAxCoVnce "Covariance of Px and Ax";
CM_ SG_ 417 RFC_Obj11_PxAyCoVnce "Covariance of Px and Ay";
CM_ SG_ 417 RFC_Obj11_PyAxCoVnce "Covariance of Py and Ax";
CM_ SG_ 417 RFC_Obj11_PyAyCoVnce "Covariance of Py and Ay";
CM_ SG_ 417 RFC_Obj11_VxAxCoVnce "Covariance of Vx and Ax";
CM_ SG_ 417 RFC_Obj11_VxAyCoVnce "Covariance of Vx and Ay";
CM_ SG_ 417 RFC_Obj11_VyAxCoVnce "Covariance of Vy and Ax";
CM_ SG_ 417 RFC_Obj11_VyAyCoVnce "Covariance of Vy and Ay";
CM_ SG_ 417 RFC_Obj11_AxAyCoVnce "Covariance of Ax and Ay";
CM_ SG_ 417 RFC_Obj11_MobileObstConf "Confidence of the object being a mobile obstacle. ISO 23150: Potentially moving object classification type  confidence (A.2.12)";
CM_ SG_ 417 RFC_Obj11_Mob4PlusWhlConf "Confidence of a mobile object which has 4 or more wheels. ISO 23150: Potentially moving object classification type  confidence (A.2.12)";
CM_ SG_ 417 RFC_Obj11_Mob2WhlConf "Confidence of a mobile object being 2-wheels vehicle. ISO 23150: Potentially moving object classification type  confidence (A.2.12)";
CM_ SG_ 417 RFC_Obj11_MobPedConf "Confidence of a mobile object being a pedestrian. ISO 23150: Potentially moving object classification type  confidence (A.2.12)";
CM_ SG_ 417 RFC_Obj11_FourPlusWhlCarConf "Confidence of a mobile object which has 4 or more wheels--passenger car. ISO 23150: Potentially moving object classification type  confidence (A.2.12)";
CM_ SG_ 417 RFC_Obj11_FourPlusWhlHGVConf "Confidence of a mobile object which has 4 or more wheels--commercial vehicle (Truck). ISO 23150: Potentially moving object classification type  confidence (A.2.12)";
CM_ SG_ 417 RFC_Obj11_GroundReflexConf "Confidence of the object being a ground reflex. ISO 23150: Potentially moving object classification type  confidence (A.2.12)";
CM_ SG_ 417 RFC_Obj11_StatObstConf "Confidence of the object being a stationary obstacle. ISO 23150: Potentially moving object classification type  confidence (A.2.12)";
CM_ SG_ 417 RFC_Obj11_StatBarrierConf "Confidence of the object being a stationary road barrier. ISO 23150: Potentially moving object classification type  confidence (A.2.12)";
BA_DEF_ BO_  "CANFD_BRS" ENUM  "0","1";
BA_DEF_ BO_  "GenMsgCycleTime" INT 0 65535;
BA_DEF_ BO_  "GenMsgSendType" ENUM  "Event","cyclic";
BA_DEF_ BO_  "VFrameFormat" ENUM  "StandardCAN","ExtendedCAN","reserved","reserved","reserved","reserved","reserved","reserved","reserved","reserved","reserved","reserved","reserved","reserved","StandardCAN_FD","ExtendedCAN_FD";
BA_DEF_ BO_  "E2Eprofile" STRING ;
BA_DEF_ BO_  "DataID" HEX 0 655535;
BA_DEF_ SG_  "GenSigStartValue" FLOAT 0 100000000000;
BA_DEF_  "BusType" STRING ;
BA_DEF_  "DBName" STRING ;
BA_DEF_DEF_  "CANFD_BRS" "1";
BA_DEF_DEF_  "GenMsgCycleTime" 0;
BA_DEF_DEF_  "GenMsgSendType" "";
BA_DEF_DEF_  "VFrameFormat" "";
BA_DEF_DEF_  "E2Eprofile" "None";
BA_DEF_DEF_  "DataID" 0;
BA_DEF_DEF_  "GenSigStartValue" 0;
BA_DEF_DEF_  "BusType" "";
BA_DEF_DEF_  "DBName" "ChooseYourNameHere";
BA_ "BusType" "CAN FD";
BA_ "DBName" "OD_1V3R_VFC_RFC_RFL_RFR";
BA_ "DataID" BO_ 16 8208;
BA_ "E2Eprofile" BO_ 16 "AUTOSAR Profile 22";
BA_ "GenMsgSendType" BO_ 16 0;
BA_ "VFrameFormat" BO_ 16 14;
BA_ "DataID" BO_ 19 8211;
BA_ "E2Eprofile" BO_ 19 "AUTOSAR Profile 22";
BA_ "GenMsgSendType" BO_ 19 0;
BA_ "VFrameFormat" BO_ 19 14;
BA_ "DataID" BO_ 20 8212;
BA_ "E2Eprofile" BO_ 20 "AUTOSAR Profile 22";
BA_ "GenMsgSendType" BO_ 20 0;
BA_ "VFrameFormat" BO_ 20 14;
BA_ "DataID" BO_ 32 8224;
BA_ "E2Eprofile" BO_ 32 "AUTOSAR Profile 5";
BA_ "GenMsgSendType" BO_ 32 0;
BA_ "VFrameFormat" BO_ 32 14;
BA_ "DataID" BO_ 33 8225;
BA_ "E2Eprofile" BO_ 33 "AUTOSAR Profile 22";
BA_ "GenMsgSendType" BO_ 33 1;
BA_ "GenMsgCycleTime" BO_ 33 50;
BA_ "VFrameFormat" BO_ 33 14;
BA_ "DataID" BO_ 35 8227;
BA_ "E2Eprofile" BO_ 35 "AUTOSAR Profile 22";
BA_ "GenMsgSendType" BO_ 35 1;
BA_ "GenMsgCycleTime" BO_ 35 50;
BA_ "VFrameFormat" BO_ 35 14;
BA_ "DataID" BO_ 36 8228;
BA_ "E2Eprofile" BO_ 36 "AUTOSAR Profile 22";
BA_ "GenMsgSendType" BO_ 36 1;
BA_ "GenMsgCycleTime" BO_ 36 50;
BA_ "VFrameFormat" BO_ 36 14;
BA_ "DataID" BO_ 404 8596;
BA_ "E2Eprofile" BO_ 404 "AUTOSAR Profile 5";
BA_ "GenMsgSendType" BO_ 404 0;
BA_ "VFrameFormat" BO_ 404 14;
BA_ "DataID" BO_ 406 8598;
BA_ "E2Eprofile" BO_ 406 "AUTOSAR Profile 5";
BA_ "GenMsgSendType" BO_ 406 0;
BA_ "VFrameFormat" BO_ 406 14;
BA_ "DataID" BO_ 407 8599;
BA_ "E2Eprofile" BO_ 407 "AUTOSAR Profile 5";
BA_ "GenMsgSendType" BO_ 407 0;
BA_ "VFrameFormat" BO_ 407 14;
BA_ "DataID" BO_ 408 8600;
BA_ "E2Eprofile" BO_ 408 "AUTOSAR Profile 5";
BA_ "GenMsgSendType" BO_ 408 0;
BA_ "VFrameFormat" BO_ 408 14;
BA_ "DataID" BO_ 409 8601;
BA_ "E2Eprofile" BO_ 409 "AUTOSAR Profile 5";
BA_ "GenMsgSendType" BO_ 409 0;
BA_ "VFrameFormat" BO_ 409 14;
BA_ "DataID" BO_ 410 8602;
BA_ "E2Eprofile" BO_ 410 "AUTOSAR Profile 5";
BA_ "GenMsgSendType" BO_ 410 0;
BA_ "VFrameFormat" BO_ 410 14;
BA_ "DataID" BO_ 411 8603;
BA_ "E2Eprofile" BO_ 411 "AUTOSAR Profile 5";
BA_ "GenMsgSendType" BO_ 411 0;
BA_ "VFrameFormat" BO_ 411 14;
BA_ "DataID" BO_ 412 8604;
BA_ "E2Eprofile" BO_ 412 "AUTOSAR Profile 5";
BA_ "GenMsgSendType" BO_ 412 0;
BA_ "VFrameFormat" BO_ 412 14;
BA_ "DataID" BO_ 413 8605;
BA_ "E2Eprofile" BO_ 413 "AUTOSAR Profile 5";
BA_ "GenMsgSendType" BO_ 413 0;
BA_ "VFrameFormat" BO_ 413 14;
BA_ "DataID" BO_ 414 8606;
BA_ "E2Eprofile" BO_ 414 "AUTOSAR Profile 5";
BA_ "GenMsgSendType" BO_ 414 0;
BA_ "VFrameFormat" BO_ 414 14;
BA_ "DataID" BO_ 415 8607;
BA_ "E2Eprofile" BO_ 415 "AUTOSAR Profile 5";
BA_ "GenMsgSendType" BO_ 415 0;
BA_ "VFrameFormat" BO_ 415 14;
BA_ "DataID" BO_ 416 8608;
BA_ "E2Eprofile" BO_ 416 "AUTOSAR Profile 5";
BA_ "GenMsgSendType" BO_ 416 0;
BA_ "VFrameFormat" BO_ 416 14;
BA_ "DataID" BO_ 417 8609;
BA_ "E2Eprofile" BO_ 417 "AUTOSAR Profile 5";
BA_ "GenMsgSendType" BO_ 417 0;
BA_ "VFrameFormat" BO_ 417 14;
BA_ "GenSigStartValue" SG_ 16 VFC_Ax_CommandValue 834;
BA_ "GenSigStartValue" SG_ 19 RFL_Ax_CommandValue 834;
BA_ "GenSigStartValue" SG_ 20 RFR_Ax_CommandValue 834;
BA_ "GenSigStartValue" SG_ 32 VFC_Status_SensorOrientYaw 512;
BA_ "GenSigStartValue" SG_ 32 VFC_Status_SensorOrientPitch 512;
BA_ "GenSigStartValue" SG_ 32 VFC_Status_SensorOrientRoll 512;
BA_ "GenSigStartValue" SG_ 32 VFC_Status_SensorOriginPointX 4096;
BA_ "GenSigStartValue" SG_ 32 VFC_Status_SensorOriginPointY 2048;
BA_ "GenSigStartValue" SG_ 404 RFC_ObjHdr_IfVersionIdMajor 1;
BA_ "GenSigStartValue" SG_ 404 RFC_ObjHdr_IfVersionIdMinor 1;
BA_ "GenSigStartValue" SG_ 404 RFC_ObjHdr_SensorOriginPointY 128;
BA_ "GenSigStartValue" SG_ 404 RFC_ObjHdr_SensorOriginPointX 256;
BA_ "GenSigStartValue" SG_ 404 RFC_ObjHdr_SensorOrientYaw 32768;
BA_ "GenSigStartValue" SG_ 404 RFC_ObjHdr_SensorOrientPitch 2048;
BA_ "GenSigStartValue" SG_ 404 RFC_ObjHdr_SensorOrientRoll 2048;
BA_ "GenSigStartValue" SG_ 404 RFC_ObjHdr_FovAzimuthBegin 16384;
BA_ "GenSigStartValue" SG_ 404 RFC_ObjHdr_FovAzimuthEnd 16384;
BA_ "GenSigStartValue" SG_ 404 RFC_ObjHdr_FovElevationBegin 2048;
BA_ "GenSigStartValue" SG_ 404 RFC_ObjHdr_FovElevationEnd 2048;
BA_ "GenSigStartValue" SG_ 406 RFC_Obj00_Px 4096;
BA_ "GenSigStartValue" SG_ 406 RFC_Obj00_Py 1024;
BA_ "GenSigStartValue" SG_ 406 RFC_Obj00_Vx 2048;
BA_ "GenSigStartValue" SG_ 406 RFC_Obj00_Vy 512;
BA_ "GenSigStartValue" SG_ 406 RFC_Obj00_Ax 512;
BA_ "GenSigStartValue" SG_ 406 RFC_Obj00_Ay 256;
BA_ "GenSigStartValue" SG_ 406 RFC_Obj00_OrientationYaw 256;
BA_ "GenSigStartValue" SG_ 407 RFC_Obj01_Px 4096;
BA_ "GenSigStartValue" SG_ 407 RFC_Obj01_Py 1024;
BA_ "GenSigStartValue" SG_ 407 RFC_Obj01_Vx 2048;
BA_ "GenSigStartValue" SG_ 407 RFC_Obj01_Vy 512;
BA_ "GenSigStartValue" SG_ 407 RFC_Obj01_Ax 512;
BA_ "GenSigStartValue" SG_ 407 RFC_Obj01_Ay 256;
BA_ "GenSigStartValue" SG_ 407 RFC_Obj01_OrientationYaw 256;
BA_ "GenSigStartValue" SG_ 408 RFC_Obj02_Px 4096;
BA_ "GenSigStartValue" SG_ 408 RFC_Obj02_Py 1024;
BA_ "GenSigStartValue" SG_ 408 RFC_Obj02_Vx 2048;
BA_ "GenSigStartValue" SG_ 408 RFC_Obj02_Vy 512;
BA_ "GenSigStartValue" SG_ 408 RFC_Obj02_Ax 512;
BA_ "GenSigStartValue" SG_ 408 RFC_Obj02_Ay 256;
BA_ "GenSigStartValue" SG_ 408 RFC_Obj02_OrientationYaw 256;
BA_ "GenSigStartValue" SG_ 409 RFC_Obj03_Px 4096;
BA_ "GenSigStartValue" SG_ 409 RFC_Obj03_Py 1024;
BA_ "GenSigStartValue" SG_ 409 RFC_Obj03_Vx 2048;
BA_ "GenSigStartValue" SG_ 409 RFC_Obj03_Vy 512;
BA_ "GenSigStartValue" SG_ 409 RFC_Obj03_Ax 512;
BA_ "GenSigStartValue" SG_ 409 RFC_Obj03_Ay 256;
BA_ "GenSigStartValue" SG_ 409 RFC_Obj03_OrientationYaw 256;
BA_ "GenSigStartValue" SG_ 410 RFC_Obj04_Px 4096;
BA_ "GenSigStartValue" SG_ 410 RFC_Obj04_Py 1024;
BA_ "GenSigStartValue" SG_ 410 RFC_Obj04_Vx 2048;
BA_ "GenSigStartValue" SG_ 410 RFC_Obj04_Vy 512;
BA_ "GenSigStartValue" SG_ 410 RFC_Obj04_Ax 512;
BA_ "GenSigStartValue" SG_ 410 RFC_Obj04_Ay 256;
BA_ "GenSigStartValue" SG_ 410 RFC_Obj04_OrientationYaw 256;
BA_ "GenSigStartValue" SG_ 411 RFC_Obj05_Px 4096;
BA_ "GenSigStartValue" SG_ 411 RFC_Obj05_Py 1024;
BA_ "GenSigStartValue" SG_ 411 RFC_Obj05_Vx 2048;
BA_ "GenSigStartValue" SG_ 411 RFC_Obj05_Vy 512;
BA_ "GenSigStartValue" SG_ 411 RFC_Obj05_Ax 512;
BA_ "GenSigStartValue" SG_ 411 RFC_Obj05_Ay 256;
BA_ "GenSigStartValue" SG_ 411 RFC_Obj05_OrientationYaw 256;
BA_ "GenSigStartValue" SG_ 412 RFC_Obj06_Px 4096;
BA_ "GenSigStartValue" SG_ 412 RFC_Obj06_Py 1024;
BA_ "GenSigStartValue" SG_ 412 RFC_Obj06_Vx 2048;
BA_ "GenSigStartValue" SG_ 412 RFC_Obj06_Vy 512;
BA_ "GenSigStartValue" SG_ 412 RFC_Obj06_Ax 512;
BA_ "GenSigStartValue" SG_ 412 RFC_Obj06_Ay 256;
BA_ "GenSigStartValue" SG_ 412 RFC_Obj06_OrientationYaw 256;
BA_ "GenSigStartValue" SG_ 413 RFC_Obj07_Px 4096;
BA_ "GenSigStartValue" SG_ 413 RFC_Obj07_Py 1024;
BA_ "GenSigStartValue" SG_ 413 RFC_Obj07_Vx 2048;
BA_ "GenSigStartValue" SG_ 413 RFC_Obj07_Vy 512;
BA_ "GenSigStartValue" SG_ 413 RFC_Obj07_Ax 512;
BA_ "GenSigStartValue" SG_ 413 RFC_Obj07_Ay 256;
BA_ "GenSigStartValue" SG_ 413 RFC_Obj07_OrientationYaw 256;
BA_ "GenSigStartValue" SG_ 414 RFC_Obj08_Px 4096;
BA_ "GenSigStartValue" SG_ 414 RFC_Obj08_Py 1024;
BA_ "GenSigStartValue" SG_ 414 RFC_Obj08_Vx 2048;
BA_ "GenSigStartValue" SG_ 414 RFC_Obj08_Vy 512;
BA_ "GenSigStartValue" SG_ 414 RFC_Obj08_Ax 512;
BA_ "GenSigStartValue" SG_ 414 RFC_Obj08_Ay 256;
BA_ "GenSigStartValue" SG_ 414 RFC_Obj08_OrientationYaw 256;
BA_ "GenSigStartValue" SG_ 415 RFC_Obj09_Px 4096;
BA_ "GenSigStartValue" SG_ 415 RFC_Obj09_Py 1024;
BA_ "GenSigStartValue" SG_ 415 RFC_Obj09_Vx 2048;
BA_ "GenSigStartValue" SG_ 415 RFC_Obj09_Vy 512;
BA_ "GenSigStartValue" SG_ 415 RFC_Obj09_Ax 512;
BA_ "GenSigStartValue" SG_ 415 RFC_Obj09_Ay 256;
BA_ "GenSigStartValue" SG_ 415 RFC_Obj09_OrientationYaw 256;
BA_ "GenSigStartValue" SG_ 416 RFC_Obj10_Px 4096;
BA_ "GenSigStartValue" SG_ 416 RFC_Obj10_Py 1024;
BA_ "GenSigStartValue" SG_ 416 RFC_Obj10_Vx 2048;
BA_ "GenSigStartValue" SG_ 416 RFC_Obj10_Vy 512;
BA_ "GenSigStartValue" SG_ 416 RFC_Obj10_Ax 512;
BA_ "GenSigStartValue" SG_ 416 RFC_Obj10_Ay 256;
BA_ "GenSigStartValue" SG_ 416 RFC_Obj10_OrientationYaw 256;
BA_ "GenSigStartValue" SG_ 417 RFC_Obj11_Px 4096;
BA_ "GenSigStartValue" SG_ 417 RFC_Obj11_Py 1024;
BA_ "GenSigStartValue" SG_ 417 RFC_Obj11_Vx 2048;
BA_ "GenSigStartValue" SG_ 417 RFC_Obj11_Vy 512;
BA_ "GenSigStartValue" SG_ 417 RFC_Obj11_Ax 512;
BA_ "GenSigStartValue" SG_ 417 RFC_Obj11_Ay 256;
BA_ "GenSigStartValue" SG_ 417 RFC_Obj11_OrientationYaw 256;
VAL_ 32 VFC_Status_RollerBenchState 0 "no_roller_bench_mode" 1 "generic_roller_bench_mode" 2 "full_perf_roller_bench_mode" 3 "Reserved3" ;
VAL_ 32 VFC_Status_SensorState 0 "Camera SysFullOperational" 1 "Camera Initialization" 2 "Camera Limited (reduced Mode)" 3 "Camera TemporaryBlocked" 4 "Camera StableBlocked" 5 "Camera Error" 6 "Camera CalibrationOnGoing" 7 "Camera Decalibrated" 8 "Camera Shutdown" 9 "Reserved9" 10 "Reserved10" 11 "Reserved11" 12 "Reserved12" 13 "Reserved13" 14 "Reserved14" 15 "Reserved15" ;
VAL_ 32 VFC_Status_CalibrationState 0 "OK" 1 "NOK" 2 "INIT" 3 "Undefined" 4 "Reserved4" 5 "Reserved5" 6 "Reserved6" 7 "Reserved7" ;
VAL_ 32 VFC_Status_TrafficFlowType 0 "Right_Hand_Traffic" 1 "Left_Hand_Traffic" ;
VAL_ 33 RFC_Status_ModulationStatus 0 "Normal operation" 1 "Time sync failure" 2 "Modulation failure" 3 "Reserved" ;
VAL_ 35 RFL_Status_ModulationStatus 0 "Normal operation" 1 "Time sync failure" 2 "Modulation failure" 3 "Reserved" ;
VAL_ 36 RFR_Status_ModulationStatus 0 "Normal operation" 1 "Time sync failure" 2 "Modulation failure" 3 "Reserved" ;
VAL_ 404 RFC_ObjHdr_AziOutOfSpec 0 "In spec Azimuth Alignemdn" 1 "Out of spec Azimuth Alignement" ;
VAL_ 404 RFC_ObjHdr_ElevOutOfSpec 0 "In Spec Elevation Alignment" 1 "Out of spec Elevation Alignement" ;
VAL_ 404 RFC_ObjHdr_ObjectDownSel 0 "no downselection" 1 "downselected" ;
VAL_ 406 RFC_Obj00_ReferencePoint 0 "Front corner left" 1 "Front center" 2 "Front corner right" 3 "Front wheelcase left" 4 "Front wheelcase right" 5 "Side middle left" 6 "Side middle right" 7 "Rear wheelcase left" 8 "Rear wheelcase right" 9 "Rear corner left" 10 "Rear center" 11 "Rear corner right" 12 "Object center" 13 "Rear wheelcase center" 14 "Front wheelcase center" 15 "Invalid" ;
VAL_ 406 RFC_Obj00_MeasurementStatus 0 "not measured" 1 "measured" ;
VAL_ 406 RFC_Obj00_Valid 0 "not valid" 1 "valid" ;
VAL_ 406 RFC_Obj00_BehaviorType 0 "No_Target" 1 "FCTA" 2 "RCTA" 3 "BSD" 4 "LCA" 5 "HWA" 6 "Reserved1" 7 "Reserved2" ;
VAL_ 407 RFC_Obj01_ReferencePoint 0 "Front corner left" 1 "Front center" 2 "Front corner right" 3 "Front wheelcase left" 4 "Front wheelcase right" 5 "Side middle left" 6 "Side middle right" 7 "Rear wheelcase left" 8 "Rear wheelcase right" 9 "Rear corner left" 10 "Rear center" 11 "Rear corner right" 12 "Object center" 13 "Rear wheelcase center" 14 "Front wheelcase center" 15 "Invalid" ;
VAL_ 407 RFC_Obj01_MeasurementStatus 0 "not measured" 1 "measured" ;
VAL_ 407 RFC_Obj01_Valid 0 "not valid" 1 "valid" ;
VAL_ 407 RFC_Obj01_BehaviorType 0 "No_Target" 1 "FCTA" 2 "RCTA" 3 "BSD" 4 "LCA" 5 "HWA" 6 "Reserved1" 7 "Reserved2" ;
VAL_ 408 RFC_Obj02_ReferencePoint 0 "Front corner left" 1 "Front center" 2 "Front corner right" 3 "Front wheelcase left" 4 "Front wheelcase right" 5 "Side middle left" 6 "Side middle right" 7 "Rear wheelcase left" 8 "Rear wheelcase right" 9 "Rear corner left" 10 "Rear center" 11 "Rear corner right" 12 "Object center" 13 "Rear wheelcase center" 14 "Front wheelcase center" 15 "Invalid" ;
VAL_ 408 RFC_Obj02_MeasurementStatus 0 "not measured" 1 "measured" ;
VAL_ 408 RFC_Obj02_Valid 0 "not valid" 1 "valid" ;
VAL_ 408 RFC_Obj02_BehaviorType 0 "No_Target" 1 "FCTA" 2 "RCTA" 3 "BSD" 4 "LCA" 5 "HWA" 6 "Reserved1" 7 "Reserved2" ;
VAL_ 409 RFC_Obj03_ReferencePoint 0 "Front corner left" 1 "Front center" 2 "Front corner right" 3 "Front wheelcase left" 4 "Front wheelcase right" 5 "Side middle left" 6 "Side middle right" 7 "Rear wheelcase left" 8 "Rear wheelcase right" 9 "Rear corner left" 10 "Rear center" 11 "Rear corner right" 12 "Object center" 13 "Rear wheelcase center" 14 "Front wheelcase center" 15 "Invalid" ;
VAL_ 409 RFC_Obj03_MeasurementStatus 0 "not measured" 1 "measured" ;
VAL_ 409 RFC_Obj03_Valid 0 "not valid" 1 "valid" ;
VAL_ 409 RFC_Obj03_BehaviorType 0 "No_Target" 1 "FCTA" 2 "RCTA" 3 "BSD" 4 "LCA" 5 "HWA" 6 "Reserved1" 7 "Reserved2" ;
VAL_ 410 RFC_Obj04_ReferencePoint 0 "Front corner left" 1 "Front center" 2 "Front corner right" 3 "Front wheelcase left" 4 "Front wheelcase right" 5 "Side middle left" 6 "Side middle right" 7 "Rear wheelcase left" 8 "Rear wheelcase right" 9 "Rear corner left" 10 "Rear center" 11 "Rear corner right" 12 "Object center" 13 "Rear wheelcase center" 14 "Front wheelcase center" 15 "Invalid" ;
VAL_ 410 RFC_Obj04_MeasurementStatus 0 "not measured" 1 "measured" ;
VAL_ 410 RFC_Obj04_Valid 0 "not valid" 1 "valid" ;
VAL_ 410 RFC_Obj04_BehaviorType 0 "No_Target" 1 "FCTA" 2 "RCTA" 3 "BSD" 4 "LCA" 5 "HWA" 6 "Reserved1" 7 "Reserved2" ;
VAL_ 411 RFC_Obj05_ReferencePoint 0 "Front corner left" 1 "Front center" 2 "Front corner right" 3 "Front wheelcase left" 4 "Front wheelcase right" 5 "Side middle left" 6 "Side middle right" 7 "Rear wheelcase left" 8 "Rear wheelcase right" 9 "Rear corner left" 10 "Rear center" 11 "Rear corner right" 12 "Object center" 13 "Rear wheelcase center" 14 "Front wheelcase center" 15 "Invalid" ;
VAL_ 411 RFC_Obj05_MeasurementStatus 0 "not measured" 1 "measured" ;
VAL_ 411 RFC_Obj05_Valid 0 "not valid" 1 "valid" ;
VAL_ 411 RFC_Obj05_BehaviorType 0 "No_Target" 1 "FCTA" 2 "RCTA" 3 "BSD" 4 "LCA" 5 "HWA" 6 "Reserved1" 7 "Reserved2" ;
VAL_ 412 RFC_Obj06_ReferencePoint 0 "Front corner left" 1 "Front center" 2 "Front corner right" 3 "Front wheelcase left" 4 "Front wheelcase right" 5 "Side middle left" 6 "Side middle right" 7 "Rear wheelcase left" 8 "Rear wheelcase right" 9 "Rear corner left" 10 "Rear center" 11 "Rear corner right" 12 "Object center" 13 "Rear wheelcase center" 14 "Front wheelcase center" 15 "Invalid" ;
VAL_ 412 RFC_Obj06_MeasurementStatus 0 "not measured" 1 "measured" ;
VAL_ 412 RFC_Obj06_Valid 0 "not valid" 1 "valid" ;
VAL_ 412 RFC_Obj06_BehaviorType 0 "No_Target" 1 "FCTA" 2 "RCTA" 3 "BSD" 4 "LCA" 5 "HWA" 6 "Reserved1" 7 "Reserved2" ;
VAL_ 413 RFC_Obj07_ReferencePoint 0 "Front corner left" 1 "Front center" 2 "Front corner right" 3 "Front wheelcase left" 4 "Front wheelcase right" 5 "Side middle left" 6 "Side middle right" 7 "Rear wheelcase left" 8 "Rear wheelcase right" 9 "Rear corner left" 10 "Rear center" 11 "Rear corner right" 12 "Object center" 13 "Rear wheelcase center" 14 "Front wheelcase center" 15 "Invalid" ;
VAL_ 413 RFC_Obj07_MeasurementStatus 0 "not measured" 1 "measured" ;
VAL_ 413 RFC_Obj07_Valid 0 "not valid" 1 "valid" ;
VAL_ 413 RFC_Obj07_BehaviorType 0 "No_Target" 1 "FCTA" 2 "RCTA" 3 "BSD" 4 "LCA" 5 "HWA" 6 "Reserved1" 7 "Reserved2" ;
VAL_ 414 RFC_Obj08_ReferencePoint 0 "Front corner left" 1 "Front center" 2 "Front corner right" 3 "Front wheelcase left" 4 "Front wheelcase right" 5 "Side middle left" 6 "Side middle right" 7 "Rear wheelcase left" 8 "Rear wheelcase right" 9 "Rear corner left" 10 "Rear center" 11 "Rear corner right" 12 "Object center" 13 "Rear wheelcase center" 14 "Front wheelcase center" 15 "Invalid" ;
VAL_ 414 RFC_Obj08_MeasurementStatus 0 "not measured" 1 "measured" ;
VAL_ 414 RFC_Obj08_Valid 0 "not valid" 1 "valid" ;
VAL_ 414 RFC_Obj08_BehaviorType 0 "No_Target" 1 "FCTA" 2 "RCTA" 3 "BSD" 4 "LCA" 5 "HWA" 6 "Reserved1" 7 "Reserved2" ;
VAL_ 415 RFC_Obj09_ReferencePoint 0 "Front corner left" 1 "Front center" 2 "Front corner right" 3 "Front wheelcase left" 4 "Front wheelcase right" 5 "Side middle left" 6 "Side middle right" 7 "Rear wheelcase left" 8 "Rear wheelcase right" 9 "Rear corner left" 10 "Rear center" 11 "Rear corner right" 12 "Object center" 13 "Rear wheelcase center" 14 "Front wheelcase center" 15 "Invalid" ;
VAL_ 415 RFC_Obj09_MeasurementStatus 0 "not measured" 1 "measured" ;
VAL_ 415 RFC_Obj09_Valid 0 "not valid" 1 "valid" ;
VAL_ 415 RFC_Obj09_BehaviorType 0 "No_Target" 1 "FCTA" 2 "RCTA" 3 "BSD" 4 "LCA" 5 "HWA" 6 "Reserved1" 7 "Reserved2" ;
VAL_ 416 RFC_Obj10_ReferencePoint 0 "Front corner left" 1 "Front center" 2 "Front corner right" 3 "Front wheelcase left" 4 "Front wheelcase right" 5 "Side middle left" 6 "Side middle right" 7 "Rear wheelcase left" 8 "Rear wheelcase right" 9 "Rear corner left" 10 "Rear center" 11 "Rear corner right" 12 "Object center" 13 "Rear wheelcase center" 14 "Front wheelcase center" 15 "Invalid" ;
VAL_ 416 RFC_Obj10_MeasurementStatus 0 "not measured" 1 "measured" ;
VAL_ 416 RFC_Obj10_Valid 0 "not valid" 1 "valid" ;
VAL_ 416 RFC_Obj10_BehaviorType 0 "No_Target" 1 "FCTA" 2 "RCTA" 3 "BSD" 4 "LCA" 5 "HWA" 6 "Reserved1" 7 "Reserved2" ;
VAL_ 417 RFC_Obj11_ReferencePoint 0 "Front corner left" 1 "Front center" 2 "Front corner right" 3 "Front wheelcase left" 4 "Front wheelcase right" 5 "Side middle left" 6 "Side middle right" 7 "Rear wheelcase left" 8 "Rear wheelcase right" 9 "Rear corner left" 10 "Rear center" 11 "Rear corner right" 12 "Object center" 13 "Rear wheelcase center" 14 "Front wheelcase center" 15 "Invalid" ;
VAL_ 417 RFC_Obj11_MeasurementStatus 0 "not measured" 1 "measured" ;
VAL_ 417 RFC_Obj11_Valid 0 "not valid" 1 "valid" ;
VAL_ 417 RFC_Obj11_BehaviorType 0 "No_Target" 1 "FCTA" 2 "RCTA" 3 "BSD" 4 "LCA" 5 "HWA" 6 "Reserved1" 7 "Reserved2" ;
SIG_GROUP_ 16 SG_VFC_AEB_Request 1 : VFC_AEB_CRC VFC_AEB_AC VFC_AEB_FPC VFC_AEB_CU VFC_AEB_VRU VFC_AEB_VRUTA VFC_AEB_LTA VFC_Ax_CommandValue VFC_AEB_ObjID VFC_AEB_DummyForFuture;
SIG_GROUP_ 19 SG_RFL_AEB_Request 1 : RFL_AEB_CRC RFL_AEB_AC RFL_AEB_FPC RFL_AEB_CU RFL_AEB_VRU RFL_AEB_VRUTA RFL_AEB_LTA RFL_Ax_CommandValue RFL_AEB_ObjID RFL_AEB_DummyForFuture;
SIG_GROUP_ 20 SG_RFR_AEB_Request 1 : RFR_AEB_CRC RFR_AEB_AC RFR_AEB_FPC RFR_AEB_CU RFR_AEB_VRU RFR_AEB_VRUTA RFR_AEB_LTA RFR_Ax_CommandValue RFR_AEB_ObjID RFR_AEB_DummyForFuture;
SIG_GROUP_ 32 SG_VFC_Status 1 : VFC_Status_CRC VFC_Status_AliveCtr VFC_Status_SensorOrientYaw VFC_Status_SensorOrientPitch VFC_Status_SensorOrientRoll VFC_Status_TimeStampStatus VFC_Status_TimeStamp VFC_Status_FrameNumber VFC_Status_SensorOriginPointX VFC_Status_SensorOriginPointY VFC_Status_SensorOriginPointZ VFC_Status_RollerBenchState VFC_Status_SensorState VFC_Status_CalibrationState VFC_Status_TrafficFlowType;
SIG_GROUP_ 33 SG_RFC_Status 1 : RFC_Status_CRC RFC_Status_AliveCtr RFC_Status_ModulationStatus RFC_Status_SensorStatus;
SIG_GROUP_ 35 SG_RFL_Status 1 : RFL_Status_CRC RFL_Status_AliveCtr RFL_Status_ModulationStatus RFL_Status_SensorStatus;
SIG_GROUP_ 36 SG_RFR_Status 1 : RFR_Status_CRC RFR_Status_AliveCtr RFR_Status_ModulationStatus RFR_Status_SensorStatus;
SIG_GROUP_ 404 SG_RFC_ObjHdr 1 : RFC_ObjHdr_CRC RFC_ObjHdr_AliveCtr RFC_ObjHdr_ProtBlockCtr RFC_ObjHdr_IfVersionIdMajor RFC_ObjHdr_IfVersionIdMinor RFC_ObjHdr_NumValidObjects RFC_ObjHdr_TimeStampStatus RFC_ObjHdr_TimeStamp RFC_ObjHdr_SensorState RFC_ObjHdr_AziOutOfSpec RFC_ObjHdr_ElevOutOfSpec RFC_ObjHdr_ObjectDownSel RFC_ObjHdr_SensorOriginPointY RFC_ObjHdr_SensorOriginPointX RFC_ObjHdr_SensorOriginPointZ RFC_ObjHdr_SensorOrientYaw RFC_ObjHdr_SensorOrientPitch RFC_ObjHdr_SensorOrientRoll RFC_ObjHdr_FovAzimuthBegin RFC_ObjHdr_FovAzimuthEnd RFC_ObjHdr_FovElevationBegin RFC_ObjHdr_FovElevationEnd RFC_ObjHdr_DetectionRange RFC_ObjHdr_TimeStampLocal;
SIG_GROUP_ 406 SG_RFC_Obj00 1 : RFC_Obj00_CRC RFC_Obj00_AliveCtr RFC_Obj00_ProtBlockCtr RFC_Obj00_ReferencePoint RFC_Obj00_ObjId RFC_Obj00_MeasurementStatus RFC_Obj00_Px RFC_Obj00_Py RFC_Obj00_PxVnce RFC_Obj00_PyVnce RFC_Obj00_Vx RFC_Obj00_Vy RFC_Obj00_Ax RFC_Obj00_Ay RFC_Obj00_OrientationYaw RFC_Obj00_ExistProb RFC_Obj00_VxVnce RFC_Obj00_VyVnce RFC_Obj00_AxVnce RFC_Obj00_AyVnce RFC_Obj00_OrientationYawVnce RFC_Obj00_MovingObserved RFC_Obj00_MovingProbability RFC_Obj00_Length RFC_Obj00_Valid RFC_Obj00_LengthVnce RFC_Obj00_WidthVnce RFC_Obj00_Width RFC_Obj00_BehaviorType RFC_Obj00_ObstacleConf RFC_Obj00_NonObstacleConf RFC_Obj00_PxPyCoVnce RFC_Obj00_PxVxCoVnce RFC_Obj00_PxVyCoVnce RFC_Obj00_PyVxCoVnce RFC_Obj00_PyVyCoVnce RFC_Obj00_VxVyCoVnce RFC_Obj00_PxAxCoVnce RFC_Obj00_PxAyCoVnce RFC_Obj00_PyAxCoVnce RFC_Obj00_PyAyCoVnce RFC_Obj00_VxAxCoVnce RFC_Obj00_VxAyCoVnce RFC_Obj00_VyAxCoVnce RFC_Obj00_VyAyCoVnce RFC_Obj00_AxAyCoVnce RFC_Obj00_MobileObstConf RFC_Obj00_Mob4PlusWhlConf RFC_Obj00_Mob2WhlConf RFC_Obj00_MobPedConf RFC_Obj00_FourPlusWhlCarConf RFC_Obj00_FourPlusWhlHGVConf RFC_Obj00_GroundReflexConf RFC_Obj00_StatObstConf RFC_Obj00_StatBarrierConf;
SIG_GROUP_ 407 SG_RFC_Obj01 1 : RFC_Obj01_CRC RFC_Obj01_AliveCtr RFC_Obj01_ProtBlockCtr RFC_Obj01_ReferencePoint RFC_Obj01_ObjId RFC_Obj01_MeasurementStatus RFC_Obj01_Px RFC_Obj01_Py RFC_Obj01_PxVnce RFC_Obj01_PyVnce RFC_Obj01_Vx RFC_Obj01_Vy RFC_Obj01_Ax RFC_Obj01_Ay RFC_Obj01_OrientationYaw RFC_Obj01_ExistProb RFC_Obj01_VxVnce RFC_Obj01_VyVnce RFC_Obj01_AxVnce RFC_Obj01_AyVnce RFC_Obj01_OrientationYawVnce RFC_Obj01_MovingObserved RFC_Obj01_MovingProbability RFC_Obj01_Length RFC_Obj01_Valid RFC_Obj01_LengthVnce RFC_Obj01_WidthVnce RFC_Obj01_Width RFC_Obj01_BehaviorType RFC_Obj01_ObstacleConf RFC_Obj01_NonObstacleConf RFC_Obj01_PxPyCoVnce RFC_Obj01_PxVxCoVnce RFC_Obj01_PxVyCoVnce RFC_Obj01_PyVxCoVnce RFC_Obj01_PyVyCoVnce RFC_Obj01_VxVyCoVnce RFC_Obj01_PxAxCoVnce RFC_Obj01_PxAyCoVnce RFC_Obj01_PyAxCoVnce RFC_Obj01_PyAyCoVnce RFC_Obj01_VxAxCoVnce RFC_Obj01_VxAyCoVnce RFC_Obj01_VyAxCoVnce RFC_Obj01_VyAyCoVnce RFC_Obj01_AxAyCoVnce RFC_Obj01_MobileObstConf RFC_Obj01_Mob4PlusWhlConf RFC_Obj01_Mob2WhlConf RFC_Obj01_MobPedConf RFC_Obj01_FourPlusWhlCarConf RFC_Obj01_FourPlusWhlHGVConf RFC_Obj01_GroundReflexConf RFC_Obj01_StatObstConf RFC_Obj01_StatBarrierConf;
SIG_GROUP_ 408 SG_RFC_Obj02 1 : RFC_Obj02_CRC RFC_Obj02_AliveCtr RFC_Obj02_ProtBlockCtr RFC_Obj02_ReferencePoint RFC_Obj02_ObjId RFC_Obj02_MeasurementStatus RFC_Obj02_Px RFC_Obj02_Py RFC_Obj02_PxVnce RFC_Obj02_PyVnce RFC_Obj02_Vx RFC_Obj02_Vy RFC_Obj02_Ax RFC_Obj02_Ay RFC_Obj02_OrientationYaw RFC_Obj02_ExistProb RFC_Obj02_VxVnce RFC_Obj02_VyVnce RFC_Obj02_AxVnce RFC_Obj02_AyVnce RFC_Obj02_OrientationYawVnce RFC_Obj02_MovingObserved RFC_Obj02_MovingProbability RFC_Obj02_Length RFC_Obj02_Valid RFC_Obj02_LengthVnce RFC_Obj02_WidthVnce RFC_Obj02_Width RFC_Obj02_BehaviorType RFC_Obj02_ObstacleConf RFC_Obj02_NonObstacleConf RFC_Obj02_PxPyCoVnce RFC_Obj02_PxVxCoVnce RFC_Obj02_PxVyCoVnce RFC_Obj02_PyVxCoVnce RFC_Obj02_PyVyCoVnce RFC_Obj02_VxVyCoVnce RFC_Obj02_PxAxCoVnce RFC_Obj02_PxAyCoVnce RFC_Obj02_PyAxCoVnce RFC_Obj02_PyAyCoVnce RFC_Obj02_VxAxCoVnce RFC_Obj02_VxAyCoVnce RFC_Obj02_VyAxCoVnce RFC_Obj02_VyAyCoVnce RFC_Obj02_AxAyCoVnce RFC_Obj02_MobileObstConf RFC_Obj02_Mob4PlusWhlConf RFC_Obj02_Mob2WhlConf RFC_Obj02_MobPedConf RFC_Obj02_FourPlusWhlCarConf RFC_Obj02_FourPlusWhlHGVConf RFC_Obj02_GroundReflexConf RFC_Obj02_StatObstConf RFC_Obj02_StatBarrierConf;
SIG_GROUP_ 409 SG_RFC_Obj03 1 : RFC_Obj03_CRC RFC_Obj03_AliveCtr RFC_Obj03_ProtBlockCtr RFC_Obj03_ReferencePoint RFC_Obj03_ObjId RFC_Obj03_MeasurementStatus RFC_Obj03_Px RFC_Obj03_Py RFC_Obj03_PxVnce RFC_Obj03_PyVnce RFC_Obj03_Vx RFC_Obj03_Vy RFC_Obj03_Ax RFC_Obj03_Ay RFC_Obj03_OrientationYaw RFC_Obj03_ExistProb RFC_Obj03_VxVnce RFC_Obj03_VyVnce RFC_Obj03_AxVnce RFC_Obj03_AyVnce RFC_Obj03_OrientationYawVnce RFC_Obj03_MovingObserved RFC_Obj03_MovingProbability RFC_Obj03_Length RFC_Obj03_Valid RFC_Obj03_LengthVnce RFC_Obj03_WidthVnce RFC_Obj03_Width RFC_Obj03_BehaviorType RFC_Obj03_ObstacleConf RFC_Obj03_NonObstacleConf RFC_Obj03_PxPyCoVnce RFC_Obj03_PxVxCoVnce RFC_Obj03_PxVyCoVnce RFC_Obj03_PyVxCoVnce RFC_Obj03_PyVyCoVnce RFC_Obj03_VxVyCoVnce RFC_Obj03_PxAxCoVnce RFC_Obj03_PxAyCoVnce RFC_Obj03_PyAxCoVnce RFC_Obj03_PyAyCoVnce RFC_Obj03_VxAxCoVnce RFC_Obj03_VxAyCoVnce RFC_Obj03_VyAxCoVnce RFC_Obj03_VyAyCoVnce RFC_Obj03_AxAyCoVnce RFC_Obj03_MobileObstConf RFC_Obj03_Mob4PlusWhlConf RFC_Obj03_Mob2WhlConf RFC_Obj03_MobPedConf RFC_Obj03_FourPlusWhlCarConf RFC_Obj03_FourPlusWhlHGVConf RFC_Obj03_GroundReflexConf RFC_Obj03_StatObstConf RFC_Obj03_StatBarrierConf;
SIG_GROUP_ 410 SG_RFC_Obj04 1 : RFC_Obj04_CRC RFC_Obj04_AliveCtr RFC_Obj04_ProtBlockCtr RFC_Obj04_ReferencePoint RFC_Obj04_ObjId RFC_Obj04_MeasurementStatus RFC_Obj04_Px RFC_Obj04_Py RFC_Obj04_PxVnce RFC_Obj04_PyVnce RFC_Obj04_Vx RFC_Obj04_Vy RFC_Obj04_Ax RFC_Obj04_Ay RFC_Obj04_OrientationYaw RFC_Obj04_ExistProb RFC_Obj04_VxVnce RFC_Obj04_VyVnce RFC_Obj04_AxVnce RFC_Obj04_AyVnce RFC_Obj04_OrientationYawVnce RFC_Obj04_MovingObserved RFC_Obj04_MovingProbability RFC_Obj04_Length RFC_Obj04_Valid RFC_Obj04_LengthVnce RFC_Obj04_WidthVnce RFC_Obj04_Width RFC_Obj04_BehaviorType RFC_Obj04_ObstacleConf RFC_Obj04_NonObstacleConf RFC_Obj04_PxPyCoVnce RFC_Obj04_PxVxCoVnce RFC_Obj04_PxVyCoVnce RFC_Obj04_PyVxCoVnce RFC_Obj04_PyVyCoVnce RFC_Obj04_VxVyCoVnce RFC_Obj04_PxAxCoVnce RFC_Obj04_PxAyCoVnce RFC_Obj04_PyAxCoVnce RFC_Obj04_PyAyCoVnce RFC_Obj04_VxAxCoVnce RFC_Obj04_VxAyCoVnce RFC_Obj04_VyAxCoVnce RFC_Obj04_VyAyCoVnce RFC_Obj04_AxAyCoVnce RFC_Obj04_MobileObstConf RFC_Obj04_Mob4PlusWhlConf RFC_Obj04_Mob2WhlConf RFC_Obj04_MobPedConf RFC_Obj04_FourPlusWhlCarConf RFC_Obj04_FourPlusWhlHGVConf RFC_Obj04_GroundReflexConf RFC_Obj04_StatObstConf RFC_Obj04_StatBarrierConf;
SIG_GROUP_ 411 SG_RFC_Obj05 1 : RFC_Obj05_CRC RFC_Obj05_AliveCtr RFC_Obj05_ProtBlockCtr RFC_Obj05_ReferencePoint RFC_Obj05_ObjId RFC_Obj05_MeasurementStatus RFC_Obj05_Px RFC_Obj05_Py RFC_Obj05_PxVnce RFC_Obj05_PyVnce RFC_Obj05_Vx RFC_Obj05_Vy RFC_Obj05_Ax RFC_Obj05_Ay RFC_Obj05_OrientationYaw RFC_Obj05_ExistProb RFC_Obj05_VxVnce RFC_Obj05_VyVnce RFC_Obj05_AxVnce RFC_Obj05_AyVnce RFC_Obj05_OrientationYawVnce RFC_Obj05_MovingObserved RFC_Obj05_MovingProbability RFC_Obj05_Length RFC_Obj05_Valid RFC_Obj05_LengthVnce RFC_Obj05_WidthVnce RFC_Obj05_Width RFC_Obj05_BehaviorType RFC_Obj05_ObstacleConf RFC_Obj05_NonObstacleConf RFC_Obj05_PxPyCoVnce RFC_Obj05_PxVxCoVnce RFC_Obj05_PxVyCoVnce RFC_Obj05_PyVxCoVnce RFC_Obj05_PyVyCoVnce RFC_Obj05_VxVyCoVnce RFC_Obj05_PxAxCoVnce RFC_Obj05_PxAyCoVnce RFC_Obj05_PyAxCoVnce RFC_Obj05_PyAyCoVnce RFC_Obj05_VxAxCoVnce RFC_Obj05_VxAyCoVnce RFC_Obj05_VyAxCoVnce RFC_Obj05_VyAyCoVnce RFC_Obj05_AxAyCoVnce RFC_Obj05_MobileObstConf RFC_Obj05_Mob4PlusWhlConf RFC_Obj05_Mob2WhlConf RFC_Obj05_MobPedConf RFC_Obj05_FourPlusWhlCarConf RFC_Obj05_FourPlusWhlHGVConf RFC_Obj05_GroundReflexConf RFC_Obj05_StatObstConf RFC_Obj05_StatBarrierConf;
SIG_GROUP_ 412 SG_RFC_Obj06 1 : RFC_Obj06_CRC RFC_Obj06_AliveCtr RFC_Obj06_ProtBlockCtr RFC_Obj06_ReferencePoint RFC_Obj06_ObjId RFC_Obj06_MeasurementStatus RFC_Obj06_Px RFC_Obj06_Py RFC_Obj06_PxVnce RFC_Obj06_PyVnce RFC_Obj06_Vx RFC_Obj06_Vy RFC_Obj06_Ax RFC_Obj06_Ay RFC_Obj06_OrientationYaw RFC_Obj06_ExistProb RFC_Obj06_VxVnce RFC_Obj06_VyVnce RFC_Obj06_AxVnce RFC_Obj06_AyVnce RFC_Obj06_OrientationYawVnce RFC_Obj06_MovingObserved RFC_Obj06_MovingProbability RFC_Obj06_Length RFC_Obj06_Valid RFC_Obj06_LengthVnce RFC_Obj06_WidthVnce RFC_Obj06_Width RFC_Obj06_BehaviorType RFC_Obj06_ObstacleConf RFC_Obj06_NonObstacleConf RFC_Obj06_PxPyCoVnce RFC_Obj06_PxVxCoVnce RFC_Obj06_PxVyCoVnce RFC_Obj06_PyVxCoVnce RFC_Obj06_PyVyCoVnce RFC_Obj06_VxVyCoVnce RFC_Obj06_PxAxCoVnce RFC_Obj06_PxAyCoVnce RFC_Obj06_PyAxCoVnce RFC_Obj06_PyAyCoVnce RFC_Obj06_VxAxCoVnce RFC_Obj06_VxAyCoVnce RFC_Obj06_VyAxCoVnce RFC_Obj06_VyAyCoVnce RFC_Obj06_AxAyCoVnce RFC_Obj06_MobileObstConf RFC_Obj06_Mob4PlusWhlConf RFC_Obj06_Mob2WhlConf RFC_Obj06_MobPedConf RFC_Obj06_FourPlusWhlCarConf RFC_Obj06_FourPlusWhlHGVConf RFC_Obj06_GroundReflexConf RFC_Obj06_StatObstConf RFC_Obj06_StatBarrierConf;
SIG_GROUP_ 413 SG_RFC_Obj07 1 : RFC_Obj07_CRC RFC_Obj07_AliveCtr RFC_Obj07_ProtBlockCtr RFC_Obj07_ReferencePoint RFC_Obj07_ObjId RFC_Obj07_MeasurementStatus RFC_Obj07_Px RFC_Obj07_Py RFC_Obj07_PxVnce RFC_Obj07_PyVnce RFC_Obj07_Vx RFC_Obj07_Vy RFC_Obj07_Ax RFC_Obj07_Ay RFC_Obj07_OrientationYaw RFC_Obj07_ExistProb RFC_Obj07_VxVnce RFC_Obj07_VyVnce RFC_Obj07_AxVnce RFC_Obj07_AyVnce RFC_Obj07_OrientationYawVnce RFC_Obj07_MovingObserved RFC_Obj07_MovingProbability RFC_Obj07_Length RFC_Obj07_Valid RFC_Obj07_LengthVnce RFC_Obj07_WidthVnce RFC_Obj07_Width RFC_Obj07_BehaviorType RFC_Obj07_ObstacleConf RFC_Obj07_NonObstacleConf RFC_Obj07_PxPyCoVnce RFC_Obj07_PxVxCoVnce RFC_Obj07_PxVyCoVnce RFC_Obj07_PyVxCoVnce RFC_Obj07_PyVyCoVnce RFC_Obj07_VxVyCoVnce RFC_Obj07_PxAxCoVnce RFC_Obj07_PxAyCoVnce RFC_Obj07_PyAxCoVnce RFC_Obj07_PyAyCoVnce RFC_Obj07_VxAxCoVnce RFC_Obj07_VxAyCoVnce RFC_Obj07_VyAxCoVnce RFC_Obj07_VyAyCoVnce RFC_Obj07_AxAyCoVnce RFC_Obj07_MobileObstConf RFC_Obj07_Mob4PlusWhlConf RFC_Obj07_Mob2WhlConf RFC_Obj07_MobPedConf RFC_Obj07_FourPlusWhlCarConf RFC_Obj07_FourPlusWhlHGVConf RFC_Obj07_GroundReflexConf RFC_Obj07_StatObstConf RFC_Obj07_StatBarrierConf;
SIG_GROUP_ 414 SG_RFC_Obj08 1 : RFC_Obj08_CRC RFC_Obj08_AliveCtr RFC_Obj08_ProtBlockCtr RFC_Obj08_ReferencePoint RFC_Obj08_ObjId RFC_Obj08_MeasurementStatus RFC_Obj08_Px RFC_Obj08_Py RFC_Obj08_PxVnce RFC_Obj08_PyVnce RFC_Obj08_Vx RFC_Obj08_Vy RFC_Obj08_Ax RFC_Obj08_Ay RFC_Obj08_OrientationYaw RFC_Obj08_ExistProb RFC_Obj08_VxVnce RFC_Obj08_VyVnce RFC_Obj08_AxVnce RFC_Obj08_AyVnce RFC_Obj08_OrientationYawVnce RFC_Obj08_MovingObserved RFC_Obj08_MovingProbability RFC_Obj08_Length RFC_Obj08_Valid RFC_Obj08_LengthVnce RFC_Obj08_WidthVnce RFC_Obj08_Width RFC_Obj08_BehaviorType RFC_Obj08_ObstacleConf RFC_Obj08_NonObstacleConf RFC_Obj08_PxPyCoVnce RFC_Obj08_PxVxCoVnce RFC_Obj08_PxVyCoVnce RFC_Obj08_PyVxCoVnce RFC_Obj08_PyVyCoVnce RFC_Obj08_VxVyCoVnce RFC_Obj08_PxAxCoVnce RFC_Obj08_PxAyCoVnce RFC_Obj08_PyAxCoVnce RFC_Obj08_PyAyCoVnce RFC_Obj08_VxAxCoVnce RFC_Obj08_VxAyCoVnce RFC_Obj08_VyAxCoVnce RFC_Obj08_VyAyCoVnce RFC_Obj08_AxAyCoVnce RFC_Obj08_MobileObstConf RFC_Obj08_Mob4PlusWhlConf RFC_Obj08_Mob2WhlConf RFC_Obj08_MobPedConf RFC_Obj08_FourPlusWhlCarConf RFC_Obj08_FourPlusWhlHGVConf RFC_Obj08_GroundReflexConf RFC_Obj08_StatObstConf RFC_Obj08_StatBarrierConf;
SIG_GROUP_ 415 SG_RFC_Obj09 1 : RFC_Obj09_CRC RFC_Obj09_AliveCtr RFC_Obj09_ProtBlockCtr RFC_Obj09_ReferencePoint RFC_Obj09_ObjId RFC_Obj09_MeasurementStatus RFC_Obj09_Px RFC_Obj09_Py RFC_Obj09_PxVnce RFC_Obj09_PyVnce RFC_Obj09_Vx RFC_Obj09_Vy RFC_Obj09_Ax RFC_Obj09_Ay RFC_Obj09_OrientationYaw RFC_Obj09_ExistProb RFC_Obj09_VxVnce RFC_Obj09_VyVnce RFC_Obj09_AxVnce RFC_Obj09_AyVnce RFC_Obj09_OrientationYawVnce RFC_Obj09_MovingObserved RFC_Obj09_MovingProbability RFC_Obj09_Length RFC_Obj09_Valid RFC_Obj09_LengthVnce RFC_Obj09_WidthVnce RFC_Obj09_Width RFC_Obj09_BehaviorType RFC_Obj09_ObstacleConf RFC_Obj09_NonObstacleConf RFC_Obj09_PxPyCoVnce RFC_Obj09_PxVxCoVnce RFC_Obj09_PxVyCoVnce RFC_Obj09_PyVxCoVnce RFC_Obj09_PyVyCoVnce RFC_Obj09_VxVyCoVnce RFC_Obj09_PxAxCoVnce RFC_Obj09_PxAyCoVnce RFC_Obj09_PyAxCoVnce RFC_Obj09_PyAyCoVnce RFC_Obj09_VxAxCoVnce RFC_Obj09_VxAyCoVnce RFC_Obj09_VyAxCoVnce RFC_Obj09_VyAyCoVnce RFC_Obj09_AxAyCoVnce RFC_Obj09_MobileObstConf RFC_Obj09_Mob4PlusWhlConf RFC_Obj09_Mob2WhlConf RFC_Obj09_MobPedConf RFC_Obj09_FourPlusWhlCarConf RFC_Obj09_FourPlusWhlHGVConf RFC_Obj09_GroundReflexConf RFC_Obj09_StatObstConf RFC_Obj09_StatBarrierConf;
SIG_GROUP_ 416 SG_RFC_Obj10 1 : RFC_Obj10_CRC RFC_Obj10_AliveCtr RFC_Obj10_ProtBlockCtr RFC_Obj10_ReferencePoint RFC_Obj10_ObjId RFC_Obj10_MeasurementStatus RFC_Obj10_Px RFC_Obj10_Py RFC_Obj10_PxVnce RFC_Obj10_PyVnce RFC_Obj10_Vx RFC_Obj10_Vy RFC_Obj10_Ax RFC_Obj10_Ay RFC_Obj10_OrientationYaw RFC_Obj10_ExistProb RFC_Obj10_VxVnce RFC_Obj10_VyVnce RFC_Obj10_AxVnce RFC_Obj10_AyVnce RFC_Obj10_OrientationYawVnce RFC_Obj10_MovingObserved RFC_Obj10_MovingProbability RFC_Obj10_Length RFC_Obj10_Valid RFC_Obj10_LengthVnce RFC_Obj10_WidthVnce RFC_Obj10_Width RFC_Obj10_BehaviorType RFC_Obj10_ObstacleConf RFC_Obj10_NonObstacleConf RFC_Obj10_PxPyCoVnce RFC_Obj10_PxVxCoVnce RFC_Obj10_PxVyCoVnce RFC_Obj10_PyVxCoVnce RFC_Obj10_PyVyCoVnce RFC_Obj10_VxVyCoVnce RFC_Obj10_PxAxCoVnce RFC_Obj10_PxAyCoVnce RFC_Obj10_PyAxCoVnce RFC_Obj10_PyAyCoVnce RFC_Obj10_VxAxCoVnce RFC_Obj10_VxAyCoVnce RFC_Obj10_VyAxCoVnce RFC_Obj10_VyAyCoVnce RFC_Obj10_AxAyCoVnce RFC_Obj10_MobileObstConf RFC_Obj10_Mob4PlusWhlConf RFC_Obj10_Mob2WhlConf RFC_Obj10_MobPedConf RFC_Obj10_FourPlusWhlCarConf RFC_Obj10_FourPlusWhlHGVConf RFC_Obj10_GroundReflexConf RFC_Obj10_StatObstConf RFC_Obj10_StatBarrierConf;
SIG_GROUP_ 417 SG_RFC_Obj11 1 : RFC_Obj11_CRC RFC_Obj11_AliveCtr RFC_Obj11_ProtBlockCtr RFC_Obj11_ReferencePoint RFC_Obj11_ObjId RFC_Obj11_MeasurementStatus RFC_Obj11_Px RFC_Obj11_Py RFC_Obj11_PxVnce RFC_Obj11_PyVnce RFC_Obj11_Vx RFC_Obj11_Vy RFC_Obj11_Ax RFC_Obj11_Ay RFC_Obj11_OrientationYaw RFC_Obj11_ExistProb RFC_Obj11_VxVnce RFC_Obj11_VyVnce RFC_Obj11_AxVnce RFC_Obj11_AyVnce RFC_Obj11_OrientationYawVnce RFC_Obj11_MovingObserved RFC_Obj11_MovingProbability RFC_Obj11_Length RFC_Obj11_Valid RFC_Obj11_LengthVnce RFC_Obj11_WidthVnce RFC_Obj11_Width RFC_Obj11_BehaviorType RFC_Obj11_ObstacleConf RFC_Obj11_NonObstacleConf RFC_Obj11_PxPyCoVnce RFC_Obj11_PxVxCoVnce RFC_Obj11_PxVyCoVnce RFC_Obj11_PyVxCoVnce RFC_Obj11_PyVyCoVnce RFC_Obj11_VxVyCoVnce RFC_Obj11_PxAxCoVnce RFC_Obj11_PxAyCoVnce RFC_Obj11_PyAxCoVnce RFC_Obj11_PyAyCoVnce RFC_Obj11_VxAxCoVnce RFC_Obj11_VxAyCoVnce RFC_Obj11_VyAxCoVnce RFC_Obj11_VyAyCoVnce RFC_Obj11_AxAyCoVnce RFC_Obj11_MobileObstConf RFC_Obj11_Mob4PlusWhlConf RFC_Obj11_Mob2WhlConf RFC_Obj11_MobPedConf RFC_Obj11_FourPlusWhlCarConf RFC_Obj11_FourPlusWhlHGVConf RFC_Obj11_GroundReflexConf RFC_Obj11_StatObstConf RFC_Obj11_StatBarrierConf;
